VERSION "ICM"

NS_ :

BS_ :

BU_ : ICM Vector_XXX

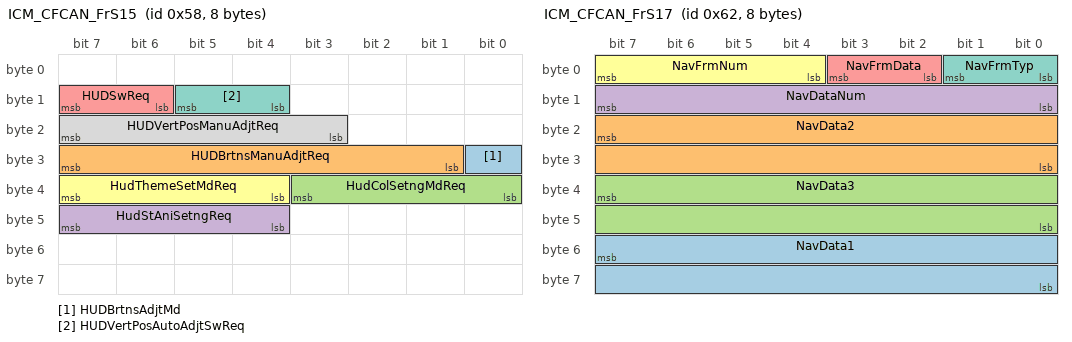
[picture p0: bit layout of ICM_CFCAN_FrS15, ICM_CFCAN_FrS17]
BO_ 88 ICM_CFCAN_FrS15 : 8 ICM
 SG_ HUDBrtnsAdjtMd : 24|1@0+ (1,0) [0|1] "" Vector_XXX
 SG_ HUDBrtnsManuAdjtReq : 31|7@0+ (1,0) [0|127] "" Vector_XXX
 SG_ HudColSetngMdReq : 35|4@0+ (1,0) [0|15] "" Vector_XXX
 SG_ HudStAniSetngReq : 47|4@0+ (1,0) [0|15] "" Vector_XXX
 SG_ HUDSwReq : 15|2@0+ (1,0) [0|3] "" Vector_XXX
 SG_ HudThemeSetMdReq : 39|4@0+ (1,0) [0|15] "" Vector_XXX
 SG_ HUDVertPosAutoAdjtSwReq : 13|2@0+ (1,0) [0|3] "" Vector_XXX
 SG_ HUDVertPosManuAdjtReq : 23|5@0+ (1,0) [0|31] "" Vector_XXX

BO_ 98 ICM_CFCAN_FrS17 : 8 ICM
 SG_ NavData1 : 55|16@0+ (1.0,0.0) [0.0|65535.0] "" Vector_XXX
 SG_ NavData2 : 23|16@0+ (1.0,0.0) [0.0|65535.0] "" Vector_XXX
 SG_ NavData3 : 39|16@0+ (1.0,0.0) [0.0|65535.0] "" Vector_XXX
 SG_ NavDataNum : 15|8@0+ (1,0) [0|255] "" Vector_XXX
 SG_ NavFrmData : 3|2@0+ (1,0) [0|3] "" Vector_XXX
 SG_ NavFrmNum : 7|4@0+ (1,0) [0|15] "" Vector_XXX
 SG_ NavFrmTyp : 1|2@0+ (1,0) [0|3] "" Vector_XXX

BO_ 1218 ICM_CFCAN_NM : 8 ICM
 SG_ NmPDU_CFCAN_ICM : 7|64@0+ (1,0) [0|0] "" Vector_XXX

BO_ 1142 IPK_CFCAN_FrP01 : 8 ICM
 SG_ VINClstr : 7|64@0+ (1,0) [0|18446744073709551615] "" Vector_XXX

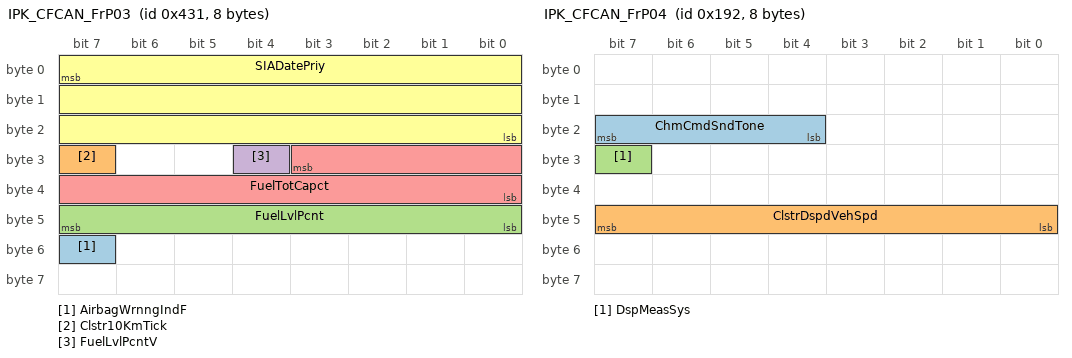
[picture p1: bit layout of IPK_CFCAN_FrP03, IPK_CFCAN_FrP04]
BO_ 1073 IPK_CFCAN_FrP03 : 8 ICM
 SG_ AirbagWrnngIndF : 55|1@0+ (1,0) [0|1] "" Vector_XXX
 SG_ Clstr10KmTick : 31|1@0+ (1,0) [0|1] "" Vector_XXX
 SG_ FuelLvlPcnt : 47|8@0+ (0.392157,0.0) [0.0|100.000035] "%" Vector_XXX
 SG_ FuelLvlPcntV : 28|1@0+ (1,0) [0|1] "" Vector_XXX
 SG_ FuelTotCapct : 27|12@0+ (0.125,0.0) [0.0|511.875] "liters" Vector_XXX
 SG_ SIADatePriy : 7|24@0+ (1.0,0.0) [0.0|0.0] "" Vector_XXX

BO_ 402 IPK_CFCAN_FrP04 : 8 ICM
 SG_ ChmCmdSndTone : 23|4@0+ (1,0) [0|15] "" Vector_XXX
 SG_ ClstrDspdVehSpd : 47|8@0+ (1.0,0.0) [0.0|254.0] "km/h" Vector_XXX
 SG_ DspMeasSys : 31|1@0+ (1,0) [0|1] "" Vector_XXX

BO_ 1134 IPK_CFCAN_FrP05 : 8 ICM
 SG_ OdoPriy : 23|24@0+ (1.0,0.0) [0.0|16777200.0] "km" Vector_XXX
 SG_ SIAOdoPriy : 47|24@0+ (1.0,0.0) [0.0|16777200.0] "km" Vector_XXX

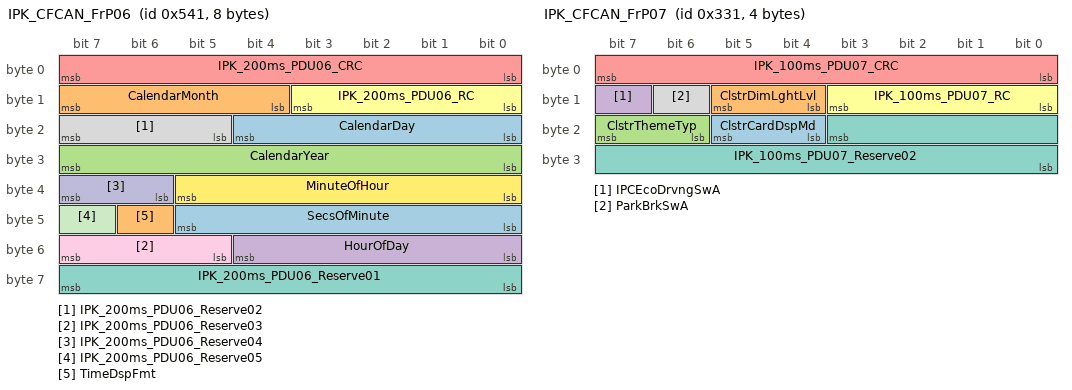
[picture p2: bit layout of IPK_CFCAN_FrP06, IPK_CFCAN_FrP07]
BO_ 1345 IPK_CFCAN_FrP06 : 8 ICM
 SG_ CalendarDay : 20|5@0+ (1.0,0.0) [0.0|31.0] "days" Vector_XXX
 SG_ CalendarMonth : 15|4@0+ (1,0) [0|15] "" Vector_XXX
 SG_ CalendarYear : 31|8@0+ (1.0,2000.0) [2000.0|2255.0] "year" Vector_XXX
 SG_ HourOfDay : 52|5@0+ (1.0,0.0) [0.0|23.0] "" Vector_XXX
 SG_ IPK_200ms_PDU06_CRC : 7|8@0+ (1.0,0.0) [0.0|255.0] "" Vector_XXX
 SG_ IPK_200ms_PDU06_RC : 11|4@0+ (1.0,0.0) [0.0|15.0] "" Vector_XXX
 SG_ IPK_200ms_PDU06_Reserve01 : 63|8@0+ (1,0) [0|255] "" Vector_XXX
 SG_ IPK_200ms_PDU06_Reserve02 : 23|3@0+ (1,0) [0|7] "" Vector_XXX
 SG_ IPK_200ms_PDU06_Reserve03 : 55|3@0+ (1,0) [0|7] "" Vector_XXX
 SG_ IPK_200ms_PDU06_Reserve04 : 39|2@0+ (1,0) [0|3] "" Vector_XXX
 SG_ IPK_200ms_PDU06_Reserve05 : 47|1@0+ (1,0) [0|1] "" Vector_XXX
 SG_ MinuteOfHour : 37|6@0+ (1.0,0.0) [0.0|59.0] "" Vector_XXX
 SG_ SecsOfMinute : 45|6@0+ (1.0,0.0) [0.0|59.0] "" Vector_XXX
 SG_ TimeDspFmt : 46|1@0+ (1,0) [0|1] "" Vector_XXX

BO_ 817 IPK_CFCAN_FrP07 : 4 ICM
 SG_ ClstrCardDspMd : 21|2@0+ (1,0) [0|3] "" Vector_XXX
 SG_ ClstrDimLghtLvl : 13|2@0+ (1,0) [0|3] "" Vector_XXX
 SG_ ClstrThemeTyp : 23|2@0+ (1,0) [0|3] "" Vector_XXX
 SG_ IPCEcoDrvngSwA : 15|1@0+ (1,0) [0|1] "" Vector_XXX
 SG_ IPK_100ms_PDU07_CRC : 7|8@0+ (1.0,0.0) [0.0|255.0] "" Vector_XXX
 SG_ IPK_100ms_PDU07_RC : 11|4@0+ (1.0,0.0) [0.0|15.0] "" Vector_XXX
 SG_ IPK_100ms_PDU07_Reserve02 : 19|12@0+ (1,0) [0|4095] "" Vector_XXX
 SG_ ParkBrkSwA : 14|1@0+ (1,0) [0|1] "" Vector_XXX

BO_ 874 IPK_CFCAN_FrP08 : 8 ICM
 SG_ RmnDrvngDist : 39|12@0+ (1.0,0.0) [0.0|4095.0] "km" Vector_XXX

BO_ 1047 IPK_CFCAN_FrP09 : 8 ICM
 SG_ ClstrDspdABSWrnng : 41|1@0+ (1,0) [0|1] "" Vector_XXX
 SG_ ClstrDspdACCSysWrnng : 6|1@0+ (1,0) [0|1] "" Vector_XXX
 SG_ ClstrDspdAdvFrtLghtngSysWrnng : 54|1@0+ (1,0) [0|1] "" Vector_XXX
 SG_ ClstrDspdAEBSysWrnng : 38|1@0+ (1,0) [0|1] "" Vector_XXX
 SG_ ClstrDspdAirbagWrnng : 27|1@0+ (1,0) [0|1] "" Vector_XXX
 SG_ ClstrDspdAltrWrnng : 36|1@0+ (1,0) [0|1] "" Vector_XXX
 SG_ ClstrDspdAutoholdWrnng : 2|1@0+ (1,0) [0|1] "" Vector_XXX
 SG_ ClstrDspdBatRplmntRqdWrnng : 18|1@0+ (1,0) [0|1] "" Vector_XXX
 SG_ ClstrDspdBrkSysWrnng : 43|1@0+ (1,0) [0|1] "" Vector_XXX
 SG_ ClstrDspdCCWrnng : 11|1@0+ (1,0) [0|1] "" Vector_XXX
 SG_ ClstrDspdClntTemWrnng : 42|1@0+ (1,0) [0|1] "" Vector_XXX
 SG_ ClstrDspdClSwWrnng : 30|1@0+ (1,0) [0|1] "" Vector_XXX
 SG_ ClstrDspdDayTimeRunningLampWrnng : 15|1@0+ (1,0) [0|1] "" Vector_XXX
 SG_ ClstrDspdEleccParkngBrkWrnng : 10|1@0+ (1,0) [0|1] "" Vector_XXX
 SG_ ClstrDspdEnDrvByWrWrnng : 9|1@0+ (1,0) [0|1] "" Vector_XXX
 SG_ ClstrDspdEPSWrnng : 57|2@0+ (1,0) [0|3] "" Vector_XXX
 SG_ ClstrDspdFuelSnsrWrnng : 47|1@0+ (1,0) [0|1] "" Vector_XXX
 SG_ ClstrDspdFVCMSnsrWrnng : 7|1@0+ (1,0) [0|1] "" Vector_XXX
 SG_ ClstrDspdHDCWrnng : 39|1@0+ (1,0) [0|1] "" Vector_XXX
 SG_ ClstrDspdHillHoldWrnng : 31|1@0+ (1,0) [0|1] "" Vector_XXX
 SG_ ClstrDspdIgnRelayWrnng : 16|1@0+ (1,0) [0|1] "" Vector_XXX
 SG_ ClstrDspdInvdKeyWrnng : 28|1@0+ (1,0) [0|1] "" Vector_XXX
 SG_ ClstrDspdLBrkLghtWrnng : 48|1@0+ (1,0) [0|1] "" Vector_XXX
 SG_ ClstrDspdLDipdBeamLghtWrnng : 52|1@0+ (1,0) [0|1] "" Vector_XXX
 SG_ ClstrDspdLDircnIndLghtWrnng : 50|1@0+ (1,0) [0|1] "" Vector_XXX
 SG_ ClstrDspdLDWSysFlt : 5|1@0+ (1,0) [0|1] "" Vector_XXX
 SG_ ClstrDspdLSideLghtWrnng : 13|1@0+ (1,0) [0|1] "" Vector_XXX
 SG_ ClstrDspdPEWrnng : 4|1@0+ (1,0) [0|1] "" Vector_XXX
 SG_ ClstrDspdRBrkLghtWrnng : 49|1@0+ (1,0) [0|1] "" Vector_XXX
 SG_ ClstrDspdRDipdBeamLghtWrnng : 53|1@0+ (1,0) [0|1] "" Vector_XXX
 SG_ ClstrDspdRDircnIndLghtWrnng : 51|1@0+ (1,0) [0|1] "" Vector_XXX
 SG_ ClstrDspdRevsLampWrnng : 1|1@0+ (1,0) [0|1] "" Vector_XXX
 SG_ ClstrDspdRrFogLghtWrnng : 0|1@0+ (1,0) [0|1] "" Vector_XXX
 SG_ ClstrDspdRSideLghtWrnng : 14|1@0+ (1,0) [0|1] "" Vector_XXX
 SG_ ClstrDspdSASUncalWrnng : 26|1@0+ (1,0) [0|1] "" Vector_XXX
 SG_ ClstrDspdSASWrnng : 25|1@0+ (1,0) [0|1] "" Vector_XXX
 SG_ ClstrDspdSCSWrnng : 55|1@0+ (1,0) [0|1] "" Vector_XXX
 SG_ ClstrDspdScurtKeyBatLowWrnng : 29|1@0+ (1,0) [0|1] "" Vector_XXX
 SG_ ClstrDspdSpdAstSysWrnng : 12|1@0+ (1,0) [0|1] "" Vector_XXX
 SG_ ClstrDspdSpStBtnWrnng : 33|1@0+ (1,0) [0|1] "" Vector_XXX
 SG_ ClstrDspdSpStWrnng : 32|1@0+ (1,0) [0|1] "" Vector_XXX
 SG_ ClstrDspdTCCMWrnng : 3|1@0+ (1,0) [0|1] "" Vector_XXX
 SG_ ClstrDspdTCSWrnng : 40|1@0+ (1,0) [0|1] "" Vector_XXX
 SG_ ClstrDspdTrWrnng : 22|1@0+ (1,0) [0|1] "" Vector_XXX
 SG_ ClstrDspdTyrePrsSts : 35|2@0+ (1,0) [0|3] "" Vector_XXX
 SG_ ClstrDspdWshrFludLowWrnng : 17|1@0+ (1,0) [0|1] "" Vector_XXX

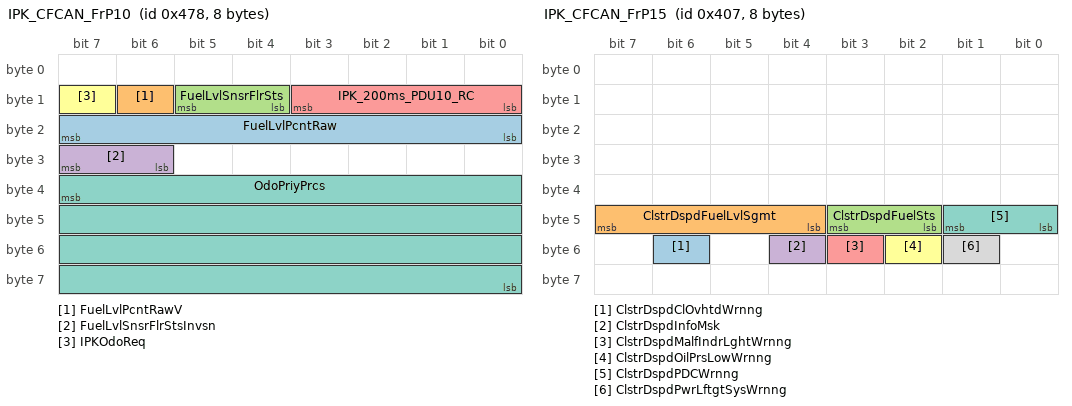
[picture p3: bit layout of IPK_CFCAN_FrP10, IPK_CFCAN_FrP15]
BO_ 1144 IPK_CFCAN_FrP10 : 8 ICM
 SG_ FuelLvlPcntRaw : 23|8@0+ (0.392157,0.0) [0.0|100.000035] "%" Vector_XXX
 SG_ FuelLvlPcntRawV : 14|1@0+ (1,0) [0|1] "" Vector_XXX
 SG_ FuelLvlSnsrFlrSts : 13|2@0+ (1,0) [0|3] "" Vector_XXX
 SG_ FuelLvlSnsrFlrStsInvsn : 31|2@0+ (1,0) [0|3] "" Vector_XXX
 SG_ IPK_200ms_PDU10_RC : 11|4@0+ (1.0,0.0) [0.0|15.0] "" Vector_XXX
 SG_ IPKOdoReq : 15|1@0+ (1,0) [0|1] "" Vector_XXX
 SG_ OdoPriyPrcs : 39|32@0+ (0.1,0.0) [0.0|429496729.5] "km" Vector_XXX

BO_ 1031 IPK_CFCAN_FrP15 : 8 ICM
 SG_ ClstrDspdClOvhtdWrnng : 54|1@0+ (1,0) [0|1] "" Vector_XXX
 SG_ ClstrDspdFuelLvlSgmt : 47|4@0+ (1.0,0.0) [9.0|15.0] "Reserved" Vector_XXX
 SG_ ClstrDspdFuelSts : 43|2@0+ (1,0) [0|3] "" Vector_XXX
 SG_ ClstrDspdInfoMsk : 52|1@0+ (1,0) [0|1] "" Vector_XXX
 SG_ ClstrDspdMalfIndrLghtWrnng : 51|1@0+ (1,0) [0|1] "" Vector_XXX
 SG_ ClstrDspdOilPrsLowWrnng : 50|1@0+ (1,0) [0|1] "" Vector_XXX
 SG_ ClstrDspdPDCWrnng : 41|2@0+ (1,0) [0|3] "" Vector_XXX
 SG_ ClstrDspdPwrLftgtSysWrnng : 49|1@0+ (1,0) [0|1] "" Vector_XXX

BO_ 1360 IPK_CFCAN_FrP17 : 8 ICM
 SG_ AvgFuelCsump : 7|8@0+ (0.1,0.0) [0.0|25.5] "L/100 km" Vector_XXX
 SG_ AvgFuelCsumpV : 8|1@0+ (1,0) [0|1] "" Vector_XXX
 SG_ ClstrFuelRngToEPT : 23|10@0+ (1.0,0.0) [0.0|1023.0] "" Vector_XXX

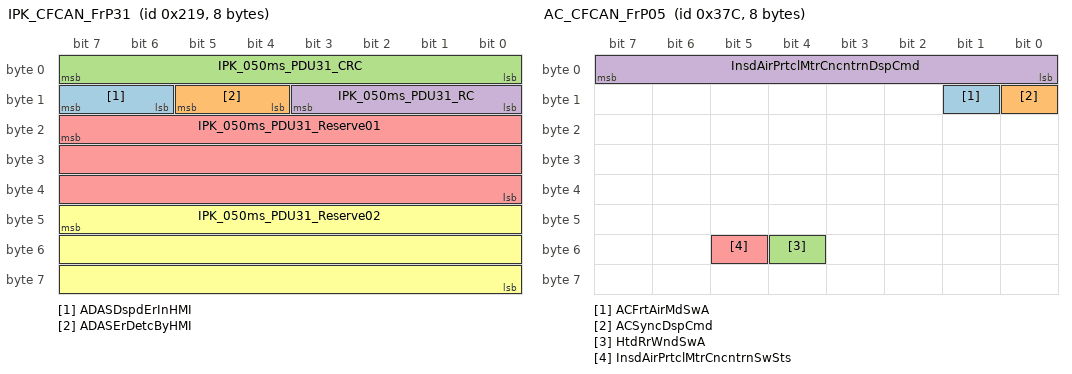
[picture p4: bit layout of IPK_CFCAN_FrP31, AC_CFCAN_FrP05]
BO_ 537 IPK_CFCAN_FrP31 : 8 ICM
 SG_ ADASDspdErInHMI : 15|2@0+ (1,0) [0|3] "" Vector_XXX
 SG_ ADASErDetcByHMI : 13|2@0+ (1,0) [0|3] "" Vector_XXX
 SG_ IPK_050ms_PDU31_CRC : 7|8@0+ (1.0,0.0) [0.0|255.0] "" Vector_XXX
 SG_ IPK_050ms_PDU31_RC : 11|4@0+ (1.0,0.0) [0.0|15.0] "" Vector_XXX
 SG_ IPK_050ms_PDU31_Reserve01 : 23|24@0+ (1,0) [0|16777215] "" Vector_XXX
 SG_ IPK_050ms_PDU31_Reserve02 : 47|24@0+ (1,0) [0|16777215] "" Vector_XXX

BO_ 672 AC_CFCAN_FrP04 : 8 Vector_XXX
 SG_ RrACAutoDspCmd : 19|1@0+ (1,0) [0|1] "" ICM
 SG_ RrACOnOffDspCmd : 17|1@0+ (1,0) [0|1] "" ICM

BO_ 892 AC_CFCAN_FrP05 : 8 Vector_XXX
 SG_ ACFrtAirMdSwA : 9|1@0+ (1,0) [0|1] "" ICM
 SG_ ACSyncDspCmd : 8|1@0+ (1,0) [0|1] "" ICM
 SG_ HtdRrWndSwA : 52|1@0+ (1,0) [0|1] "" ICM
 SG_ InsdAirPrtclMtrCncntrnDspCmd : 7|8@0+ (2.0,0.0) [0.0|500.0] "ug/m3" ICM
 SG_ InsdAirPrtclMtrCncntrnSwSts : 53|1@0+ (1,0) [0|1] "" ICM

BO_ 893 AC_CFCAN_FrP06 : 8 Vector_XXX
 SG_ ACFltrCsumLvlDspCmd : 39|2@0+ (1,0) [0|3] "" ICM
 SG_ ACUserCustAftRunOnOffDspCmd : 7|2@0+ (1,0) [0|3] "" ICM
 SG_ ACUserCustAirQultEnbDspCmd : 5|2@0+ (1,0) [0|3] "" ICM
 SG_ ACUserCustAutoMdBlwrDspCmd : 3|2@0+ (1,0) [0|3] "" ICM
 SG_ ACUserCustAutoMdTemDspCmd : 1|2@0+ (1,0) [0|3] "" ICM
 SG_ ACUserCustBlwrAutoRunRmtUnlckDspCmd : 15|2@0+ (1,0) [0|3] "" ICM
 SG_ ACUserCustCofignDspCmd : 13|3@0+ (1,0) [0|7] "" ICM
 SG_ ACUserCustEcoSetngDspCmd : 41|2@0+ (1,0) [0|3] "" ICM
 SG_ ACUserCustFltrLifeRmndDspCmd : 9|2@0+ (1,0) [0|3] "" ICM
 SG_ ACUserCustFrtAutoDmstngDspCmd : 23|2@0+ (1,0) [0|3] "" ICM
 SG_ ACUserCustRmtStOnOffDspCmd : 21|2@0+ (1,0) [0|3] "" ICM
 SG_ ACUserCustRrAutoDmstngDspCmd : 19|2@0+ (1,0) [0|3] "" ICM
 SG_ ACUserCustRrZoneCofignDspCmd : 17|2@0+ (1,0) [0|3] "" ICM
 SG_ ACUserCustSetngDspCmd : 25|2@0+ (1,0) [0|3] "" ICM
 SG_ ACUserCustStSpMdDspCmd : 31|2@0+ (1,0) [0|3] "" ICM
 SG_ ACUserCustTemUnitDspCmd : 29|2@0+ (1,0) [0|3] "" ICM
 SG_ ACUserCustZoneCofignDspCmd : 27|2@0+ (1,0) [0|3] "" ICM
 SG_ AirClnrAutoDspCmd : 55|1@0+ (1,0) [0|1] "" ICM
 SG_ AirClnrBlwrLvlDspCmd : 54|3@0+ (1,0) [0|7] "" ICM
 SG_ AirClnrBlwrSpdSwA : 10|1@0+ (1,0) [0|1] "" ICM
 SG_ AirClnrIonizerDspCmd : 46|1@0+ (1,0) [0|1] "" ICM
 SG_ AirClnrOnOffDspCmd : 47|1@0+ (1,0) [0|1] "" ICM
 SG_ AirClnrUserCustAutoRDC : 45|2@0+ (1,0) [0|3] "" ICM

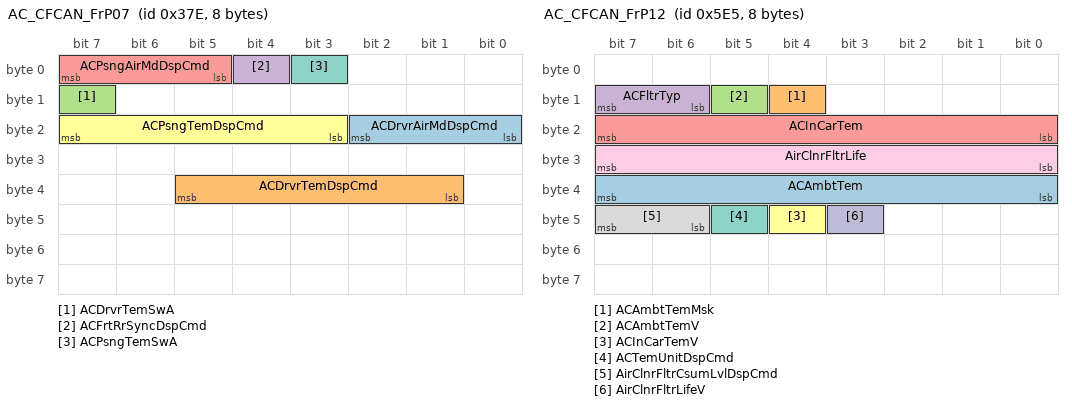
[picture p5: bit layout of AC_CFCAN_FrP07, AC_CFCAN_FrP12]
BO_ 894 AC_CFCAN_FrP07 : 8 Vector_XXX
 SG_ ACDrvrAirMdDspCmd : 18|3@0+ (1,0) [0|7] "" ICM
 SG_ ACDrvrTemDspCmd : 37|5@0+ (0.5,15.5) [16.0|30.0] "degC" ICM
 SG_ ACDrvrTemSwA : 15|1@0+ (1,0) [0|1] "" ICM
 SG_ ACFrtRrSyncDspCmd : 4|1@0+ (1,0) [0|1] "" ICM
 SG_ ACPsngAirMdDspCmd : 7|3@0+ (1,0) [0|7] "" ICM
 SG_ ACPsngTemDspCmd : 23|5@0+ (0.5,17.5) [18.0|32.0] "deg C" ICM
 SG_ ACPsngTemSwA : 3|1@0+ (1,0) [0|1] "" ICM

BO_ 936 AC_CFCAN_FrP10 : 8 Vector_XXX
 SG_ ACAutoDspCmd : 54|1@0+ (1,0) [0|1] "" ICM
 SG_ ACAutoSwA : 56|1@0+ (1,0) [0|1] "" ICM
 SG_ ACDualDspCmd : 53|1@0+ (1,0) [0|1] "" ICM
 SG_ ACEcoDspCmd : 51|1@0+ (1,0) [0|1] "" ICM
 SG_ ACFrtBlwrSpdDspCmd : 31|4@0+ (1,0) [0|15] "" ICM
 SG_ ACFrtBlwrSpdSwA : 48|1@0+ (1,0) [0|1] "" ICM
 SG_ ACFrtPnlLckRrPnlDspCmd : 44|1@0+ (1,0) [0|1] "" ICM
 SG_ ACIonizerDspCmd : 52|1@0+ (1,0) [0|1] "" ICM
 SG_ ACLAirMdDspCmd : 10|3@0+ (1,0) [0|7] "" ICM
 SG_ ACLTemDspCmd : 15|5@0+ (0.5,17.5) [18.0|32.0] "deg C" ICM
 SG_ ACLTemSwA : 62|1@0+ (1,0) [0|1] "" ICM
 SG_ ACOnOffDspCmd : 43|1@0+ (1,0) [0|1] "" ICM
 SG_ ACRAirMdDspCmd : 2|3@0+ (1,0) [0|7] "" ICM
 SG_ ACRcctnDspMd : 47|2@0+ (1,0) [0|3] "" ICM
 SG_ ACRrAirMdDspCmd : 18|3@0+ (1,0) [0|7] "" ICM
 SG_ ACRrAutoSwA : 45|1@0+ (1,0) [0|1] "" ICM
 SG_ ACRrBlwrDspCmd : 27|4@0+ (1,0) [0|15] "" ICM
 SG_ ACRrBlwrLvlDspCmd : 60|4@0+ (1,0) [0|15] "" ICM
 SG_ ACRrBlwrSpdSwA : 49|1@0+ (1,0) [0|1] "" ICM
 SG_ ACRrTemDspCmd : 23|5@0+ (0.5,17.5) [18.0|32.0] "deg C" ICM
 SG_ ACRrTemSwA : 50|1@0+ (1,0) [0|1] "" ICM
 SG_ ACRTemDspCmd : 7|5@0+ (0.5,17.5) [18.0|32.0] "deg C" ICM
 SG_ ACRTemSwA : 63|1@0+ (1,0) [0|1] "" ICM
 SG_ ClmOnOffDspCmd : 61|1@0+ (1,0) [0|1] "" ICM
 SG_ ComprOnOffDspCmd : 42|1@0+ (1,0) [0|1] "" ICM
 SG_ DfstOnDspCmd : 40|1@0+ (1,0) [0|1] "" ICM
 SG_ FLSeatHeatDspCmd : 39|2@0+ (1,0) [0|3] "" ICM
 SG_ FLSeatVentDspCmd : 35|2@0+ (1,0) [0|3] "" ICM
 SG_ FRSeatHeatDspCmd : 37|2@0+ (1,0) [0|3] "" ICM
 SG_ FRSeatVentDspCmd : 33|2@0+ (1,0) [0|3] "" ICM
 SG_ HtdRrWndOnDspCmd : 41|1@0+ (1,0) [0|1] "" ICM

BO_ 1361 AC_CFCAN_FrP11 : 8 Vector_XXX
 SG_ OtsdAirPrtclMtrCncntrnDspCmd : 23|8@0+ (2.0,0.0) [0.0|500.0] "ug/m3" ICM
 SG_ OtsdAirQultSts : 47|1@0+ (1,0) [0|1] "" ICM
 SG_ OtsdAirQultStsV : 45|1@0+ (1,0) [0|1] "" ICM

BO_ 1509 AC_CFCAN_FrP12 : 8 Vector_XXX
 SG_ ACAmbtTem : 39|8@0+ (0.5,-40.0) [-40.0|87.5] "deg C" ICM
 SG_ ACAmbtTemMsk : 12|1@0+ (1,0) [0|1] "" ICM
 SG_ ACAmbtTemV : 13|1@0+ (1,0) [0|1] "" ICM
 SG_ ACFltrTyp : 15|2@0+ (1,0) [0|3] "" ICM
 SG_ ACInCarTem : 23|8@0+ (0.5,-40.0) [-40.0|86.5] "deg C " ICM
 SG_ ACInCarTemV : 44|1@0+ (1,0) [0|1] "" ICM
 SG_ ACTemUnitDspCmd : 45|1@0+ (1,0) [0|1] "" ICM
 SG_ AirClnrFltrCsumLvlDspCmd : 47|2@0+ (1,0) [0|3] "" ICM
 SG_ AirClnrFltrLife : 31|8@0+ (3.0,0.0) [0.0|765.0] "hour" ICM
 SG_ AirClnrFltrLifeV : 43|1@0+ (1,0) [0|1] "" ICM

BO_ 993 AC_CFCAN_FrP14 : 8 Vector_XXX
 SG_ OtsdAirPrtclMtrCDC : 63|8@0+ (2.0,0.0) [0.0|500.0] "ug/m3" ICM

BO_ 837 AMP_CFCAN_FrP01 : 8 Vector_XXX
 SG_ AMPWorkSta : 15|1@0+ (1,0) [0|1] "" ICM

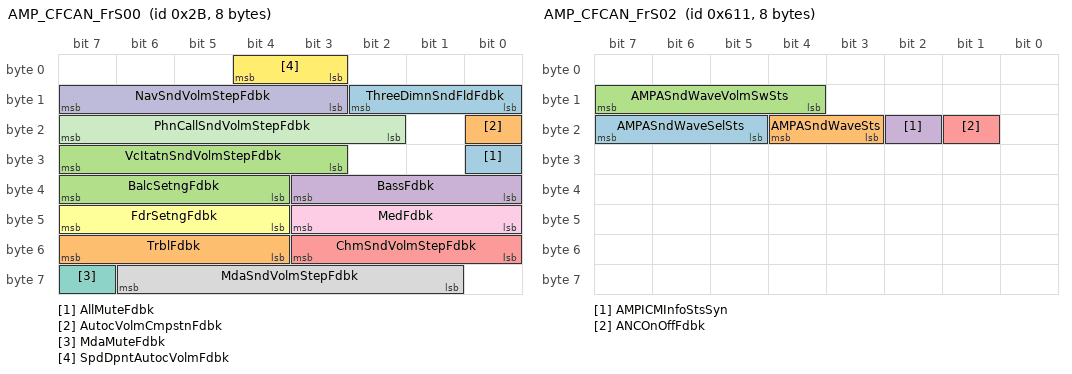
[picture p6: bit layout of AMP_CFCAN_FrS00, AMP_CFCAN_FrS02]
BO_ 43 AMP_CFCAN_FrS00 : 8 Vector_XXX
 SG_ AllMuteFdbk : 24|1@0+ (1,0) [0|1] "" ICM
 SG_ AutocVolmCmpstnFdbk : 16|1@0+ (1,0) [0|1] "" ICM
 SG_ BalcSetngFdbk : 39|4@0+ (1,0) [0|15] "" ICM
 SG_ BassFdbk : 35|4@0+ (1,0) [0|15] "" ICM
 SG_ ChmSndVolmStepFdbk : 51|4@0+ (1,0) [0|15] "" ICM
 SG_ FdrSetngFdbk : 47|4@0+ (1,0) [0|15] "" ICM
 SG_ MdaMuteFdbk : 63|1@0+ (1,0) [0|1] "" ICM
 SG_ MdaSndVolmStepFdbk : 62|6@0+ (1,0) [0|63] "" ICM
 SG_ MedFdbk : 43|4@0+ (1,0) [0|15] "" ICM
 SG_ NavSndVolmStepFdbk : 15|5@0+ (1,0) [0|31] "" ICM
 SG_ PhnCallSndVolmStepFdbk : 23|6@0+ (1,0) [0|63] "" ICM
 SG_ SpdDpntAutocVolmFdbk : 4|2@0+ (1,0) [0|3] "" ICM
 SG_ ThreeDimnSndFldFdbk : 10|3@0+ (1,0) [0|7] "" ICM
 SG_ TrblFdbk : 55|4@0+ (1,0) [0|15] "" ICM
 SG_ VcItatnSndVolmStepFdbk : 31|5@0+ (1,0) [0|31] "" ICM

BO_ 1553 AMP_CFCAN_FrS02 : 8 Vector_XXX
 SG_ AMPASndWaveSelSts : 23|3@0+ (1,0) [0|7] "" ICM
 SG_ AMPASndWaveSts : 20|2@0+ (1,0) [0|3] "" ICM
 SG_ AMPASndWaveVolmSwSts : 15|4@0+ (1,0) [0|15] "" ICM
 SG_ AMPICMInfoStsSyn : 18|1@0+ (1,0) [0|1] "" ICM
 SG_ ANCOnOffFdbk : 17|1@0+ (1,0) [0|1] "" ICM

BO_ 521 AVM_CFCAN_FrP01 : 8 Vector_XXX
 SG_ LCLWSysWrnng : 5|2@0+ (1,0) [0|3] "" ICM
 SG_ RCLWSysWrnng : 1|2@0+ (1,0) [0|3] "" ICM

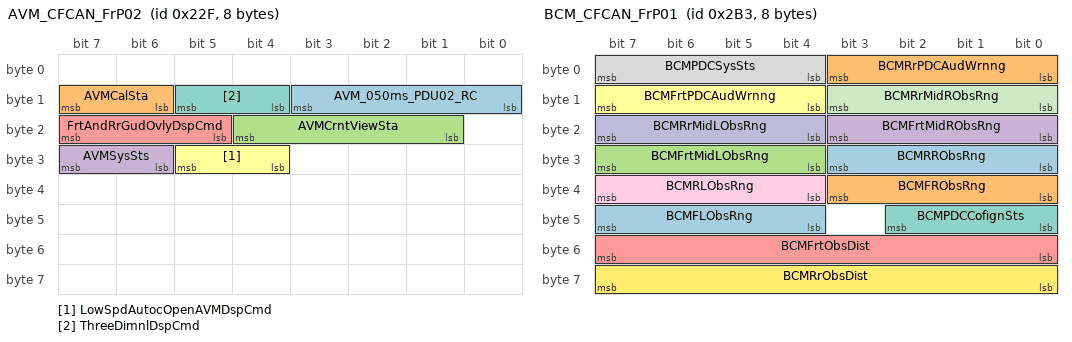
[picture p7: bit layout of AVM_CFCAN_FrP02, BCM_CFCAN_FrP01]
BO_ 559 AVM_CFCAN_FrP02 : 8 Vector_XXX
 SG_ AVM_050ms_PDU02_RC : 11|4@0+ (1.0,0.0) [0.0|15.0] "" ICM
 SG_ AVMCalSta : 15|2@0+ (1,0) [0|3] "" ICM
 SG_ AVMCrntViewSta : 20|4@0+ (1,0) [0|15] "" ICM
 SG_ AVMSysSts : 31|2@0+ (1,0) [0|3] "" ICM
 SG_ FrtAndRrGudOvlyDspCmd : 23|3@0+ (1,0) [0|7] "" ICM
 SG_ LowSpdAutocOpenAVMDspCmd : 29|2@0+ (1,0) [0|3] "" ICM
 SG_ ThreeDimnlDspCmd : 13|2@0+ (1,0) [0|3] "" ICM

BO_ 909 AVM_CFCAN_FrP03 : 8 Vector_XXX
 SG_ AVMCalMdReqResp : 55|3@0+ (1,0) [0|7] "" ICM
 SG_ AVMDspReq : 41|2@0+ (1,0) [0|3] "" ICM
 SG_ AVMDspSwReqResp : 52|2@0+ (1,0) [0|3] "" ICM
 SG_ CBDActvdSpdSetngVal : 7|4@0+ (10.0,0.0) [30.0|100.0] "km/h" ICM
 SG_ CBDSysSelSts : 11|2@0+ (1,0) [0|3] "" ICM
 SG_ CBDSysSts : 9|2@0+ (1,0) [0|3] "" ICM
 SG_ CIASetSwReqResp : 23|2@0+ (1,0) [0|3] "" ICM
 SG_ CIASysSelSts : 21|2@0+ (1,0) [0|3] "" ICM
 SG_ CIASysSysSts : 19|2@0+ (1,0) [0|3] "" ICM
 SG_ CLAWrnngSndSwSetngSts : 29|2@0+ (1,0) [0|3] "" ICM
 SG_ CLWActdSpdSetngVal : 3|4@0+ (10.0,0.0) [30.0|100.0] "km/h" ICM
 SG_ CLWSysSelSts : 17|2@0+ (1,0) [0|3] "" ICM
 SG_ CLWSysSts : 31|2@0+ (1,0) [0|3] "" ICM
 SG_ RrViewInfoAstntActvdSpdSetngVal : 15|4@0+ (10.0,0.0) [30.0|100.0] "km/h" ICM
 SG_ RrViewInfoAstntSysA : 27|2@0+ (1,0) [0|3] "" ICM
 SG_ RrViewInfoAstntSysSelSts : 25|2@0+ (1,0) [0|3] "" ICM
 SG_ RrViewInfoAstntSysSts : 39|2@0+ (1,0) [0|3] "" ICM
 SG_ VehBodyColorDspCmd : 37|4@0+ (1,0) [0|15] "" ICM

BO_ 691 BCM_CFCAN_FrP01 : 8 Vector_XXX
 SG_ BCMFLObsRng : 47|4@0+ (1,0) [0|15] "" ICM
 SG_ BCMFRObsRng : 35|4@0+ (1,0) [0|15] "" ICM
 SG_ BCMFrtMidLObsRng : 31|4@0+ (1,0) [0|15] "" ICM
 SG_ BCMFrtMidRObsRng : 19|4@0+ (1,0) [0|15] "" ICM
 SG_ BCMFrtObsDist : 55|8@0+ (1.0,0.0) [0.0|255.0] "cm" ICM
 SG_ BCMFrtPDCAudWrnng : 15|4@0+ (1,0) [0|15] "" ICM
 SG_ BCMPDCCofignSts : 42|3@0+ (1,0) [0|7] "" ICM
 SG_ BCMPDCSysSts : 7|4@0+ (1,0) [0|15] "" ICM
 SG_ BCMRLObsRng : 39|4@0+ (1,0) [0|15] "" ICM
 SG_ BCMRrMidLObsRng : 23|4@0+ (1,0) [0|15] "" ICM
 SG_ BCMRrMidRObsRng : 11|4@0+ (1,0) [0|15] "" ICM
 SG_ BCMRrObsDist : 63|8@0+ (1.0,0.0) [0.0|255.0] "" ICM
 SG_ BCMRRObsRng : 27|4@0+ (1,0) [0|15] "" ICM
 SG_ BCMRrPDCAudWrnng : 3|4@0+ (1,0) [0|15] "" ICM

BO_ 822 BCM_CFCAN_FrP03 : 8 Vector_XXX
 SG_ BCMFLSeatHeatLvl : 54|2@0+ (1,0) [0|3] "" ICM
 SG_ BCMFRSeatHeatLvl : 52|2@0+ (1,0) [0|3] "" ICM
 SG_ DrvrPWLInitnRmndr : 3|1@0+ (1,0) [0|1] "" ICM
 SG_ DrvrWndDclnSpc : 23|8@0+ (0.5,0.0) [0.0|100.0] "%" ICM
 SG_ DrvrWndOpenRmndr : 2|1@0+ (1,0) [0|1] "" ICM
 SG_ FrtPsngPWLInitnRmndr : 7|1@0+ (1,0) [0|1] "" ICM
 SG_ FrtPsngWndDclnSpc : 39|8@0+ (1.0,0.0) [201.0|204.0] "fault" ICM
 SG_ FrtPsngWndOpenRmndr : 1|1@0+ (1,0) [0|1] "" ICM
 SG_ OtsdMirFoldSts : 11|2@0+ (1,0) [0|3] "" ICM
 SG_ RLPWLInitnRmndr : 8|1@0+ (1,0) [0|1] "" ICM
 SG_ RLWndDclnSpc : 31|8@0+ (0.5,0.0) [0.0|127.0] "%" ICM
 SG_ RLWndOpenRmndr : 5|1@0+ (1,0) [0|1] "" ICM
 SG_ RRPWLInitnRmndr : 9|1@0+ (1,0) [0|1] "" ICM
 SG_ RRWndDclnSpc : 47|8@0+ (0.5,0.0) [0.0|127.0] "%" ICM
 SG_ RRWndOpenRmndr : 4|1@0+ (1,0) [0|1] "" ICM
 SG_ SrfInitnRmndr : 6|1@0+ (1,0) [0|1] "" ICM
 SG_ SrfOpenRmndr : 0|1@0+ (1,0) [0|1] "" ICM
 SG_ SrfSlidePosSts : 15|4@0+ (10.0,0.0) [0.0|150.0] "%" ICM
 SG_ SrfTiltSts : 55|1@0+ (1,0) [0|1] "" ICM

BO_ 815 BCM_CFCAN_FrP04 : 8 Vector_XXX
 SG_ BntOpenSts : 21|2@0+ (1,0) [0|3] "" ICM
 SG_ DrvrDoorOpenSts : 15|2@0+ (1,0) [0|3] "" ICM
 SG_ FrtPsngDoorOpenSts : 13|2@0+ (1,0) [0|3] "" ICM
 SG_ FrtWiperMdSts : 47|3@0+ (1,0) [0|7] "" ICM
 SG_ FrtWiperOpReq : 44|3@0+ (1,0) [0|7] "" ICM
 SG_ FrtWiperSwSts : 17|2@0+ (1,0) [0|3] "" ICM
 SG_ FrtWshrPumpA : 40|1@0+ (1,0) [0|1] "" ICM
 SG_ LdspcOpenSts : 23|2@0+ (1,0) [0|3] "" ICM
 SG_ LowWiperWshrFludLvlSwA : 55|1@0+ (1,0) [0|1] "" ICM
 SG_ RLDoorOpenSts : 51|2@0+ (1,0) [0|3] "" ICM
 SG_ RRDoorOpenSts : 49|2@0+ (1,0) [0|3] "" ICM
 SG_ RrDoorsOpenSts : 63|2@0+ (1,0) [0|3] "" ICM
 SG_ RrWiperMdSts : 53|2@0+ (1,0) [0|3] "" ICM
 SG_ RrWshrPumpA : 54|1@0+ (1,0) [0|1] "" ICM
 SG_ ScurtAlrmSts : 61|3@0+ (1,0) [0|7] "" ICM
 SG_ ScurtAlrmTrigd : 19|1@0+ (1,0) [0|1] "" ICM
 SG_ VehLckngSta : 58|3@0+ (1,0) [0|7] "" ICM

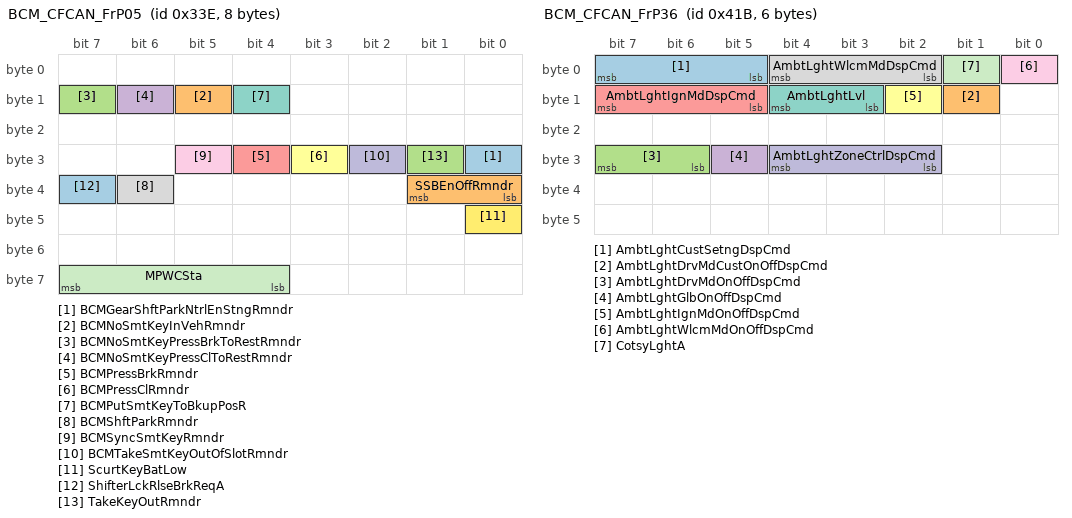
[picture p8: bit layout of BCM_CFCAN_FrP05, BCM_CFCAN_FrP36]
BO_ 830 BCM_CFCAN_FrP05 : 8 Vector_XXX
 SG_ BCMGearShftParkNtrlEnStngRmndr : 24|1@0+ (1,0) [0|1] "" ICM
 SG_ BCMNoSmtKeyInVehRmndr : 13|1@0+ (1,0) [0|1] "" ICM
 SG_ BCMNoSmtKeyPressBrkToRestRmndr : 15|1@0+ (1,0) [0|1] "" ICM
 SG_ BCMNoSmtKeyPressClToRestRmndr : 14|1@0+ (1,0) [0|1] "" ICM
 SG_ BCMPressBrkRmndr : 28|1@0+ (1,0) [0|1] "" ICM
 SG_ BCMPressClRmndr : 27|1@0+ (1,0) [0|1] "" ICM
 SG_ BCMPutSmtKeyToBkupPosR : 12|1@0+ (1,0) [0|1] "" ICM
 SG_ BCMShftParkRmndr : 38|1@0+ (1,0) [0|1] "" ICM
 SG_ BCMSyncSmtKeyRmndr : 29|1@0+ (1,0) [0|1] "" ICM
 SG_ BCMTakeSmtKeyOutOfSlotRmndr : 26|1@0+ (1,0) [0|1] "" ICM
 SG_ MPWCSta : 63|4@0+ (1,0) [0|15] "" ICM
 SG_ ScurtKeyBatLow : 40|1@0+ (1,0) [0|1] "" ICM
 SG_ ShifterLckRlseBrkReqA : 39|1@0+ (1,0) [0|1] "" ICM
 SG_ SSBEnOffRmndr : 33|2@0+ (1,0) [0|3] "" ICM
 SG_ TakeKeyOutRmndr : 25|1@0+ (1,0) [0|1] "" ICM

BO_ 804 BCM_CFCAN_FrP08 : 8 Vector_XXX
 SG_ AutocLghtIndReq : 7|2@0+ (1,0) [0|3] "" ICM
 SG_ AutoMainBeamLghtOn : 5|1@0+ (1,0) [0|1] "" ICM
 SG_ CHMSLF : 46|1@0+ (1,0) [0|1] "" ICM
 SG_ DayTimeRunningLampOn : 3|1@0+ (1,0) [0|1] "" ICM
 SG_ DayTimeRunningLghtF : 2|1@0+ (1,0) [0|1] "" ICM
 SG_ DimLghtLvl : 15|8@0+ (0.4,0.0) [0.0|100.0] "%" ICM
 SG_ DipdBeamLghtOn : 1|1@0+ (1,0) [0|1] "" ICM
 SG_ DircnIndLampSwSts : 23|2@0+ (1,0) [0|3] "" ICM
 SG_ FrtFogLghtOn : 0|1@0+ (1,0) [0|1] "" ICM
 SG_ FrtSideLghtF : 21|1@0+ (1,0) [0|1] "" ICM
 SG_ LBrkLghtF : 31|1@0+ (1,0) [0|1] "" ICM
 SG_ LDipdBeamLghtF : 30|1@0+ (1,0) [0|1] "" ICM
 SG_ LDircnIndLghtF : 29|1@0+ (1,0) [0|1] "" ICM
 SG_ LghtSwDimPos : 39|8@0+ (0.4,0.0) [0.0|102.0] "" ICM
 SG_ LghtSwPosSts : 20|3@0+ (1,0) [0|7] "" ICM
 SG_ LSideLghtF : 28|1@0+ (1,0) [0|1] "" ICM
 SG_ MainBeamLghtOn : 17|1@0+ (1,0) [0|1] "" ICM
 SG_ RBrkLghtF : 27|1@0+ (1,0) [0|1] "" ICM
 SG_ RDipdBeamLghtF : 26|1@0+ (1,0) [0|1] "" ICM
 SG_ RDircnIndLghtF : 25|1@0+ (1,0) [0|1] "" ICM
 SG_ RevsLghtF : 24|1@0+ (1,0) [0|1] "" ICM
 SG_ RgstnPltLghtF : 47|1@0+ (1,0) [0|1] "" ICM
 SG_ RrFogLghtF : 41|1@0+ (1,0) [0|1] "" ICM
 SG_ RrFogLghtOn : 45|1@0+ (1,0) [0|1] "" ICM
 SG_ RrSideLghtF : 16|1@0+ (1,0) [0|1] "" ICM
 SG_ RSideLghtF : 44|1@0+ (1,0) [0|1] "" ICM
 SG_ VehSideLghtSts : 43|2@0+ (1,0) [0|3] "" ICM

BO_ 1125 BCM_CFCAN_FrP09 : 8 Vector_XXX
 SG_ BCMCofignSts : 7|64@0+ (1,0) [0|18446744073709551615] "" ICM

BO_ 1136 BCM_CFCAN_FrP10 : 8 Vector_XXX
 SG_ BCMCofignSts2 : 7|64@0+ (1,0) [0|18446744073709551615] "" ICM

BO_ 1040 BCM_CFCAN_FrP11 : 8 Vector_XXX
 SG_ BCMCofignSts3 : 7|64@0+ (1,0) [0|18446744073709551615] "" ICM

BO_ 1139 BCM_CFCAN_FrP12 : 8 Vector_XXX
 SG_ VINBCM : 7|64@0+ (1,0) [0|18446744073709551615] "" ICM

BO_ 1127 BCM_CFCAN_FrP13 : 8 Vector_XXX
 SG_ BCMOdoReq : 55|1@0+ (1,0) [0|1] "" ICM
 SG_ OdoSecy : 31|24@0+ (1.0,0.0) [0.0|16777200.0] "km" ICM
 SG_ SIAOdoSecy : 7|24@0+ (1.0,0.0) [0.0|16777200.0] "km" ICM

BO_ 1051 BCM_CFCAN_FrP36 : 6 Vector_XXX
 SG_ AmbtLghtCustSetngDspCmd : 7|3@0+ (1,0) [0|7] "" ICM
 SG_ AmbtLghtDrvMdCustOnOffDspCmd : 9|1@0+ (1,0) [0|1] "" ICM
 SG_ AmbtLghtDrvMdOnOffDspCmd : 31|2@0+ (1,0) [0|3] "" ICM
 SG_ AmbtLghtGlbOnOffDspCmd : 29|1@0+ (1,0) [0|1] "" ICM
 SG_ AmbtLghtIgnMdDspCmd : 15|3@0+ (1,0) [0|7] "" ICM
 SG_ AmbtLghtIgnMdOnOffDspCmd : 10|1@0+ (1,0) [0|1] "" ICM
 SG_ AmbtLghtLvl : 12|2@0+ (1,0) [0|3] "" ICM
 SG_ AmbtLghtWlcmMdDspCmd : 4|3@0+ (1,0) [0|7] "" ICM
 SG_ AmbtLghtWlcmMdOnOffDspCmd : 0|1@0+ (1,0) [0|1] "" ICM
 SG_ AmbtLghtZoneCtrlDspCmd : 28|3@0+ (1,0) [0|7] "" ICM
 SG_ CotsyLghtA : 1|1@0+ (1,0) [0|1] "" ICM

BO_ 937 BCM_CFCAN_FrP37 : 8 Vector_XXX
 SG_ AmbtLghtDrvMdCustDspCmd : 7|64@0+ (1,0) [0|18446744073709551615] "" ICM

BO_ 938 BCM_CFCAN_FrP38 : 8 Vector_XXX
 SG_ AmbtLghtDrvMdCustDspCmd1 : 7|64@0+ (1,0) [0|18446744073709551615] "" ICM

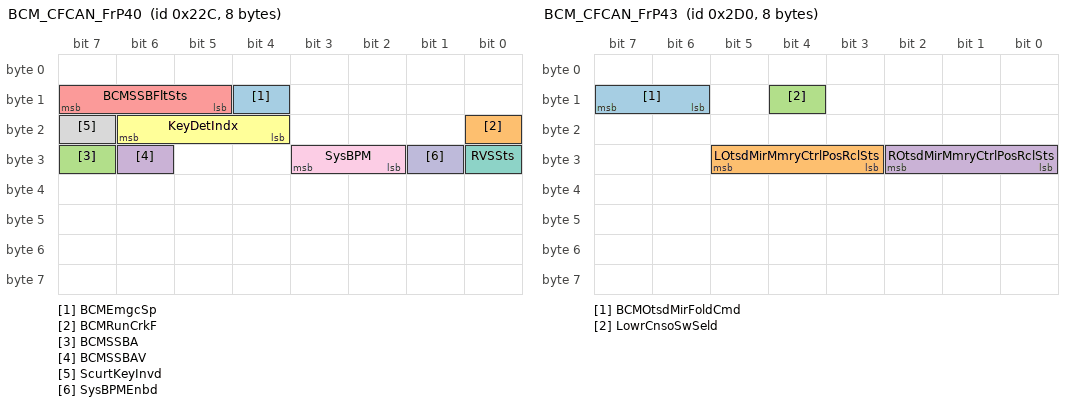
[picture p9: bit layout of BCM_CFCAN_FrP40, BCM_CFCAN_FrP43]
BO_ 556 BCM_CFCAN_FrP40 : 8 Vector_XXX
 SG_ BCMEmgcSp : 12|1@0+ (1,0) [0|1] "" ICM
 SG_ BCMRunCrkF : 16|1@0+ (1,0) [0|1] "" ICM
 SG_ BCMSSBA : 31|1@0+ (1,0) [0|1] "" ICM
 SG_ BCMSSBAV : 30|1@0+ (1,0) [0|1] "" ICM
 SG_ BCMSSBFltSts : 15|3@0+ (1,0) [0|7] "" ICM
 SG_ KeyDetIndx : 22|3@0+ (1,0) [0|7] "" ICM
 SG_ RVSSts : 24|1@0+ (1,0) [0|1] "" ICM
 SG_ ScurtKeyInvd : 23|1@0+ (1,0) [0|1] "" ICM
 SG_ SysBPM : 27|2@0+ (1,0) [0|3] "" ICM
 SG_ SysBPMEnbd : 25|1@0+ (1,0) [0|1] "" ICM

BO_ 1052 BCM_CFCAN_FrP41 : 8 Vector_XXX
 SG_ SIADateSecy : 7|24@0+ (1.0,0.0) [0.0|0.0] "" ICM

BO_ 135 BCM_CFCAN_FrP42 : 8 Vector_XXX
 SG_ LDircnIO : 39|1@0+ (1,0) [0|1] "" ICM
 SG_ RDircnIO : 38|1@0+ (1,0) [0|1] "" ICM

BO_ 720 BCM_CFCAN_FrP43 : 8 Vector_XXX
 SG_ BCMOtsdMirFoldCmd : 15|2@0+ (1,0) [0|3] "" ICM
 SG_ LOtsdMirMmryCtrlPosRclSts : 29|3@0+ (1,0) [0|7] "" ICM
 SG_ LowrCnsoSwSeld : 12|1@0+ (1,0) [0|1] "" ICM
 SG_ ROtsdMirMmryCtrlPosRclSts : 26|3@0+ (1,0) [0|7] "" ICM

BO_ 851 BCM_CFCAN_FrP48 : 8 Vector_XXX
 SG_ LOtsdMirHoztPos : 31|8@0+ (1.0,0.0) [0.0|255.0] "" ICM
 SG_ LOtsdMirVertPos : 39|8@0+ (1.0,0.0) [0.0|255.0] "" ICM
 SG_ ROtsdMirHoztPos : 47|8@0+ (1.0,0.0) [0.0|255.0] "" ICM
 SG_ ROtsdMirVertPos : 55|8@0+ (1.0,0.0) [0.0|255.0] "" ICM

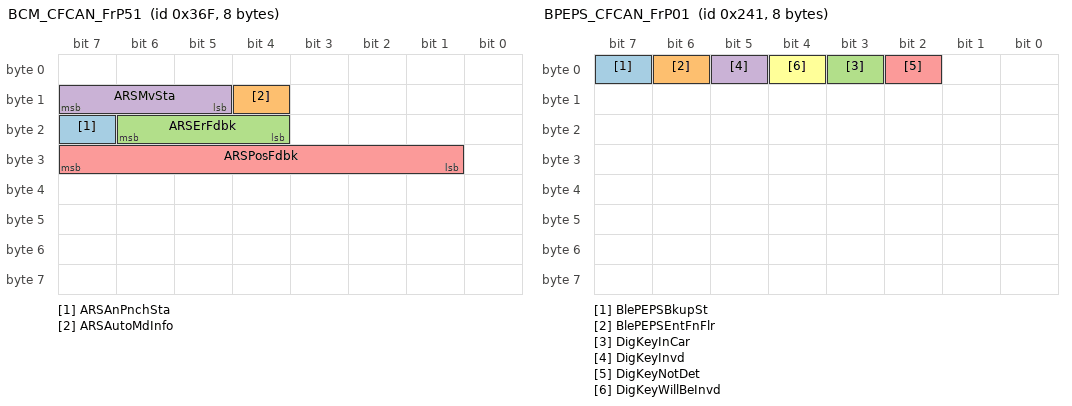
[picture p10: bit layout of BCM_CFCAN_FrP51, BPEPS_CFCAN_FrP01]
BO_ 879 BCM_CFCAN_FrP51 : 8 Vector_XXX
 SG_ ARSAnPnchSta : 23|1@0+ (1,0) [0|1] "" ICM
 SG_ ARSAutoMdInfo : 12|1@0+ (1,0) [0|1] "" ICM
 SG_ ARSErFdbk : 22|3@0+ (1,0) [0|7] "" ICM
 SG_ ARSMvSta : 15|3@0+ (1,0) [0|7] "" ICM
 SG_ ARSPosFdbk : 31|7@0+ (1.0,0.0) [0.0|127.0] "" ICM

BO_ 577 BPEPS_CFCAN_FrP01 : 8 Vector_XXX
 SG_ BlePEPSBkupSt : 7|1@0+ (1,0) [0|1] "" ICM
 SG_ BlePEPSEntFnFlr : 6|1@0+ (1,0) [0|1] "" ICM
 SG_ DigKeyInCar : 3|1@0+ (1,0) [0|1] "" ICM
 SG_ DigKeyInvd : 5|1@0+ (1,0) [0|1] "" ICM
 SG_ DigKeyNotDet : 2|1@0+ (1,0) [0|1] "" ICM
 SG_ DigKeyWillBeInvd : 4|1@0+ (1,0) [0|1] "" ICM

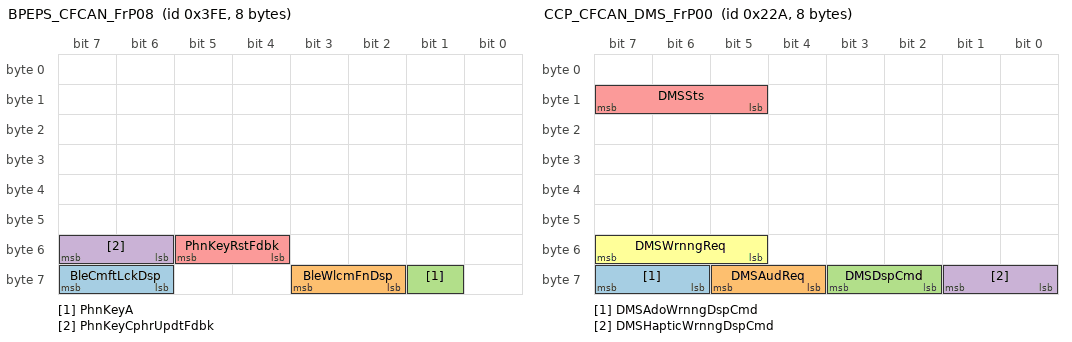
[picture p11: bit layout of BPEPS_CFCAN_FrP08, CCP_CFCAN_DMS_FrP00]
BO_ 1022 BPEPS_CFCAN_FrP08 : 8 Vector_XXX
 SG_ BleCmftLckDsp : 63|2@0+ (1,0) [0|3] "" ICM
 SG_ BleWlcmFnDsp : 59|2@0+ (1,0) [0|3] "" ICM
 SG_ PhnKeyA : 57|1@0+ (1,0) [0|1] "" ICM
 SG_ PhnKeyCphrUpdtFdbk : 55|2@0+ (1,0) [0|3] "" ICM
 SG_ PhnKeyRstFdbk : 53|2@0+ (1,0) [0|3] "" ICM

BO_ 554 CCP_CFCAN_DMS_FrP00 : 8 Vector_XXX
 SG_ DMSAdoWrnngDspCmd : 63|2@0+ (1,0) [0|3] "" ICM
 SG_ DMSAudReq : 61|2@0+ (1,0) [0|3] "" ICM
 SG_ DMSDspCmd : 59|2@0+ (1,0) [0|3] "" ICM
 SG_ DMSHapticWrnngDspCmd : 57|2@0+ (1,0) [0|3] "" ICM
 SG_ DMSSts : 15|3@0+ (1,0) [0|7] "" ICM
 SG_ DMSWrnngReq : 55|3@0+ (1,0) [0|7] "" ICM

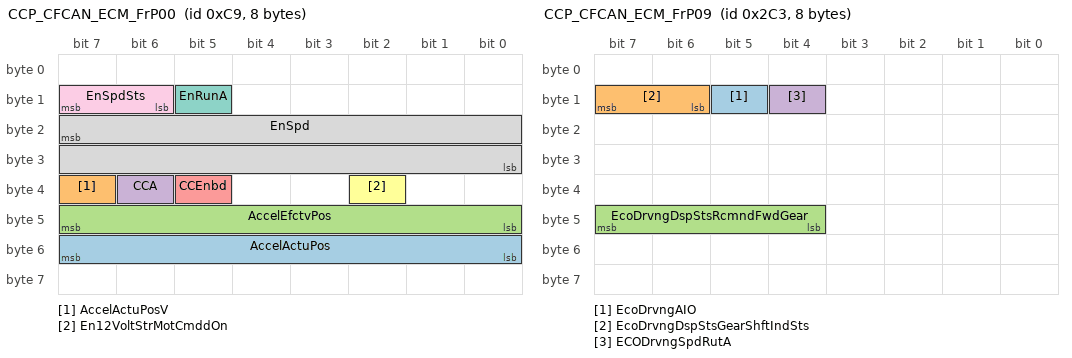
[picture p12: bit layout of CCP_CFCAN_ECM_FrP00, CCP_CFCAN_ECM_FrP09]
BO_ 201 CCP_CFCAN_ECM_FrP00 : 8 Vector_XXX
 SG_ AccelActuPos : 55|8@0+ (0.392157,0.0) [0.0|100.000035] "%" ICM
 SG_ AccelActuPosV : 39|1@0+ (1,0) [0|1] "" ICM
 SG_ AccelEfctvPos : 47|8@0+ (0.392157,0.0) [0.0|100.000035] "%" ICM
 SG_ CCA : 38|1@0+ (1,0) [0|1] "" ICM
 SG_ CCEnbd : 37|1@0+ (1,0) [0|1] "" ICM
 SG_ En12VoltStrMotCmddOn : 34|1@0+ (1,0) [0|1] "" ICM
 SG_ EnRunA : 13|1@0+ (1,0) [0|1] "" ICM
 SG_ EnSpd : 23|16@0+ (0.25,0.0) [0.0|16383.75] "rpm" ICM
 SG_ EnSpdSts : 15|2@0+ (1,0) [0|3] "" ICM

BO_ 404 CCP_CFCAN_ECM_FrP04 : 8 Vector_XXX
 SG_ AutocTrCmddGear : 15|4@0+ (1,0) [0|15] "" ICM
 SG_ CCP_025ms_ECM_PDU04_CRC : 7|8@0+ (1.0,0.0) [0.0|255.0] "" ICM
 SG_ CCP_025ms_ECM_PDU04_RC : 11|4@0+ (1.0,0.0) [0.0|15.0] "" ICM
 SG_ CCP_025ms_ECM_PDU04_Reserve01 : 31|3@0+ (1,0) [0|7] "" ICM
 SG_ CCP_025ms_ECM_PDU04_Reserve02 : 39|1@0+ (1,0) [0|1] "" ICM
 SG_ CCP_025ms_ECM_PDU04_Reserve03 : 36|5@0+ (1,0) [0|31] "" ICM
 SG_ CCP_025ms_ECM_PDU04_Reserve04 : 47|2@0+ (1,0) [0|3] "" ICM
 SG_ CCP_025ms_ECM_PDU04_Reserve05 : 54|7@0+ (1,0) [0|127] "" ICM
 SG_ ClPos : 63|8@0+ (0.392157,0.0) [0.0|100.000035] "%" ICM
 SG_ ClPosV : 55|1@0+ (1,0) [0|1] "" ICM
 SG_ ClStSwA : 37|1@0+ (1,0) [0|1] "" ICM
 SG_ ClStSwAV : 38|1@0+ (1,0) [0|1] "" ICM
 SG_ DrvrShftCtrlTrgtGear : 19|4@0+ (1,0) [0|15] "" ICM
 SG_ TrEstdGear : 23|4@0+ (1,0) [0|15] "" ICM
 SG_ TrEstdGearV : 45|1@0+ (1,0) [0|1] "" ICM
 SG_ TrShftLvrPos : 27|4@0+ (1,0) [0|15] "" ICM
 SG_ TrShftLvrPosV : 28|1@0+ (1,0) [0|1] "" ICM
 SG_ TrShftPtrnASts : 44|3@0+ (1,0) [0|7] "" ICM
 SG_ TrTapUpTapDwnMdSts : 41|2@0+ (1,0) [0|3] "" ICM

BO_ 707 CCP_CFCAN_ECM_FrP09 : 8 Vector_XXX
 SG_ EcoDrvngAIO : 13|1@0+ (1,0) [0|1] "" ICM
 SG_ EcoDrvngDspStsGearShftIndSts : 15|2@0+ (1,0) [0|3] "" ICM
 SG_ EcoDrvngDspStsRcmndFwdGear : 47|4@0+ (1,0) [0|15] "" ICM
 SG_ ECODrvngSpdRutA : 12|1@0+ (1,0) [0|1] "" ICM

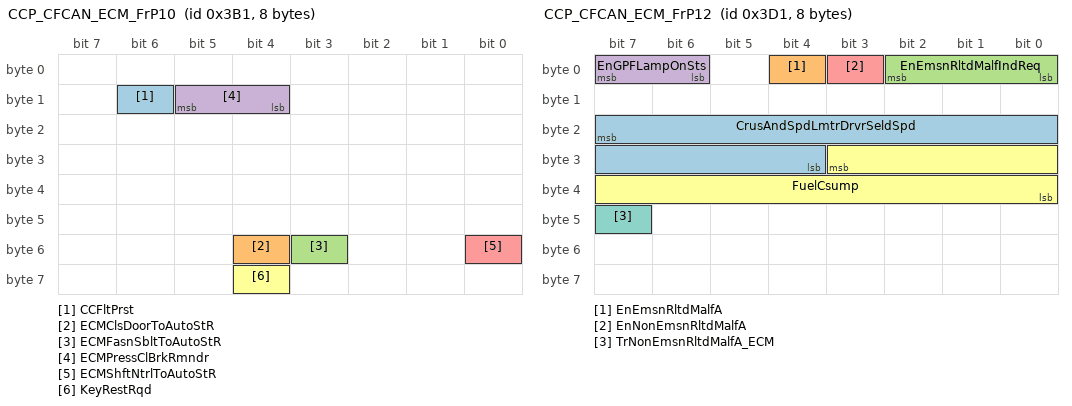
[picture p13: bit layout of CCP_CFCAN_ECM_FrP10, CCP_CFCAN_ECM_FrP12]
BO_ 945 CCP_CFCAN_ECM_FrP10 : 8 Vector_XXX
 SG_ CCFltPrst : 14|1@0+ (1,0) [0|1] "" ICM
 SG_ ECMClsDoorToAutoStR : 52|1@0+ (1,0) [0|1] "" ICM
 SG_ ECMFasnSbltToAutoStR : 51|1@0+ (1,0) [0|1] "" ICM
 SG_ ECMPressClBrkRmndr : 13|2@0+ (1,0) [0|3] "" ICM
 SG_ ECMShftNtrlToAutoStR : 48|1@0+ (1,0) [0|1] "" ICM
 SG_ KeyRestRqd : 60|1@0+ (1,0) [0|1] "" ICM

BO_ 977 CCP_CFCAN_ECM_FrP12 : 8 Vector_XXX
 SG_ CrusAndSpdLmtrDrvrSeldSpd : 23|12@0+ (0.0625,0.0) [0.0|255.9375] "" ICM
 SG_ EnEmsnRltdMalfA : 4|1@0+ (1,0) [0|1] "" ICM
 SG_ EnEmsnRltdMalfIndReq : 2|3@0+ (1,0) [0|7] "" ICM
 SG_ EnGPFLampOnSts : 7|2@0+ (1,0) [0|3] "" ICM
 SG_ EnNonEmsnRltdMalfA : 3|1@0+ (1,0) [0|1] "" ICM
 SG_ FuelCsump : 27|12@0+ (16.0,0.0) [0.0|65520.0] "microlitre" ICM
 SG_ TrNonEmsnRltdMalfA_ECM : 47|1@0+ (1,0) [0|1] "" ICM

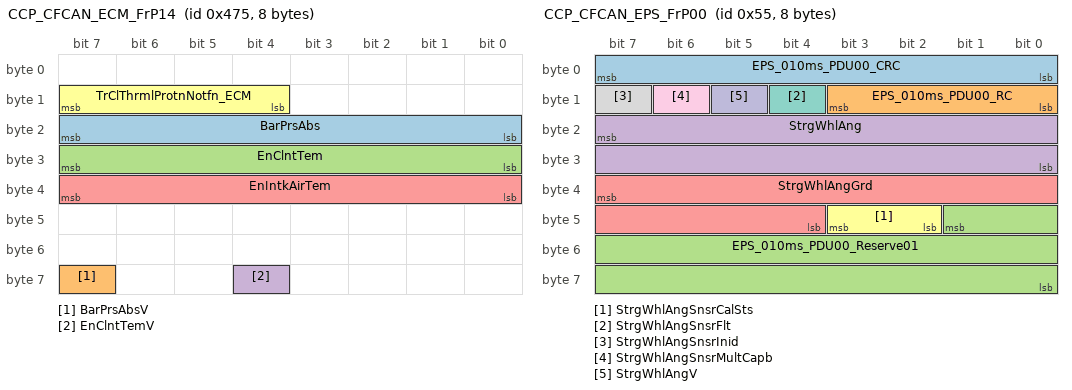
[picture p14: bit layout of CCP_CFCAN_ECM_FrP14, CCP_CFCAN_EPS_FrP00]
BO_ 1141 CCP_CFCAN_ECM_FrP14 : 8 Vector_XXX
 SG_ BarPrsAbs : 23|8@0+ (0.5,0.0) [0.0|127.5] "kPa" ICM
 SG_ BarPrsAbsV : 63|1@0+ (1,0) [0|1] "" ICM
 SG_ EnClntTem : 31|8@0+ (1.0,-40.0) [-40.0|215.0] "deg C" ICM
 SG_ EnClntTemV : 60|1@0+ (1,0) [0|1] "" ICM
 SG_ EnIntkAirTem : 39|8@0+ (1.0,-40.0) [-40.0|215.0] "deg C" ICM
 SG_ TrClThrmlProtnNotfn_ECM : 15|4@0+ (1,0) [0|15] "" ICM

BO_ 884 CCP_CFCAN_ECM_FrP26 : 8 Vector_XXX
 SG_ EnBstPrs : 21|5@0+ (0.1,-1.0) [-1.0|2.1] "" ICM
 SG_ EnOilPrs : 31|8@0+ (4.0,0.0) [0.0|1020.0] "kPa" ICM
 SG_ ExhSptyMdDspCmd : 39|2@0+ (1,0) [0|3] "" ICM

BO_ 85 CCP_CFCAN_EPS_FrP00 : 8 Vector_XXX
 SG_ EPS_010ms_PDU00_CRC : 7|8@0+ (1.0,0.0) [0.0|255.0] "" ICM
 SG_ EPS_010ms_PDU00_RC : 11|4@0+ (1.0,0.0) [0.0|15.0] "" ICM
 SG_ EPS_010ms_PDU00_Reserve01 : 41|18@0+ (1,0) [0|262143] "" ICM
 SG_ StrgWhlAng : 23|16@0+ (0.0625,-2048.0) [-2048.0|2047.875] "degree" ICM
 SG_ StrgWhlAngGrd : 39|12@0+ (1.0,-2048.0) [-2048.0|2046.0] "degree/s" ICM
 SG_ StrgWhlAngSnsrCalSts : 43|2@0+ (1,0) [0|3] "" ICM
 SG_ StrgWhlAngSnsrFlt : 12|1@0+ (1,0) [0|1] "" ICM
 SG_ StrgWhlAngSnsrInid : 15|1@0+ (1,0) [0|1] "" ICM
 SG_ StrgWhlAngSnsrMultCapb : 14|1@0+ (1,0) [0|1] "" ICM
 SG_ StrgWhlAngV : 13|1@0+ (1,0) [0|1] "" ICM

BO_ 328 CCP_CFCAN_EPS_FrP02 : 1 Vector_XXX
 SG_ EPSFlrSts : 7|2@0+ (1,0) [0|3] "" ICM
 SG_ EPSIntAngInidDspReq : 5|2@0+ (1,0) [0|3] "" ICM

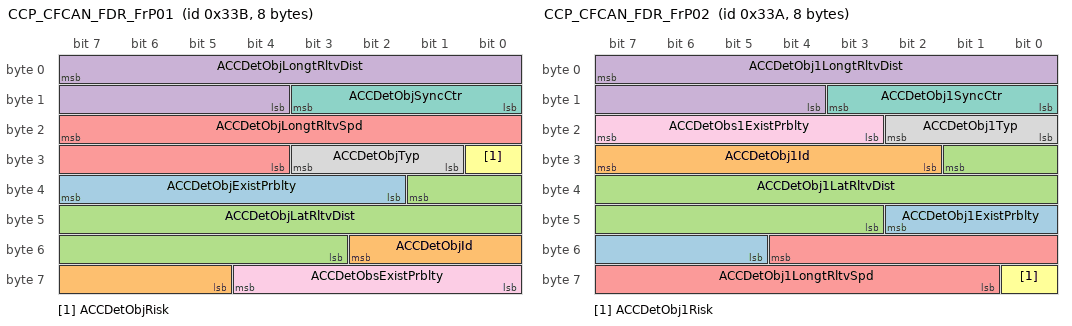
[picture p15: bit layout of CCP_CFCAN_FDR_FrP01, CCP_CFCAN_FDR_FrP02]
BO_ 827 CCP_CFCAN_FDR_FrP01 : 8 Vector_XXX
 SG_ ACCDetObjExistPrblty : 39|6@0+ (0.015625,0.0) [0.0|0.984375] "" ICM
 SG_ ACCDetObjId : 50|6@0+ (1.0,0.0) [0.0|63.0] "" ICM
 SG_ ACCDetObjLatRltvDist : 33|15@0+ (0.0078,-128.0) [-128.0|127.58259999999999] "" ICM
 SG_ ACCDetObjLongtRltvDist : 7|12@0+ (0.0625,0.0) [0.0|255.9375] "" ICM
 SG_ ACCDetObjLongtRltvSpd : 23|12@0+ (0.0625,-128.0) [-128.0|127.9375] "" ICM
 SG_ ACCDetObjRisk : 24|1@0+ (1,0) [0|1] "" ICM
 SG_ ACCDetObjSyncCtr : 11|4@0+ (1.0,0.0) [0.0|15.0] "" ICM
 SG_ ACCDetObjTyp : 27|3@0+ (1,0) [0|7] "" ICM
 SG_ ACCDetObsExistPrblty : 60|5@0+ (0.03125,0.0) [0.0|0.96875] "" ICM

BO_ 826 CCP_CFCAN_FDR_FrP02 : 8 Vector_XXX
 SG_ ACCDetObj1ExistPrblty : 42|6@0+ (0.015625,0.0) [0.0|0.984375] "" ICM
 SG_ ACCDetObj1Id : 31|6@0+ (1.0,0.0) [0.0|63.0] "" ICM
 SG_ ACCDetObj1LatRltvDist : 25|15@0+ (0.0078,-128.0) [-128.0|127.58259999999999] "" ICM
 SG_ ACCDetObj1LongtRltvDist : 7|12@0+ (0.0625,0.0) [0.0|255.9375] "" ICM
 SG_ ACCDetObj1LongtRltvSpd : 52|12@0+ (0.0625,-128.0) [-128.0|127.9375] "" ICM
 SG_ ACCDetObj1Risk : 56|1@0+ (1,0) [0|1] "" ICM
 SG_ ACCDetObj1SyncCtr : 11|4@0+ (1.0,0.0) [0.0|15.0] "" ICM
 SG_ ACCDetObj1Typ : 18|3@0+ (1,0) [0|7] "" ICM
 SG_ ACCDetObs1ExistPrblty : 23|5@0+ (0.03125,0.0) [0.0|0.96875] "" ICM

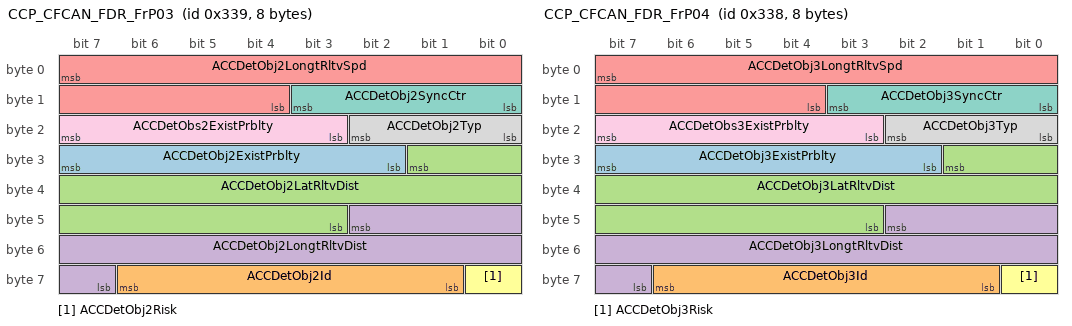
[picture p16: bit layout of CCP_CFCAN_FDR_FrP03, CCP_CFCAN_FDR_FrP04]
BO_ 825 CCP_CFCAN_FDR_FrP03 : 8 Vector_XXX
 SG_ ACCDetObj2ExistPrblty : 31|6@0+ (0.015625,0.0) [0.0|0.984375] "" ICM
 SG_ ACCDetObj2Id : 62|6@0+ (1.0,0.0) [0.0|63.0] "" ICM
 SG_ ACCDetObj2LatRltvDist : 25|15@0+ (0.0078,-128.0) [-128.0|127.58259999999999] "" ICM
 SG_ ACCDetObj2LongtRltvDist : 42|12@0+ (0.0625,0.0) [0.0|255.9375] "" ICM
 SG_ ACCDetObj2LongtRltvSpd : 7|12@0+ (0.0625,-128.0) [-128.0|127.9375] "" ICM
 SG_ ACCDetObj2Risk : 56|1@0+ (1,0) [0|1] "" ICM
 SG_ ACCDetObj2SyncCtr : 11|4@0+ (1.0,0.0) [0.0|15.0] "" ICM
 SG_ ACCDetObj2Typ : 18|3@0+ (1,0) [0|7] "" ICM
 SG_ ACCDetObs2ExistPrblty : 23|5@0+ (0.03125,0.0) [0.0|0.96875] "" ICM

BO_ 824 CCP_CFCAN_FDR_FrP04 : 8 Vector_XXX
 SG_ ACCDetObj3ExistPrblty : 31|6@0+ (0.015625,0.0) [0.0|0.984375] "" ICM
 SG_ ACCDetObj3Id : 62|6@0+ (1.0,0.0) [0.0|63.0] "" ICM
 SG_ ACCDetObj3LatRltvDist : 25|15@0+ (0.0078,-128.0) [-128.0|127.58259999999999] "" ICM
 SG_ ACCDetObj3LongtRltvDist : 42|12@0+ (0.0625,0.0) [0.0|255.9375] "" ICM
 SG_ ACCDetObj3LongtRltvSpd : 7|12@0+ (0.0625,-128.0) [-128.0|127.9375] "" ICM
 SG_ ACCDetObj3Risk : 56|1@0+ (1,0) [0|1] "" ICM
 SG_ ACCDetObj3SyncCtr : 11|4@0+ (1.0,0.0) [0.0|15.0] "" ICM
 SG_ ACCDetObj3Typ : 18|3@0+ (1,0) [0|7] "" ICM
 SG_ ACCDetObs3ExistPrblty : 23|5@0+ (0.03125,0.0) [0.0|0.96875] "" ICM

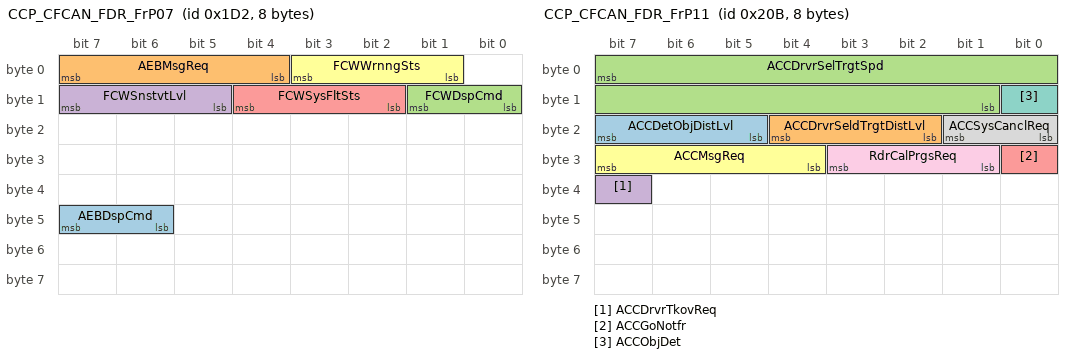
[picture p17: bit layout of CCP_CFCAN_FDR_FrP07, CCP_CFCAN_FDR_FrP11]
BO_ 466 CCP_CFCAN_FDR_FrP07 : 8 Vector_XXX
 SG_ AEBDspCmd : 47|2@0+ (1,0) [0|3] "" ICM
 SG_ AEBMsgReq : 7|4@0+ (1,0) [0|15] "" ICM
 SG_ FCWDspCmd : 9|2@0+ (1,0) [0|3] "" ICM
 SG_ FCWSnstvtLvl : 15|3@0+ (1,0) [0|7] "" ICM
 SG_ FCWSysFltSts : 12|3@0+ (1,0) [0|7] "" ICM
 SG_ FCWWrnngSts : 3|3@0+ (1,0) [0|7] "" ICM

BO_ 523 CCP_CFCAN_FDR_FrP11 : 8 Vector_XXX
 SG_ ACCDetObjDistLvl : 23|3@0+ (1,0) [0|7] "" ICM
 SG_ ACCDrvrSeldTrgtDistLvl : 20|3@0+ (1,0) [0|7] "" ICM
 SG_ ACCDrvrSelTrgtSpd : 7|15@0+ (0.015625,0.0) [0.0|511.984375] "" ICM
 SG_ ACCDrvrTkovReq : 39|1@0+ (1,0) [0|1] "" ICM
 SG_ ACCGoNotfr : 24|1@0+ (1,0) [0|1] "" ICM
 SG_ ACCMsgReq : 31|4@0+ (1,0) [0|15] "" ICM
 SG_ ACCObjDet : 8|1@0+ (1,0) [0|1] "" ICM
 SG_ ACCSysCanclReq : 17|2@0+ (1,0) [0|3] "" ICM
 SG_ RdrCalPrgsReq : 27|3@0+ (1,0) [0|7] "" ICM

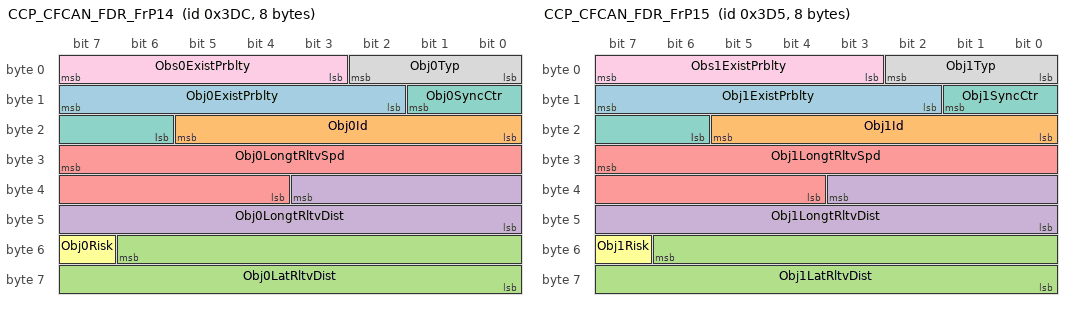
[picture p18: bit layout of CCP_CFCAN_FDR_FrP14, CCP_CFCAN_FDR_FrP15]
BO_ 988 CCP_CFCAN_FDR_FrP14 : 8 Vector_XXX
 SG_ Obj0ExistPrblty : 15|6@0+ (0.015625,0.0) [0.0|0.984375] "" ICM
 SG_ Obj0Id : 21|6@0+ (1.0,0.0) [0.0|63.0] "" ICM
 SG_ Obj0LatRltvDist : 54|15@0+ (0.0078,-128.0) [-128.0|127.58259999999999] "" ICM
 SG_ Obj0LongtRltvDist : 35|12@0+ (0.0625,-128.0) [-128.0|127.9375] "" ICM
 SG_ Obj0LongtRltvSpd : 31|12@0+ (0.0625,-128.0) [-128.0|127.9375] "" ICM
 SG_ Obj0Risk : 55|1@0+ (1,0) [0|1] "" ICM
 SG_ Obj0SyncCtr : 9|4@0+ (1.0,0.0) [0.0|15.0] "" ICM
 SG_ Obj0Typ : 2|3@0+ (1,0) [0|7] "" ICM
 SG_ Obs0ExistPrblty : 7|5@0+ (0.03125,0.0) [0.0|0.96875] "" ICM

BO_ 981 CCP_CFCAN_FDR_FrP15 : 8 Vector_XXX
 SG_ Obj1ExistPrblty : 15|6@0+ (0.015625,0.0) [0.0|0.984375] "" ICM
 SG_ Obj1Id : 21|6@0+ (1.0,0.0) [0.0|63.0] "" ICM
 SG_ Obj1LatRltvDist : 54|15@0+ (0.0078,-128.0) [-128.0|127.58259999999999] "" ICM
 SG_ Obj1LongtRltvDist : 35|12@0+ (0.0625,-128.0) [-128.0|127.9375] "" ICM
 SG_ Obj1LongtRltvSpd : 31|12@0+ (0.0625,-128.0) [-128.0|127.9375] "" ICM
 SG_ Obj1Risk : 55|1@0+ (1,0) [0|1] "" ICM
 SG_ Obj1SyncCtr : 9|4@0+ (1.0,0.0) [0.0|15.0] "" ICM
 SG_ Obj1Typ : 2|3@0+ (1,0) [0|7] "" ICM
 SG_ Obs1ExistPrblty : 7|5@0+ (0.03125,0.0) [0.0|0.96875] "" ICM

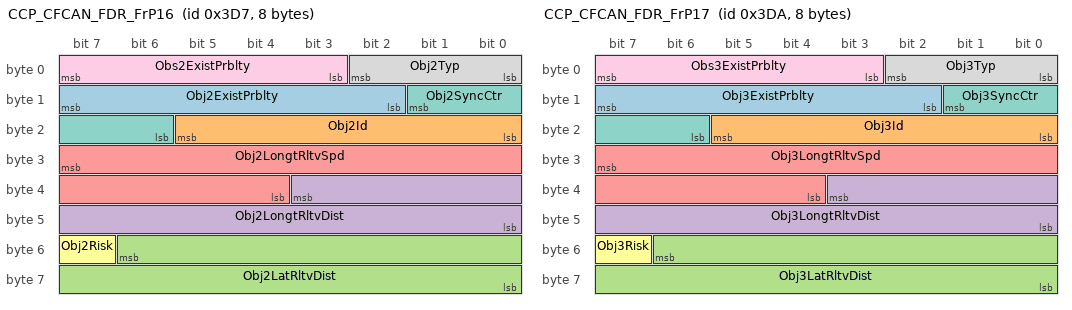
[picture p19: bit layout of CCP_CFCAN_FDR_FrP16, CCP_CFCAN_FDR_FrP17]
BO_ 983 CCP_CFCAN_FDR_FrP16 : 8 Vector_XXX
 SG_ Obj2ExistPrblty : 15|6@0+ (0.015625,0.0) [0.0|0.984375] "" ICM
 SG_ Obj2Id : 21|6@0+ (1.0,0.0) [0.0|63.0] "" ICM
 SG_ Obj2LatRltvDist : 54|15@0+ (0.0078,-128.0) [-128.0|127.58259999999999] "" ICM
 SG_ Obj2LongtRltvDist : 35|12@0+ (0.0625,-128.0) [-128.0|127.9375] "" ICM
 SG_ Obj2LongtRltvSpd : 31|12@0+ (0.0625,-128.0) [-128.0|127.9375] "" ICM
 SG_ Obj2Risk : 55|1@0+ (1,0) [0|1] "" ICM
 SG_ Obj2SyncCtr : 9|4@0+ (1.0,0.0) [0.0|15.0] "" ICM
 SG_ Obj2Typ : 2|3@0+ (1,0) [0|7] "" ICM
 SG_ Obs2ExistPrblty : 7|5@0+ (0.03125,0.0) [0.0|0.96875] "" ICM

BO_ 986 CCP_CFCAN_FDR_FrP17 : 8 Vector_XXX
 SG_ Obj3ExistPrblty : 15|6@0+ (0.015625,0.0) [0.0|0.984375] "" ICM
 SG_ Obj3Id : 21|6@0+ (1.0,0.0) [0.0|63.0] "" ICM
 SG_ Obj3LatRltvDist : 54|15@0+ (0.0078,-128.0) [-128.0|127.58259999999999] "" ICM
 SG_ Obj3LongtRltvDist : 35|12@0+ (0.0625,-128.0) [-128.0|127.9375] "" ICM
 SG_ Obj3LongtRltvSpd : 31|12@0+ (0.0625,-128.0) [-128.0|127.9375] "" ICM
 SG_ Obj3Risk : 55|1@0+ (1,0) [0|1] "" ICM
 SG_ Obj3SyncCtr : 9|4@0+ (1.0,0.0) [0.0|15.0] "" ICM
 SG_ Obj3Typ : 2|3@0+ (1,0) [0|7] "" ICM
 SG_ Obs3ExistPrblty : 7|5@0+ (0.03125,0.0) [0.0|0.96875] "" ICM

CM_ SG_ 1142 VINClstr "Vehicle Identifier Number Cluster
the last 8 btyes' of VIN.";
CM_ SG_ 1073 AirbagWrnngIndF "Airbag Warning Indication Failed
send out the status of Airbag warning lamp";
CM_ SG_ 1073 Clstr10KmTick "Cluster 10 Kilometer Tick
when IPK'VIN code does match with other module, IPK will send '1' status out.";
CM_ SG_ 1073 FuelLvlPcnt "Fuel Level Percent
percent of cyrrent tank level divide 'Fuel Total Capacity'.";
CM_ SG_ 1073 FuelLvlPcntV "Fuel Level Percent Validity
when fuel sensor resistance is out of range, the signal value is set to 1 otherwise set to 0.";
CM_ SG_ 1073 FuelTotCapct "Fuel Total Capacity
fuel tank max capacity, which can be detected by fuel sensor.";
CM_ SG_ 1073 SIADatePriy "Service Interval Announcement Date Primary
the date of last do SIA operation.

0x xx xx xx=(Year, Month, Date).

MSB:year,
LSB:day";
CM_ SG_ 402 ChmCmdSndTone "Sound  Characteristics
Chime Command Sound Tone";
CM_ SG_ 402 ClstrDspdVehSpd "Cluster Displayed Vehicle Speed";
CM_ SG_ 402 DspMeasSys "Display Measurement System";
CM_ SG_ 1134 OdoPriy "Odometer Primary
Odometer value";
CM_ SG_ 1134 SIAOdoPriy "Service Interval Announcement Odometer Primary
the odometer value of last do SIA operation.";
CM_ SG_ 1345 CalendarDay "current day info.";
CM_ SG_ 1345 CalendarMonth "current month info.";
CM_ SG_ 1345 CalendarYear "current year info";
CM_ SG_ 1345 HourOfDay "Hour Of Day.
current Hour info.";
CM_ SG_ 1345 IPK_200ms_PDU06_CRC "Wheel Ground Velocity Non Driven Checksum
Regarding high integrity requirement, a checksum signal is used for the bit field in same frame. The signal XOR operation is recommended for the calculation.";
CM_ SG_ 1345 MinuteOfHour "Minute Of Hour.
current Minute info.";
CM_ SG_ 1345 SecsOfMinute "Seconds Of Minute
current Second info.";
CM_ SG_ 1345 TimeDspFmt "Time Display Format
current Time format.";
CM_ SG_ 817 IPCEcoDrvngSwA "Instrument Cluster Economy Driving Switch Active
";
CM_ SG_ 817 IPK_100ms_PDU07_CRC "Wheel Ground Velocity Non Driven Checksum
Regarding high integrity requirement, a checksum signal is used for the bit field in same frame. The signal XOR operation is recommended for the calculation.";
CM_ SG_ 817 ParkBrkSwA "Park Brake Switch Active";
CM_ SG_ 1144 FuelLvlPcntRaw "Fuel Level Percent Raw";
CM_ SG_ 1144 FuelLvlPcntRawV "Fuel Level Percent Raw Validity";
CM_ SG_ 1144 FuelLvlSnsrFlrSts "Fuel Level Sensor Failure Status";
CM_ SG_ 1144 FuelLvlSnsrFlrStsInvsn "Fuel Level Sensor Failure Status Inversion";
CM_ SG_ 1144 IPKOdoReq "Battery Inconsistency";
CM_ SG_ 1031 ClstrDspdPwrLftgtSysWrnng "Cluster Displayed Power Liftgate System Warning";
CM_ SG_ 537 ADASDspdErInHMI "Advanced Driver Assistance Systems Displayed Error In Human Machine Interface";
CM_ SG_ 537 ADASErDetcByHMI "Advanced Driver Assistance System Error Detect By Human Machine Interface";
CM_ SG_ 537 IPK_050ms_PDU31_CRC "Wheel Ground Velocity Non Driven Checksum
Regarding high integrity requirement, a checksum signal is used for the bit field in same frame. The signal XOR operation is recommended for the calculation.";
CM_ SG_ 672 RrACAutoDspCmd "Rear Air Conditioning Auto Display Command";
CM_ SG_ 892 ACSyncDspCmd "Air Conditioning Front Rear Synchronization Display Command";
CM_ SG_ 892 HtdRrWndSwA "Heated Rear Window Switch Active";
CM_ SG_ 892 InsdAirPrtclMtrCncntrnDspCmd "Inside Air Particulate Matter Concentration Display Command (PM2.5)
";
CM_ SG_ 893 ACFltrCsumLvlDspCmd "Air Conditioning Filter Consume Level Display Command";
CM_ SG_ 893 ACUserCustAftRunOnOffDspCmd "Air Conditioning User Customization Blower Auto Run Remote Unlock Display Command
";
CM_ SG_ 893 ACUserCustAirQultEnbDspCmd "Air Conditioning User Customization Zone Configuration Display Command
";
CM_ SG_ 893 ACUserCustAutoMdBlwrDspCmd "Air Conditioning User Customization Auto Mode Blower Display Command";
CM_ SG_ 893 ACUserCustAutoMdTemDspCmd "Air Conditioning User Customization Auto Mode Temperature Display Command";
CM_ SG_ 893 ACUserCustBlwrAutoRunRmtUnlckDspCmd "Air Conditioning User Customization Blower Auto Run Remote Unlock Display Command";
CM_ SG_ 893 ACUserCustCofignDspCmd "Air Conditioning User Customization Configuration Display Command";
CM_ SG_ 893 ACUserCustFltrLifeRmndDspCmd "Air Conditioning User Customization Filter Life Remind Display Command";
CM_ SG_ 893 ACUserCustFrtAutoDmstngDspCmd "Air Conditioning User Customization Front Auto Demisting Display Command";
CM_ SG_ 893 ACUserCustRmtStOnOffDspCmd "Air Conditioning User Customization Remote Start On Off Display Command";
CM_ SG_ 893 ACUserCustRrAutoDmstngDspCmd "Air Conditioning User Customization Start Stop Mode Display Command
";
CM_ SG_ 893 ACUserCustRrZoneCofignDspCmd "Air Conditioning User Customization Front Auto Demisting Display Command
";
CM_ SG_ 893 ACUserCustStSpMdDspCmd "Air Conditioning User Customization Start Stop Mode Display Command";
CM_ SG_ 893 ACUserCustTemUnitDspCmd "Air Conditioning User Customization Temperature Unit Display Command";
CM_ SG_ 893 ACUserCustZoneCofignDspCmd "Air Conditioning User Customization Zone Configuration Display Command";
CM_ SG_ 893 AirClnrAutoDspCmd "Air Cleaner Auto Display Command
";
CM_ SG_ 893 AirClnrBlwrLvlDspCmd "Air Cleaner Blower Level Display Command
";
CM_ SG_ 893 AirClnrBlwrSpdSwA "Air Cleaner Blower Speed Switch Active
";
CM_ SG_ 893 AirClnrIonizerDspCmd "Air Cleaner Ionizer Display Command
";
CM_ SG_ 893 AirClnrOnOffDspCmd "Air Cleaner On Off Display Command
";
CM_ SG_ 893 AirClnrUserCustAutoRDC "Air Cleaner User Customization Auto Run Display Command

";
CM_ SG_ 894 ACDrvrAirMdDspCmd "Air Conditioning Driver Air Mode Display Command";
CM_ SG_ 894 ACDrvrTemDspCmd "Air Conditioning Driver Temperature Display Command";
CM_ SG_ 894 ACDrvrTemSwA "Air Conditioning Driver Temperature Switch Active";
CM_ SG_ 894 ACFrtRrSyncDspCmd "Air Conditioning Front Rear Synchronize Display Command";
CM_ SG_ 894 ACPsngAirMdDspCmd "Air Conditioning Passenger Air Mode Display Command";
CM_ SG_ 894 ACPsngTemDspCmd "Air Conditioning Passenger Temperature Display Command";
CM_ SG_ 894 ACPsngTemSwA "Air Conditioning Passenger Temperature Switch Active";
CM_ SG_ 936 ACAutoDspCmd "Air Conditioning Auto Display Command";
CM_ SG_ 936 ACDualDspCmd "Air Conditioning Dual Display Command";
CM_ SG_ 936 ACEcoDspCmd "Air Conditioning Economy Display Command";
CM_ SG_ 936 ACFrtBlwrSpdDspCmd "Air Conditioning Front Blower Speed Display Command";
CM_ SG_ 936 ACFrtBlwrSpdSwA "Air Conditioning Front Blower Speed Switch Active";
CM_ SG_ 936 ACFrtPnlLckRrPnlDspCmd "Air Conditioning Front Panel Lock Rear Panel Display Command";
CM_ SG_ 936 ACIonizerDspCmd "Air Conditioning Ionizer Display Command";
CM_ SG_ 936 ACLAirMdDspCmd "Air Conditioning Driver Air Mode Display Command";
CM_ SG_ 936 ACLTemDspCmd "Air Conditioning Driver Temperature Display Command";
CM_ SG_ 936 ACLTemSwA "Air Conditioning Driver Temperature Switch Active";
CM_ SG_ 936 ACOnOffDspCmd "Air Conditioning On Off Display Command
";
CM_ SG_ 936 ACRAirMdDspCmd "Air Conditioning Passenger Air Mode Command";
CM_ SG_ 936 ACRcctnDspMd "Air Conditioning Recirculation Display Mode";
CM_ SG_ 936 ACRrAirMdDspCmd "Air Conditioning Rear Mode Display Command";
CM_ SG_ 936 ACRrBlwrDspCmd "Air Conditioning Rear Blower Command";
CM_ SG_ 936 ACRrBlwrLvlDspCmd "Air Conditioning Rear Blower Level Display Command";
CM_ SG_ 936 ACRrBlwrSpdSwA "Air Conditioning Rear Blower Speed Switch Active";
CM_ SG_ 936 ACRrTemDspCmd "Air Conditioning Rear Temperature Display Command.";
CM_ SG_ 936 ACRrTemSwA "Air Conditioning Rear Temperature Switch Active";
CM_ SG_ 936 ACRTemDspCmd "Air Conditioning Passenger Temperature Display Command.";
CM_ SG_ 936 ACRTemSwA "Air Conditioning Passenger Temperature Switch Active";
CM_ SG_ 936 ClmOnOffDspCmd "Climate On Off Display Command";
CM_ SG_ 936 ComprOnOffDspCmd "Air Conditioning Off Display Command";
CM_ SG_ 936 DfstOnDspCmd "Defrost On Display Command";
CM_ SG_ 936 FLSeatHeatDspCmd "Front Left Seat Heat Display Command";
CM_ SG_ 936 FLSeatVentDspCmd "Front Left Seat Vent Display Command";
CM_ SG_ 936 FRSeatHeatDspCmd "Front Right Seat Heat Display Command";
CM_ SG_ 936 FRSeatVentDspCmd "Front Right Seat Vent Display Command";
CM_ SG_ 936 HtdRrWndOnDspCmd "Heated Rear Window On Display Command";
CM_ SG_ 1361 OtsdAirPrtclMtrCncntrnDspCmd "Outside Air Particulate Matter Concentration Display Command (PM2.5)
";
CM_ SG_ 1509 ACAmbtTem "Air Conditioning Ambient Temperature";
CM_ SG_ 1509 ACAmbtTemMsk "Air Conditioning Ambient Temperature Mask";
CM_ SG_ 1509 ACAmbtTemV "Air Conditioning Ambient Temperature Validity";
CM_ SG_ 1509 ACFltrTyp "Air Conditioning Filter Type";
CM_ SG_ 1509 ACInCarTem "Air Conditioning In Car Temperature";
CM_ SG_ 1509 ACTemUnitDspCmd "Air Conditioning Temperature Unit Display Command";
CM_ SG_ 1509 AirClnrFltrCsumLvlDspCmd "Air Cleaner Filter Consume Level Display Command
";
CM_ SG_ 1509 AirClnrFltrLife "Air Cleaner Filter Life
";
CM_ SG_ 1509 AirClnrFltrLifeV "Air Cleaner Filter Life Validity
";
CM_ SG_ 993 OtsdAirPrtclMtrCDC "Outside Air Particulate Matter Concentration Display Command";
CM_ SG_ 43 AllMuteFdbk "All Mute Feedback";
CM_ SG_ 43 AutocVolmCmpstnFdbk "Automatic Volume Compensation Feedback";
CM_ SG_ 43 BalcSetngFdbk "Balance Setting Feedback";
CM_ SG_ 43 BassFdbk "Bass Feedback";
CM_ SG_ 43 ChmSndVolmStepFdbk "Chime Sound Volume Step Feedback
";
CM_ SG_ 43 FdrSetngFdbk "Fader Setting Feedback";
CM_ SG_ 43 MdaMuteFdbk "Media Mute Feedback";
CM_ SG_ 43 MdaSndVolmStepFdbk "Media Sound Volume Step Feedback";
CM_ SG_ 43 MedFdbk "Medium Feedback";
CM_ SG_ 43 NavSndVolmStepFdbk "Navigation Sound Volume Step Feedback";
CM_ SG_ 43 PhnCallSndVolmStepFdbk "Phone Call Sound Volume Step Feedback";
CM_ SG_ 43 SpdDpntAutocVolmFdbk "Speed Dependant Automatic Volume Feedback";
CM_ SG_ 43 ThreeDimnSndFldFdbk "Three Dimension Sound Field Feedback";
CM_ SG_ 43 TrblFdbk "Treble Feedback";
CM_ SG_ 43 VcItatnSndVolmStepFdbk "Voice Interaction Sound Volume Step Feedback";
CM_ SG_ 1553 AMPASndWaveSelSts "Amplifier Active Sound Wave Select Status
";
CM_ SG_ 1553 AMPASndWaveSts "Amplifier Active Sound Wave Status
";
CM_ SG_ 822 BCMFLSeatHeatLvl "BCM Front Left Seat Heat Level";
CM_ SG_ 822 BCMFRSeatHeatLvl "BCM Front Right Seat Heat Level";
CM_ SG_ 822 DrvrPWLInitnRmndr "Driver Power Window Lifter Initialization Reminder,Remind the Driver to Initialize Driver Power Window Lifter";
CM_ SG_ 822 DrvrWndDclnSpc "Driver Window Decline Space";
CM_ SG_ 822 DrvrWndOpenRmndr "Driver Window Open Reminder
";
CM_ SG_ 822 FrtPsngPWLInitnRmndr "Front Passenger Power Window Lifter Initialization Reminder";
CM_ SG_ 822 FrtPsngWndDclnSpc "Front Passenger Window Decline Space
";
CM_ SG_ 822 FrtPsngWndOpenRmndr "Front Passenger Window Open Reminder
";
CM_ SG_ 822 OtsdMirFoldSts "Outside Mirror fold status
";
CM_ SG_ 822 RLPWLInitnRmndr "Rear Left Power Window Lifter Initialization Reminder
";
CM_ SG_ 822 RLWndDclnSpc "Rear Left Window Decline Space
";
CM_ SG_ 822 RLWndOpenRmndr "Rear Left Window Open Reminder";
CM_ SG_ 822 RRPWLInitnRmndr "Rear Right Power Window Lifter Initialization Reminder
";
CM_ SG_ 822 RRWndDclnSpc "Rear Right Window Decline Space
";
CM_ SG_ 822 RRWndOpenRmndr "Rear Right Window Open Reminder";
CM_ SG_ 822 SrfInitnRmndr "Sunroof Initialization Reminder";
CM_ SG_ 822 SrfOpenRmndr "Sunroof Open Reminder";
CM_ SG_ 822 SrfSlidePosSts "Sunroof Slide Position Status";
CM_ SG_ 822 SrfTiltSts "FICM Sunroof Tilt Status
";
CM_ SG_ 815 BntOpenSts "Bonnet Open Status";
CM_ SG_ 815 DrvrDoorOpenSts "Driver Door Open Status";
CM_ SG_ 815 FrtPsngDoorOpenSts "Front Passenger Door Open Status";
CM_ SG_ 815 FrtWiperMdSts "Front Wiper Mode Status";
CM_ SG_ 815 FrtWiperOpReq "Front Wiper Operation Request";
CM_ SG_ 815 FrtWiperSwSts "Front Wiper Switch Status";
CM_ SG_ 815 FrtWshrPumpA "Front Washer Pump Active";
CM_ SG_ 815 LdspcOpenSts "Loadspace Open Status";
CM_ SG_ 815 LowWiperWshrFludLvlSwA "Low Wiper Washer Fluid Level Switch Active";
CM_ SG_ 815 RLDoorOpenSts "Rear Left Door Open Status";
CM_ SG_ 815 RRDoorOpenSts "Rear Right Door Open Status";
CM_ SG_ 815 RrWiperMdSts "Rear Wiper Mode Status
";
CM_ SG_ 815 RrWshrPumpA "Rear Washer Pump Active
";
CM_ SG_ 815 ScurtAlrmSts "Security Alarm Status";
CM_ SG_ 815 ScurtAlrmTrigd "Security Alarm Triggered";
CM_ SG_ 815 VehLckngSta "Vehicle Locking State";
CM_ SG_ 830 BCMGearShftParkNtrlEnStngRmndr "Body Control Module Gear Shift Park Neutral Engine Starting Reminder
";
CM_ SG_ 830 BCMNoSmtKeyInVehRmndr "Body Control Module No Smart Key In Vehicle Reminder";
CM_ SG_ 830 BCMNoSmtKeyPressBrkToRestRmndr "Body Control Module No Smart Key Press Brake To Restart Reminder";
CM_ SG_ 830 BCMNoSmtKeyPressClToRestRmndr "Body Control Module No Smart Key Press Clutch To Restart Reminder";
CM_ SG_ 830 BCMPressBrkRmndr "Body Control Module Press Brake Reminder";
CM_ SG_ 830 BCMPressClRmndr "Body Control Module Press Clutch Reminder";
CM_ SG_ 830 BCMPutSmtKeyToBkupPosR "Body Control Module Put Smart Key Into Backup Position Reminder";
CM_ SG_ 830 BCMShftParkRmndr "Body Control Module Shift Park Reminder";
CM_ SG_ 830 BCMSyncSmtKeyRmndr "Body Control Module Synchronize Smart Key Reminder";
CM_ SG_ 830 BCMTakeSmtKeyOutOfSlotRmndr "Body Control Module Take Smart Key Out Of Slot Reminder";
CM_ SG_ 830 ScurtKeyBatLow "Security Key Battery Low";
CM_ SG_ 830 ShifterLckRlseBrkReqA "Shifter Lock Release Brake Request Active";
CM_ SG_ 830 SSBEnOffRmndr "Start Stop Button Engine OFF  Reminder";
CM_ SG_ 830 TakeKeyOutRmndr "Take Key Out Reminder";
CM_ SG_ 804 AutocLghtIndReq "Automatic Light Indication Request
";
CM_ SG_ 804 AutoMainBeamLghtOn "Auto Main Beam Light On
";
CM_ SG_ 804 CHMSLF "Center High Mounted Stop Light Failed
";
CM_ SG_ 804 DayTimeRunningLampOn "Day Time Running Lamp On";
CM_ SG_ 804 DayTimeRunningLghtF "Day Time Running Light Failed";
CM_ SG_ 804 DimLghtLvl "Dimming Light Level";
CM_ SG_ 804 DipdBeamLghtOn "Dipped Beam Light On
Indicate Dipped Beam Light was On for AFS";
CM_ SG_ 804 DircnIndLampSwSts "Direction Indication Lamp Switch Status
";
CM_ SG_ 804 FrtFogLghtOn "Front Fog Light On";
CM_ SG_ 804 LBrkLghtF "Left Brake Light Failed";
CM_ SG_ 804 LDipdBeamLghtF "Left Dipped Beam Light Failed";
CM_ SG_ 804 LDircnIndLghtF "Left Direction Indication Light Failed";
CM_ SG_ 804 LghtSwDimPos "Light Switch Dimming Position";
CM_ SG_ 804 LghtSwPosSts "Light Switch Position Status
Indicate the Posistion of  MLS ";
CM_ SG_ 804 LSideLghtF "Left Side Light Failed";
CM_ SG_ 804 MainBeamLghtOn "Main Beam Light On
";
CM_ SG_ 804 RBrkLghtF "Right Brake Light Failed";
CM_ SG_ 804 RDipdBeamLghtF "Right Dipped Beam Light Failed";
CM_ SG_ 804 RDircnIndLghtF "Right Direction Indication Light Failed";
CM_ SG_ 804 RevsLghtF "Reverse Light Failed";
CM_ SG_ 804 RgstnPltLghtF "Registration Plate Light Failed
";
CM_ SG_ 804 RrFogLghtF "Rear Fog Light Failed";
CM_ SG_ 804 RrFogLghtOn "Rear Fog Light On
";
CM_ SG_ 804 RrSideLghtF "Rear Side Light Failed
";
CM_ SG_ 804 RSideLghtF "Right Side Light Failed";
CM_ SG_ 804 VehSideLghtSts "Vehicle Side Light Status";
CM_ SG_ 1125 BCMCofignSts "Body Control Module Configuration Status";
CM_ SG_ 1139 VINBCM "VIN Code Record in BCM";
CM_ SG_ 1127 BCMOdoReq "Battery Inconsistency";
CM_ SG_ 1127 OdoSecy "Odometer Secondary
Odo Backup in BCM";
CM_ SG_ 1127 SIAOdoSecy "Service Interval Announcement Odometer Secondary";
CM_ SG_ 1051 AmbtLghtCustSetngDspCmd "Ambient Light Customization Setting Display Command
";
CM_ SG_ 1051 AmbtLghtDrvMdCustOnOffDspCmd "Ambient Light Drive Mode Customization On Off Display Command";
CM_ SG_ 1051 AmbtLghtDrvMdOnOffDspCmd "Ambient Light Drive Mode On Off Display Command
";
CM_ SG_ 1051 AmbtLghtGlbOnOffDspCmd "Ambient Light Global On Off Display Command
";
CM_ SG_ 1051 AmbtLghtIgnMdDspCmd "Ambient Light Ignition Mode Display Command
";
CM_ SG_ 1051 AmbtLghtIgnMdOnOffDspCmd "Ambient Light Ignition Mode On Off Display Command
";
CM_ SG_ 1051 AmbtLghtLvl "Ambient Light Level
Indicate the Request from Auto Light Sensor";
CM_ SG_ 1051 AmbtLghtWlcmMdDspCmd "Ambient Light Welcome Mode Display Command
";
CM_ SG_ 1051 AmbtLghtWlcmMdOnOffDspCmd "Ambient Light Welcome Mode On Off Display Command
";
CM_ SG_ 1051 CotsyLghtA "Courtesy Light  Active
";
CM_ SG_ 937 AmbtLghtDrvMdCustDspCmd "Ambient Light Drive Mode Customization Display Command";
CM_ SG_ 938 AmbtLghtDrvMdCustDspCmd1 "Ambient Light Drive Mode Customization Display Command 1";
CM_ SG_ 556 BCMEmgcSp "Body Control Module Emergency Stop";
CM_ SG_ 556 BCMRunCrkF "Body Control Module Run Crank Failed
";
CM_ SG_ 556 BCMSSBA "Body Control Module Start Stop Button Active
";
CM_ SG_ 556 BCMSSBAV "Body Control Module Start Stop Button Active Validity
";
CM_ SG_ 556 BCMSSBFltSts "Body Control Module Start Stop Button Fault Status
";
CM_ SG_ 556 KeyDetIndx "Key Detected Index";
CM_ SG_ 556 RVSSts "Remote Vehicle Start Status
";
CM_ SG_ 556 ScurtKeyInvd "Security Key Invalid";
CM_ SG_ 556 SysBPM "System Backup Power Mode";
CM_ SG_ 556 SysBPMEnbd "System Backup Power Mode Enabled";
CM_ SG_ 1052 SIADateSecy "Service Interval Announcement Date Secondary

0x xx xx xx=(Year, Month, Date).

MSB:year,
LSB:day";
CM_ SG_ 135 LDircnIO "Left Direction Indication On
Remind the Driver that Left Hand Direction Indicate Light was On";
CM_ SG_ 135 RDircnIO "Right Direction Indication On
Remind the Driver that Right Hand Direction Indicate Light was On";
CM_ SG_ 554 DMSAdoWrnngDspCmd "Driver Monitor System Audio Warning Display Command";
CM_ SG_ 554 DMSAudReq "Driver Monitor System Audible Request";
CM_ SG_ 554 DMSDspCmd "Driver Monitor System Display Command";
CM_ SG_ 554 DMSHapticWrnngDspCmd "Driver Monitor System Haptic Warning Display Command";
CM_ SG_ 554 DMSWrnngReq "Driver Monitor System Warning Request";
CM_ SG_ 201 AccelActuPos "Accelerator Actual Position";
CM_ SG_ 201 AccelActuPosV "Accelerator Actual Position Validity";
CM_ SG_ 201 AccelEfctvPos "Accelerator Effective Position";
CM_ SG_ 201 CCA "Cruise Control Active";
CM_ SG_ 201 CCEnbd "Cruise Control Enabled";
CM_ SG_ 201 En12VoltStrMotCmddOn "Engine 12 Volt Starter Motor Commanded On";
CM_ SG_ 201 EnRunA "Engine Run Active";
CM_ SG_ 201 EnSpd "Engine Speed";
CM_ SG_ 201 EnSpdSts "Engine Speed Status";
CM_ SG_ 404 AutocTrCmddGear "Automatic Transmission Commanded Gear";
CM_ SG_ 404 CCP_025ms_ECM_PDU04_CRC "Wheel Ground Velocity Non Driven Checksum
Regarding high integrity requirement, a checksum signal is used for the bit field in same frame. The signal XOR operation is recommended for the calculation.";
CM_ SG_ 404 ClPos "Clutch Position";
CM_ SG_ 404 ClPosV "Clutch Position Validity";
CM_ SG_ 404 ClStSwA "Clutch Start Switch Active";
CM_ SG_ 404 ClStSwAV "Clutch Start Switch Active Validity";
CM_ SG_ 404 DrvrShftCtrlTrgtGear "Driver Shift Control Target Gear";
CM_ SG_ 404 TrEstdGear "Transmission Estimated Gear";
CM_ SG_ 404 TrEstdGearV "Transmission Estimated Gear Validity";
CM_ SG_ 404 TrShftPtrnASts "Transmission Shift Pattern Active Status";
CM_ SG_ 404 TrTapUpTapDwnMdSts "Transmission Tap Up Tap Down Mode Status";
CM_ SG_ 707 EcoDrvngAIO "Economy Driving Active Indication On";
CM_ SG_ 945 CCFltPrst "Cruise Control Fault Present";
CM_ SG_ 945 ECMClsDoorToAutoStR "Engine Control Module Close Door To Auto Start Reminder";
CM_ SG_ 945 ECMFasnSbltToAutoStR "Engine Control Module Fasten Seatbelt To Auto Start Reminder";
CM_ SG_ 945 ECMPressClBrkRmndr "Engine Control Module Press Clutch Brake Reminder";
CM_ SG_ 945 ECMShftNtrlToAutoStR "Engine Control Module Shift Neutral To Auto Start Reminder";
CM_ SG_ 945 KeyRestRqd "Key Restart Required";
CM_ SG_ 977 CrusAndSpdLmtrDrvrSeldSpd "Cruise and Speed Limiter Driver Selected Speed";
CM_ SG_ 977 EnEmsnRltdMalfA "Engine Emissions Related Malfunction Active";
CM_ SG_ 977 EnEmsnRltdMalfIndReq "Engine Emissions Related Malfunction Indication Request";
CM_ SG_ 977 EnGPFLampOnSts "Engine Gpf Lamp On Status";
CM_ SG_ 977 EnNonEmsnRltdMalfA "Engine Non Emissions Related Malfunction Active";
CM_ SG_ 977 FuelCsump "Fuel Consumption";
CM_ SG_ 1141 BarPrsAbs "Barometric Pressure Absolute";
CM_ SG_ 1141 BarPrsAbsV "Barometric Pressure Absolute Validity";
CM_ SG_ 1141 EnClntTem "Engine Coolant Temperature";
CM_ SG_ 1141 EnClntTemV "Engine Coolant Temperature Validity";
CM_ SG_ 1141 EnIntkAirTem "Engine Intake Air Temperature";
CM_ SG_ 85 EPS_010ms_PDU00_CRC "Wheel Ground Velocity Non Driven Checksum
Regarding high integrity requirement, a checksum signal is used for the bit field in same frame. The signal XOR operation is recommended for the calculation.";
CM_ SG_ 85 StrgWhlAng "Steering Wheel Angle";
CM_ SG_ 85 StrgWhlAngGrd "Steering Wheel Angle Gradient";
CM_ SG_ 85 StrgWhlAngSnsrCalSts "Steering Wheel Angle Sensor Calibration Status";
CM_ SG_ 85 StrgWhlAngSnsrFlt "Steering Wheel Angle Sensor Fault";
CM_ SG_ 85 StrgWhlAngSnsrInid "Steering Wheel Angle Sensor Initialized";
CM_ SG_ 85 StrgWhlAngSnsrMultCapb "Steering Wheel Angle Sensor Multiturn Capable";
CM_ SG_ 85 StrgWhlAngV "Steering Wheel Angle Validity";
CM_ SG_ 328 EPSIntAngInidDspReq "EPS Internal Angle Initialization Display Request";
CM_ SG_ 827 ACCDetObjExistPrblty "Adaptive Cruise Control Detected Object Exist Probability";
CM_ SG_ 827 ACCDetObjId "Adaptive Cruise Control Detected Object Identifier";
CM_ SG_ 827 ACCDetObjLatRltvDist "Adaptive Cruise Control Detected Object Lateral Relative Distance";
CM_ SG_ 827 ACCDetObjLongtRltvDist "Adaptive Cruise Control Detected Object Longitudinal Relative Distance";
CM_ SG_ 827 ACCDetObjLongtRltvSpd "Adaptive Cruise Control Detected Object Longitudinal Relative Speed";
CM_ SG_ 827 ACCDetObjRisk "Adaptive Cruise Control Detected Object 0 Risk";
CM_ SG_ 827 ACCDetObjSyncCtr "Adaptive Cruise Control Detected Object Synchronize Counter";
CM_ SG_ 826 ACCDetObj1Risk "Adaptive Cruise Control Detected Object 1 Risk";
CM_ SG_ 825 ACCDetObj2Risk "Adaptive Cruise Control Detected Object 2 Risk";
CM_ SG_ 824 ACCDetObj3Risk "Adaptive Cruise Control Detected Object 3 Risk";
CM_ SG_ 523 RdrCalPrgsReq "Radar Calibration Progress Request";
CM_ SG_ 988 Obj0ExistPrblty "Object 0 Exist Probability";
CM_ SG_ 988 Obj0Id "Object 0 Identifier";
CM_ SG_ 988 Obj0LatRltvDist "Object 0 Lateral Relative Distance";
CM_ SG_ 988 Obj0LongtRltvDist "Object 0 Longitudinal Relative Distance";
CM_ SG_ 988 Obj0LongtRltvSpd "Object 0 Longitudinal Relative Speed";
CM_ SG_ 988 Obj0Risk "Object 0 Risk";
CM_ SG_ 988 Obj0SyncCtr "Object 0 Synchronize Counter";
CM_ SG_ 988 Obj0Typ "Object 0 Type";
CM_ SG_ 988 Obs0ExistPrblty "Obstacle 0 Exist Probability";
CM_ SG_ 981 Obj1ExistPrblty "Object 1 Exist Probability";
CM_ SG_ 981 Obj1Id "Object 1 Identifier";
CM_ SG_ 981 Obj1LatRltvDist "Object 1 Lateral Relative Distance";
CM_ SG_ 981 Obj1LongtRltvDist "Object 1 Longitudinal Relative Distance";
CM_ SG_ 981 Obj1LongtRltvSpd "Object 1 Longitudinal Relative Speed";
CM_ SG_ 981 Obj1Risk "Object 1 Risk";
CM_ SG_ 981 Obj1SyncCtr "Object 1 Synchronize Counter";
CM_ SG_ 981 Obj1Typ "Object 1 Type";
CM_ SG_ 981 Obs1ExistPrblty "Obstacle 1 Exist Probability";
CM_ SG_ 983 Obj2ExistPrblty "Object 2 Exist Probability";
CM_ SG_ 983 Obj2Id "Object 2 Identifier";
CM_ SG_ 983 Obj2LatRltvDist "Object 2 Lateral Relative Distance";
CM_ SG_ 983 Obj2LongtRltvDist "Object 2 Longitudinal Relative Distance";
CM_ SG_ 983 Obj2LongtRltvSpd "Object 2 Longitudinal Relative Speed";
CM_ SG_ 983 Obj2Risk "Object 2 Risk";
CM_ SG_ 983 Obj2SyncCtr "Object 2 Synchronize Counter";
CM_ SG_ 983 Obj2Typ "Object 2 Type";
CM_ SG_ 983 Obs2ExistPrblty "Obstacle 2 Exist Probability";
CM_ SG_ 986 Obj3ExistPrblty "Object 3 Exist Probability";
CM_ SG_ 986 Obj3Id "Object 3 Identifier";
CM_ SG_ 986 Obj3LatRltvDist "Object 3 Lateral Relative Distance";
CM_ SG_ 986 Obj3LongtRltvDist "Object 3 Longitudinal Relative Distance";
CM_ SG_ 986 Obj3LongtRltvSpd "Object 3 Longitudinal Relative Speed";
CM_ SG_ 986 Obj3Risk "Object 3 Risk";
CM_ SG_ 986 Obj3SyncCtr "Object 3 Synchronize Counter";
CM_ SG_ 986 Obj3Typ "Object 3 Type";
CM_ SG_ 986 Obs3ExistPrblty "Obstacle 3 Exist Probability";
BA_DEF_ BO_ "GenMsgSendType" ENUM "cyclic","spontaneous","cyclicIfActive","spontaneousWithDelay","cyclicAndSpontaneous","cyclicAndSpontaneousWithDelay","IfActive","NoMsgSendType"; // [us]
BA_DEF_ BO_ "GenMsgCycleTime" FLOAT 0 300000; // [ms]
BA_DEF_ BO_ "GenMsgStartDelayTime" FLOAT 0 300000; // [ms]
BA_DEF_ BO_ "GenMsgDelayTime" FLOAT 0 300000; // [ms]
BA_DEF_ SG_ "GenSigSendType" ENUM "Cyclic","OnWrite","OnWriteWithRepetition","OnChange","OnChangeWithRepetition","IfActive","IfActiveWithRepetition","NoSigSendType";
BA_DEF_ SG_ "GenSigStartValue" FLOAT -1.7976931348623157E308 18446744073709551615;

BA_DEF_DEF_ "GenSigStartValue" 0;
BA_DEF_DEF_ "GenSigSendType" "Cyclic";
// Frame: ICM_CFCAN_FrS15
BA_ "GenMsgSendType" BO_ 88 1;
BA_ "GenSigStartValue" SG_ 88 HUDBrtnsManuAdjtReq 11;
BA_ "GenSigStartValue" SG_ 88 HUDVertPosManuAdjtReq 11;
// Frame: ICM_CFCAN_FrS17
BA_ "GenMsgSendType" BO_ 98 1;
// Frame: ICM_CFCAN_NM
BA_ "GenMsgSendType" BO_ 1218 1;
BA_ "GenMsgDelayTime" BO_ 1218 10.000;
// Frame: IPK_CFCAN_FrP01
BA_ "GenMsgSendType" BO_ 1142 0;
BA_ "GenMsgCycleTime" BO_ 1142 200.000;
BA_ "GenMsgStartDelayTime" BO_ 1142 15.000;
// Frame: IPK_CFCAN_FrP03
BA_ "GenMsgSendType" BO_ 1073 0;
BA_ "GenMsgCycleTime" BO_ 1073 200.000;
BA_ "GenMsgStartDelayTime" BO_ 1073 15.000;
// Frame: IPK_CFCAN_FrP04
BA_ "GenMsgSendType" BO_ 402 0;
BA_ "GenMsgCycleTime" BO_ 402 25.000;
BA_ "GenMsgStartDelayTime" BO_ 402 15.000;
// Frame: IPK_CFCAN_FrP05
BA_ "GenMsgSendType" BO_ 1134 0;
BA_ "GenMsgCycleTime" BO_ 1134 200.000;
BA_ "GenMsgStartDelayTime" BO_ 1134 20.000;
// Frame: IPK_CFCAN_FrP06
BA_ "GenMsgSendType" BO_ 1345 0;
BA_ "GenMsgCycleTime" BO_ 1345 200.000;
BA_ "GenMsgStartDelayTime" BO_ 1345 20.000;
BA_ "GenSigStartValue" SG_ 1345 IPK_200ms_PDU06_Reserve01 255;
BA_ "GenSigStartValue" SG_ 1345 IPK_200ms_PDU06_Reserve02 7;
BA_ "GenSigStartValue" SG_ 1345 IPK_200ms_PDU06_Reserve03 7;
BA_ "GenSigStartValue" SG_ 1345 IPK_200ms_PDU06_Reserve04 3;
BA_ "GenSigStartValue" SG_ 1345 IPK_200ms_PDU06_Reserve05 1;
// Frame: IPK_CFCAN_FrP07
BA_ "GenMsgSendType" BO_ 817 0;
BA_ "GenMsgCycleTime" BO_ 817 100.000;
BA_ "GenMsgStartDelayTime" BO_ 817 5.000;
BA_ "GenSigStartValue" SG_ 817 ClstrCardDspMd 1;
BA_ "GenSigStartValue" SG_ 817 ClstrDimLghtLvl 2;
BA_ "GenSigStartValue" SG_ 817 ClstrThemeTyp 1;
BA_ "GenSigStartValue" SG_ 817 IPK_100ms_PDU07_Reserve02 4095;
// Frame: IPK_CFCAN_FrP08
BA_ "GenMsgSendType" BO_ 874 0;
BA_ "GenMsgCycleTime" BO_ 874 100.000;
BA_ "GenMsgStartDelayTime" BO_ 874 0.000;
// Frame: IPK_CFCAN_FrP09
BA_ "GenMsgSendType" BO_ 1047 0;
BA_ "GenMsgCycleTime" BO_ 1047 200.000;
BA_ "GenMsgStartDelayTime" BO_ 1047 0.000;
// Frame: IPK_CFCAN_FrP10
BA_ "GenMsgSendType" BO_ 1144 0;
BA_ "GenMsgCycleTime" BO_ 1144 200.000;
BA_ "GenMsgStartDelayTime" BO_ 1144 25.000;
BA_ "GenSigStartValue" SG_ 1144 FuelLvlSnsrFlrStsInvsn 3;
// Frame: IPK_CFCAN_FrP15
BA_ "GenMsgSendType" BO_ 1031 0;
BA_ "GenMsgCycleTime" BO_ 1031 200.000;
BA_ "GenMsgStartDelayTime" BO_ 1031 25.000;
// Frame: IPK_CFCAN_FrP17
BA_ "GenMsgSendType" BO_ 1360 0;
BA_ "GenMsgCycleTime" BO_ 1360 500.000;
BA_ "GenMsgStartDelayTime" BO_ 1360 5.000;
BA_ "GenSigStartValue" SG_ 1360 AvgFuelCsumpV 1;
// Frame: IPK_CFCAN_FrP31
BA_ "GenMsgSendType" BO_ 537 0;
BA_ "GenMsgCycleTime" BO_ 537 50.000;
BA_ "GenMsgStartDelayTime" BO_ 537 0.000;
BA_ "GenSigStartValue" SG_ 537 IPK_050ms_PDU31_Reserve01 16777215;
BA_ "GenSigStartValue" SG_ 537 IPK_050ms_PDU31_Reserve02 16777215;
// Frame: AC_CFCAN_FrP04
BA_ "GenMsgSendType" BO_ 672 0;
BA_ "GenMsgCycleTime" BO_ 672 50.000;
BA_ "GenMsgStartDelayTime" BO_ 672 5.000;
// Frame: AC_CFCAN_FrP05
BA_ "GenMsgSendType" BO_ 892 0;
BA_ "GenMsgCycleTime" BO_ 892 100.000;
BA_ "GenMsgStartDelayTime" BO_ 892 25.000;
BA_ "GenSigStartValue" SG_ 892 InsdAirPrtclMtrCncntrnDspCmd 253;
// Frame: AC_CFCAN_FrP06
BA_ "GenMsgSendType" BO_ 893 0;
BA_ "GenMsgCycleTime" BO_ 893 100.000;
BA_ "GenMsgStartDelayTime" BO_ 893 30.000;
BA_ "GenSigStartValue" SG_ 893 ACUserCustAftRunOnOffDspCmd 3;
BA_ "GenSigStartValue" SG_ 893 ACUserCustAirQultEnbDspCmd 3;
BA_ "GenSigStartValue" SG_ 893 ACUserCustAutoMdBlwrDspCmd 3;
BA_ "GenSigStartValue" SG_ 893 ACUserCustAutoMdTemDspCmd 3;
BA_ "GenSigStartValue" SG_ 893 ACUserCustBlwrAutoRunRmtUnlckDspCmd 3;
BA_ "GenSigStartValue" SG_ 893 ACUserCustCofignDspCmd 4;
BA_ "GenSigStartValue" SG_ 893 ACUserCustEcoSetngDspCmd 3;
BA_ "GenSigStartValue" SG_ 893 ACUserCustFltrLifeRmndDspCmd 3;
BA_ "GenSigStartValue" SG_ 893 ACUserCustFrtAutoDmstngDspCmd 3;
BA_ "GenSigStartValue" SG_ 893 ACUserCustRmtStOnOffDspCmd 3;
BA_ "GenSigStartValue" SG_ 893 ACUserCustRrAutoDmstngDspCmd 3;
BA_ "GenSigStartValue" SG_ 893 ACUserCustRrZoneCofignDspCmd 3;
BA_ "GenSigStartValue" SG_ 893 ACUserCustStSpMdDspCmd 3;
BA_ "GenSigStartValue" SG_ 893 ACUserCustTemUnitDspCmd 3;
BA_ "GenSigStartValue" SG_ 893 ACUserCustZoneCofignDspCmd 3;
BA_ "GenSigStartValue" SG_ 893 AirClnrUserCustAutoRDC 3;
// Frame: AC_CFCAN_FrP07
BA_ "GenMsgSendType" BO_ 894 0;
BA_ "GenMsgCycleTime" BO_ 894 100.000;
BA_ "GenMsgStartDelayTime" BO_ 894 20.000;
BA_ "GenSigStartValue" SG_ 894 ACDrvrAirMdDspCmd 7;
BA_ "GenSigStartValue" SG_ 894 ACDrvrTemDspCmd 31;
BA_ "GenSigStartValue" SG_ 894 ACPsngAirMdDspCmd 7;
BA_ "GenSigStartValue" SG_ 894 ACPsngTemDspCmd 31;
// Frame: AC_CFCAN_FrP10
BA_ "GenMsgSendType" BO_ 936 0;
BA_ "GenMsgCycleTime" BO_ 936 100.000;
BA_ "GenMsgStartDelayTime" BO_ 936 35.000;
BA_ "GenSigStartValue" SG_ 936 ACFrtBlwrSpdDspCmd 15;
BA_ "GenSigStartValue" SG_ 936 ACLAirMdDspCmd 7;
BA_ "GenSigStartValue" SG_ 936 ACLTemDspCmd 31;
BA_ "GenSigStartValue" SG_ 936 ACRAirMdDspCmd 7;
BA_ "GenSigStartValue" SG_ 936 ACRcctnDspMd 1;
BA_ "GenSigStartValue" SG_ 936 ACRrAirMdDspCmd 7;
BA_ "GenSigStartValue" SG_ 936 ACRrTemDspCmd 31;
BA_ "GenSigStartValue" SG_ 936 ACRTemDspCmd 31;
// Frame: AC_CFCAN_FrP11
BA_ "GenMsgSendType" BO_ 1361 0;
BA_ "GenMsgCycleTime" BO_ 1361 500.000;
BA_ "GenMsgStartDelayTime" BO_ 1361 5.000;
BA_ "GenSigStartValue" SG_ 1361 OtsdAirPrtclMtrCncntrnDspCmd 254;
BA_ "GenSigStartValue" SG_ 1361 OtsdAirQultStsV 1;
// Frame: AC_CFCAN_FrP12
BA_ "GenMsgSendType" BO_ 1509 0;
BA_ "GenMsgCycleTime" BO_ 1509 1000.000;
BA_ "GenMsgStartDelayTime" BO_ 1509 5.000;
BA_ "GenSigStartValue" SG_ 1509 ACAmbtTemMsk 1;
BA_ "GenSigStartValue" SG_ 1509 ACAmbtTemV 1;
BA_ "GenSigStartValue" SG_ 1509 ACInCarTem 254;
BA_ "GenSigStartValue" SG_ 1509 ACInCarTemV 1;
BA_ "GenSigStartValue" SG_ 1509 AirClnrFltrLifeV 1;
// Frame: AC_CFCAN_FrP14
BA_ "GenMsgSendType" BO_ 993 0;
BA_ "GenMsgCycleTime" BO_ 993 100.000;
BA_ "GenMsgStartDelayTime" BO_ 993 0.000;
BA_ "GenSigStartValue" SG_ 993 OtsdAirPrtclMtrCDC 253;
// Frame: AMP_CFCAN_FrP01
BA_ "GenMsgSendType" BO_ 837 0;
BA_ "GenMsgCycleTime" BO_ 837 100.000;
BA_ "GenMsgStartDelayTime" BO_ 837 0.000;
BA_ "GenSigStartValue" SG_ 837 AMPWorkSta 1;
// Frame: AMP_CFCAN_FrS00
BA_ "GenMsgSendType" BO_ 43 1;
BA_ "GenMsgDelayTime" BO_ 43 5.000;
BA_ "GenSigStartValue" SG_ 43 AllMuteFdbk 1;
BA_ "GenSigSendType" SG_ 43 AllMuteFdbk 1;
BA_ "GenSigSendType" SG_ 43 AutocVolmCmpstnFdbk 1;
BA_ "GenSigStartValue" SG_ 43 BalcSetngFdbk 7;
BA_ "GenSigSendType" SG_ 43 BalcSetngFdbk 1;
BA_ "GenSigStartValue" SG_ 43 BassFdbk 7;
BA_ "GenSigSendType" SG_ 43 BassFdbk 1;
BA_ "GenSigStartValue" SG_ 43 ChmSndVolmStepFdbk 7;
BA_ "GenSigSendType" SG_ 43 ChmSndVolmStepFdbk 1;
BA_ "GenSigStartValue" SG_ 43 FdrSetngFdbk 7;
BA_ "GenSigSendType" SG_ 43 FdrSetngFdbk 1;
BA_ "GenSigStartValue" SG_ 43 MdaMuteFdbk 1;
BA_ "GenSigSendType" SG_ 43 MdaMuteFdbk 1;
BA_ "GenSigStartValue" SG_ 43 MdaSndVolmStepFdbk 15;
BA_ "GenSigSendType" SG_ 43 MdaSndVolmStepFdbk 1;
BA_ "GenSigStartValue" SG_ 43 MedFdbk 7;
BA_ "GenSigSendType" SG_ 43 MedFdbk 1;
BA_ "GenSigStartValue" SG_ 43 NavSndVolmStepFdbk 8;
BA_ "GenSigSendType" SG_ 43 NavSndVolmStepFdbk 1;
BA_ "GenSigStartValue" SG_ 43 PhnCallSndVolmStepFdbk 15;
BA_ "GenSigSendType" SG_ 43 PhnCallSndVolmStepFdbk 1;
BA_ "GenSigStartValue" SG_ 43 SpdDpntAutocVolmFdbk 2;
BA_ "GenSigSendType" SG_ 43 SpdDpntAutocVolmFdbk 1;
BA_ "GenSigStartValue" SG_ 43 ThreeDimnSndFldFdbk 1;
BA_ "GenSigSendType" SG_ 43 ThreeDimnSndFldFdbk 1;
BA_ "GenSigStartValue" SG_ 43 TrblFdbk 7;
BA_ "GenSigSendType" SG_ 43 TrblFdbk 1;
BA_ "GenSigStartValue" SG_ 43 VcItatnSndVolmStepFdbk 8;
BA_ "GenSigSendType" SG_ 43 VcItatnSndVolmStepFdbk 1;
// Frame: AMP_CFCAN_FrS02
BA_ "GenMsgSendType" BO_ 1553 1;
BA_ "GenMsgDelayTime" BO_ 1553 5.000;
BA_ "GenSigSendType" SG_ 1553 AMPASndWaveSelSts 1;
BA_ "GenSigStartValue" SG_ 1553 AMPASndWaveSts 2;
BA_ "GenSigSendType" SG_ 1553 AMPASndWaveSts 1;
BA_ "GenSigStartValue" SG_ 1553 AMPASndWaveVolmSwSts 6;
BA_ "GenSigSendType" SG_ 1553 AMPASndWaveVolmSwSts 1;
BA_ "GenSigStartValue" SG_ 1553 AMPICMInfoStsSyn 1;
BA_ "GenSigSendType" SG_ 1553 AMPICMInfoStsSyn 1;
BA_ "GenSigSendType" SG_ 1553 ANCOnOffFdbk 1;
// Frame: AVM_CFCAN_FrP01
BA_ "GenMsgSendType" BO_ 521 0;
BA_ "GenMsgCycleTime" BO_ 521 50.000;
BA_ "GenMsgStartDelayTime" BO_ 521 0.000;
// Frame: AVM_CFCAN_FrP02
BA_ "GenMsgSendType" BO_ 559 0;
BA_ "GenMsgCycleTime" BO_ 559 50.000;
BA_ "GenMsgStartDelayTime" BO_ 559 5.000;
// Frame: AVM_CFCAN_FrP03
BA_ "GenMsgSendType" BO_ 909 0;
BA_ "GenMsgCycleTime" BO_ 909 100.000;
BA_ "GenMsgStartDelayTime" BO_ 909 30.000;
BA_ "GenSigStartValue" SG_ 909 CBDActvdSpdSetngVal 3;
BA_ "GenSigStartValue" SG_ 909 CBDSysSelSts 2;
BA_ "GenSigStartValue" SG_ 909 CLWActdSpdSetngVal 3;
BA_ "GenSigStartValue" SG_ 909 RrViewInfoAstntActvdSpdSetngVal 3;
// Frame: BCM_CFCAN_FrP01
BA_ "GenMsgSendType" BO_ 691 0;
BA_ "GenMsgCycleTime" BO_ 691 50.000;
BA_ "GenMsgStartDelayTime" BO_ 691 15.000;
BA_ "GenSigStartValue" SG_ 691 BCMPDCCofignSts 1;
// Frame: BCM_CFCAN_FrP03
BA_ "GenMsgSendType" BO_ 822 0;
BA_ "GenMsgCycleTime" BO_ 822 100.000;
BA_ "GenMsgStartDelayTime" BO_ 822 25.000;
BA_ "GenSigStartValue" SG_ 822 DrvrWndDclnSpc 255;
BA_ "GenSigStartValue" SG_ 822 FrtPsngWndDclnSpc 255;
BA_ "GenSigStartValue" SG_ 822 RLWndDclnSpc 255;
BA_ "GenSigStartValue" SG_ 822 RRWndDclnSpc 255;
BA_ "GenSigStartValue" SG_ 822 SrfSlidePosSts 15;
// Frame: BCM_CFCAN_FrP04
BA_ "GenMsgSendType" BO_ 815 0;
BA_ "GenMsgCycleTime" BO_ 815 100.000;
BA_ "GenMsgStartDelayTime" BO_ 815 30.000;
BA_ "GenSigStartValue" SG_ 815 VehLckngSta 7;
// Frame: BCM_CFCAN_FrP05
BA_ "GenMsgSendType" BO_ 830 0;
BA_ "GenMsgCycleTime" BO_ 830 100.000;
BA_ "GenMsgStartDelayTime" BO_ 830 20.000;
// Frame: BCM_CFCAN_FrP08
BA_ "GenMsgSendType" BO_ 804 0;
BA_ "GenMsgCycleTime" BO_ 804 100.000;
BA_ "GenMsgStartDelayTime" BO_ 804 35.000;
// Frame: BCM_CFCAN_FrP09
BA_ "GenMsgSendType" BO_ 1125 0;
BA_ "GenMsgCycleTime" BO_ 1125 200.000;
BA_ "GenMsgStartDelayTime" BO_ 1125 50.000;
// Frame: BCM_CFCAN_FrP10
BA_ "GenMsgSendType" BO_ 1136 0;
BA_ "GenMsgCycleTime" BO_ 1136 200.000;
BA_ "GenMsgStartDelayTime" BO_ 1136 50.000;
// Frame: BCM_CFCAN_FrP11
BA_ "GenMsgSendType" BO_ 1040 0;
BA_ "GenMsgCycleTime" BO_ 1040 200.000;
BA_ "GenMsgStartDelayTime" BO_ 1040 55.000;
// Frame: BCM_CFCAN_FrP12
BA_ "GenMsgSendType" BO_ 1139 0;
BA_ "GenMsgCycleTime" BO_ 1139 200.000;
BA_ "GenMsgStartDelayTime" BO_ 1139 55.000;
BA_ "GenSigStartValue" SG_ 1139 VINBCM 255;
// Frame: BCM_CFCAN_FrP13
BA_ "GenMsgSendType" BO_ 1127 0;
BA_ "GenMsgCycleTime" BO_ 1127 200.000;
BA_ "GenMsgStartDelayTime" BO_ 1127 55.000;
// Frame: BCM_CFCAN_FrP36
BA_ "GenMsgSendType" BO_ 1051 0;
BA_ "GenMsgCycleTime" BO_ 1051 200.000;
BA_ "GenMsgStartDelayTime" BO_ 1051 60.000;
BA_ "GenSigStartValue" SG_ 1051 AmbtLghtDrvMdOnOffDspCmd 3;
BA_ "GenSigStartValue" SG_ 1051 AmbtLghtGlbOnOffDspCmd 1;
BA_ "GenSigStartValue" SG_ 1051 AmbtLghtIgnMdOnOffDspCmd 1;
BA_ "GenSigStartValue" SG_ 1051 AmbtLghtWlcmMdOnOffDspCmd 1;
// Frame: BCM_CFCAN_FrP37
BA_ "GenMsgSendType" BO_ 937 0;
BA_ "GenMsgCycleTime" BO_ 937 100.000;
BA_ "GenMsgStartDelayTime" BO_ 937 35.000;
// Frame: BCM_CFCAN_FrP38
BA_ "GenMsgSendType" BO_ 938 0;
BA_ "GenMsgCycleTime" BO_ 938 100.000;
BA_ "GenMsgStartDelayTime" BO_ 938 40.000;
// Frame: BCM_CFCAN_FrP40
BA_ "GenMsgSendType" BO_ 556 0;
BA_ "GenMsgCycleTime" BO_ 556 50.000;
BA_ "GenMsgStartDelayTime" BO_ 556 10.000;
BA_ "GenSigStartValue" SG_ 556 ScurtKeyInvd 1;
// Frame: BCM_CFCAN_FrP41
BA_ "GenMsgSendType" BO_ 1052 0;
BA_ "GenMsgCycleTime" BO_ 1052 200.000;
BA_ "GenMsgStartDelayTime" BO_ 1052 60.000;
// Frame: BCM_CFCAN_FrP42
BA_ "GenMsgSendType" BO_ 135 0;
BA_ "GenMsgCycleTime" BO_ 135 10.000;
BA_ "GenMsgStartDelayTime" BO_ 135 0.000;
// Frame: BCM_CFCAN_FrP43
BA_ "GenMsgSendType" BO_ 720 0;
BA_ "GenMsgCycleTime" BO_ 720 50.000;
BA_ "GenMsgStartDelayTime" BO_ 720 0.000;
// Frame: BCM_CFCAN_FrP48
BA_ "GenMsgSendType" BO_ 851 0;
BA_ "GenMsgCycleTime" BO_ 851 100.000;
BA_ "GenMsgStartDelayTime" BO_ 851 0.000;
BA_ "GenSigStartValue" SG_ 851 LOtsdMirHoztPos 127;
BA_ "GenSigStartValue" SG_ 851 LOtsdMirVertPos 127;
BA_ "GenSigStartValue" SG_ 851 ROtsdMirHoztPos 127;
BA_ "GenSigStartValue" SG_ 851 ROtsdMirVertPos 127;
// Frame: BCM_CFCAN_FrP51
BA_ "GenMsgSendType" BO_ 879 0;
BA_ "GenMsgCycleTime" BO_ 879 100.000;
BA_ "GenMsgStartDelayTime" BO_ 879 0.000;
// Frame: BPEPS_CFCAN_FrP01
BA_ "GenMsgSendType" BO_ 577 0;
BA_ "GenMsgCycleTime" BO_ 577 100.000;
BA_ "GenMsgStartDelayTime" BO_ 577 20.000;
// Frame: BPEPS_CFCAN_FrP08
BA_ "GenMsgSendType" BO_ 1022 0;
BA_ "GenMsgCycleTime" BO_ 1022 100.000;
BA_ "GenMsgStartDelayTime" BO_ 1022 0.000;
// Frame: CCP_CFCAN_DMS_FrP00
BA_ "GenMsgSendType" BO_ 554 1;
BA_ "GenMsgDelayTime" BO_ 554 50.000;
BA_ "GenSigStartValue" SG_ 554 DMSAdoWrnngDspCmd 2;
BA_ "GenSigStartValue" SG_ 554 DMSDspCmd 2;
BA_ "GenSigStartValue" SG_ 554 DMSHapticWrnngDspCmd 2;
// Frame: CCP_CFCAN_ECM_FrP00
BA_ "GenMsgSendType" BO_ 201 1;
BA_ "GenMsgDelayTime" BO_ 201 10.000;
// Frame: CCP_CFCAN_ECM_FrP04
BA_ "GenMsgSendType" BO_ 404 0;
BA_ "GenMsgCycleTime" BO_ 404 25.000;
BA_ "GenMsgStartDelayTime" BO_ 404 5.000;
BA_ "GenSigStartValue" SG_ 404 CCP_025ms_ECM_PDU04_Reserve01 7;
BA_ "GenSigStartValue" SG_ 404 CCP_025ms_ECM_PDU04_Reserve02 1;
BA_ "GenSigStartValue" SG_ 404 CCP_025ms_ECM_PDU04_Reserve03 31;
BA_ "GenSigStartValue" SG_ 404 CCP_025ms_ECM_PDU04_Reserve04 3;
BA_ "GenSigStartValue" SG_ 404 CCP_025ms_ECM_PDU04_Reserve05 127;
// Frame: CCP_CFCAN_ECM_FrP09
BA_ "GenMsgSendType" BO_ 707 1;
BA_ "GenMsgDelayTime" BO_ 707 50.000;
// Frame: CCP_CFCAN_ECM_FrP10
BA_ "GenMsgSendType" BO_ 945 1;
BA_ "GenMsgDelayTime" BO_ 945 10.000;
// Frame: CCP_CFCAN_ECM_FrP12
BA_ "GenMsgSendType" BO_ 977 1;
BA_ "GenMsgDelayTime" BO_ 977 10.000;
// Frame: CCP_CFCAN_ECM_FrP14
BA_ "GenMsgSendType" BO_ 1141 1;
BA_ "GenMsgDelayTime" BO_ 1141 500.000;
BA_ "GenSigStartValue" SG_ 1141 BarPrsAbs 200;
BA_ "GenSigStartValue" SG_ 1141 BarPrsAbsV 1;
// Frame: CCP_CFCAN_ECM_FrP26
BA_ "GenMsgSendType" BO_ 884 0;
BA_ "GenMsgCycleTime" BO_ 884 100.000;
BA_ "GenMsgStartDelayTime" BO_ 884 0.000;
// Frame: CCP_CFCAN_EPS_FrP00
BA_ "GenMsgSendType" BO_ 85 1;
BA_ "GenMsgDelayTime" BO_ 85 10.000;
BA_ "GenSigStartValue" SG_ 85 EPS_010ms_PDU00_Reserve01 262143;
// Frame: CCP_CFCAN_EPS_FrP02
BA_ "GenMsgSendType" BO_ 328 1;
BA_ "GenMsgDelayTime" BO_ 328 10.000;
// Frame: CCP_CFCAN_FDR_FrP01
BA_ "GenMsgSendType" BO_ 827 1;
BA_ "GenMsgDelayTime" BO_ 827 10.000;
// Frame: CCP_CFCAN_FDR_FrP02
BA_ "GenMsgSendType" BO_ 826 1;
BA_ "GenMsgDelayTime" BO_ 826 10.000;
// Frame: CCP_CFCAN_FDR_FrP03
BA_ "GenMsgSendType" BO_ 825 1;
BA_ "GenMsgDelayTime" BO_ 825 10.000;
// Frame: CCP_CFCAN_FDR_FrP04
BA_ "GenMsgSendType" BO_ 824 1;
BA_ "GenMsgDelayTime" BO_ 824 10.000;
// Frame: CCP_CFCAN_FDR_FrP07
BA_ "GenMsgSendType" BO_ 466 1;
BA_ "GenMsgDelayTime" BO_ 466 10.000;
BA_ "GenSigStartValue" SG_ 466 AEBDspCmd 2;
BA_ "GenSigStartValue" SG_ 466 FCWDspCmd 2;
BA_ "GenSigStartValue" SG_ 466 FCWSnstvtLvl 2;
// Frame: CCP_CFCAN_FDR_FrP11
BA_ "GenMsgSendType" BO_ 523 0;
BA_ "GenMsgCycleTime" BO_ 523 50.000;
BA_ "GenMsgStartDelayTime" BO_ 523 5.000;
BA_ "GenSigStartValue" SG_ 523 ACCDrvrSeldTrgtDistLvl 3;
// Frame: CCP_CFCAN_FDR_FrP14
BA_ "GenMsgSendType" BO_ 988 1;
BA_ "GenMsgDelayTime" BO_ 988 100.000;
// Frame: CCP_CFCAN_FDR_FrP15
BA_ "GenMsgSendType" BO_ 981 1;
BA_ "GenMsgDelayTime" BO_ 981 100.000;
// Frame: CCP_CFCAN_FDR_FrP16
BA_ "GenMsgSendType" BO_ 983 1;
BA_ "GenMsgDelayTime" BO_ 983 100.000;
// Frame: CCP_CFCAN_FDR_FrP17
BA_ "GenMsgSendType" BO_ 986 1;
BA_ "GenMsgDelayTime" BO_ 986 100.000;
VAL_ 88 HUDBrtnsAdjtMd 0 "HUDBrtnsAdjtMd_0_auto_mode" 1 "HUDBrtnsAdjtMd_1_manual_mode";
VAL_ 88 HUDBrtnsManuAdjtReq 0 "HUDBrtnsManuAdjtReq_0_unavailable" 1 "HUDBrtnsManuAdjtReq_1_level1" 2 "HUDBrtnsManuAdjtReq_2_level2" 3 "HUDBrtnsManuAdjtReq_3_level3" 4 "HUDBrtnsManuAdjtReq_4_level4" 5 "HUDBrtnsManuAdjtReq_5_level5" 6 "HUDBrtnsManuAdjtReq_6_level6" 7 "HUDBrtnsManuAdjtReq_7_level7" 8 "HUDBrtnsManuAdjtReq_8_level8" 9 "HUDBrtnsManuAdjtReq_9_level9" 10 "HUDBrtnsManuAdjtReq_10_level10" 11 "HUDBrtnsManuAdjtReq_11_level11" 12 "HUDBrtnsManuAdjtReq_12_level12" 13 "HUDBrtnsManuAdjtReq_13_level13" 14 "HUDBrtnsManuAdjtReq_14_level14" 15 "HUDBrtnsManuAdjtReq_15_level15" 16 "HUDBrtnsManuAdjtReq_16_level16" 17 "HUDBrtnsManuAdjtReq_17_level17" 18 "HUDBrtnsManuAdjtReq_18_level18" 19 "HUDBrtnsManuAdjtReq_19_level19" 20 "HUDBrtnsManuAdjtReq_20_level20" 21 "HUDBrtnsManuAdjtReq_21_level21";
VAL_ 88 HudColSetngMdReq 0 "HudColSetngMdReq_0_color1" 1 "HudColSetngMdReq_1_color2" 2 "HudColSetngMdReq_2_color2" 3 "HudColSetngMdReq_3_color3";
VAL_ 88 HudStAniSetngReq 0 "HudStAniSetngReq_0_animation1" 1 "HudStAniSetngReq_1_animation2" 2 "HudStAniSetngReq_2_animation3" 3 "HudStAniSetngReq_3_animation4";
VAL_ 88 HUDSwReq 0 "HUDSwReq_0_no_request" 1 "HUDSwReq_1_on_request" 2 "HUDSwReq_2_off_request" 3 "HUDSwReq_3_reserved";
VAL_ 88 HudThemeSetMdReq 0 "HudThemeSetMdReq_0_normal" 1 "HudThemeSetMdReq_1_sport" 2 "HudThemeSetMdReq_2_snow" 3 "HudThemeSetMdReq_3_customization";
VAL_ 88 HUDVertPosAutoAdjtSwReq 0 "HUDVertPosAutoAdjtSwReq_0_no_request" 1 "HUDVertPosAutoAdjtSwReq_1_on_request" 2 "HUDVertPosAutoAdjtSwReq_2_off_request" 3 "HUDVertPosAutoAdjtSwReq_3_reserved";
VAL_ 88 HUDVertPosManuAdjtReq 0 "HUDVertPosManuAdjtReq_0_unavailable" 1 "HUDVertPosManuAdjtReq_1_level1" 2 "HUDVertPosManuAdjtReq_2_level2" 3 "HUDVertPosManuAdjtReq_3_level3" 4 "HUDVertPosManuAdjtReq_4_level4" 5 "HUDVertPosManuAdjtReq_5_level5" 6 "HUDVertPosManuAdjtReq_6_level6" 7 "HUDVertPosManuAdjtReq_7_level7" 8 "HUDVertPosManuAdjtReq_8_level8" 9 "HUDVertPosManuAdjtReq_9_level9" 10 "HUDVertPosManuAdjtReq_10_level10" 11 "HUDVertPosManuAdjtReq_11_level11" 12 "HUDVertPosManuAdjtReq_12_level12" 13 "HUDVertPosManuAdjtReq_13_level13" 14 "HUDVertPosManuAdjtReq_14_level14" 15 "HUDVertPosManuAdjtReq_15_level15" 16 "HUDVertPosManuAdjtReq_16_level16" 17 "HUDVertPosManuAdjtReq_17_level17" 18 "HUDVertPosManuAdjtReq_18_level18" 19 "HUDVertPosManuAdjtReq_19_level19" 20 "HUDVertPosManuAdjtReq_20_level20" 21 "HUDVertPosManuAdjtReq_21_level21";
VAL_ 98 NavFrmData 0 "NavFrmData_0_destination_data" 1 "NavFrmData_1_local_data";
VAL_ 98 NavFrmTyp 0 "NavFrmTyp_0_single_frame_data" 1 "NavFrmTyp_1_first_frame_data" 2 "NavFrmTyp_2_middle_frame_data" 3 "NavFrmTyp_3_last_frame_data";
VAL_ 1073 AirbagWrnngIndF 0 "False" 1 "True";
VAL_ 1073 Clstr10KmTick 0 "False" 1 "True";
VAL_ 1073 FuelLvlPcntV 0 "Valid" 1 "Invalid";
VAL_ 402 ChmCmdSndTone 0 "ChmCmdSndTone_0_Clack" 1 "ChmCmdSndTone_1_Click" 2 "ChmCmdSndTone_2_Beep_750_Hz_" 3 "ChmCmdSndTone_3_Beep_2000_Hz_" 4 "ChmCmdSndTone_4_Gong_750_Hz_" 5 "ChmCmdSndTone_5_Gong_2000_Hz_" 6 "ChmCmdSndTone_6_Reserved" 7 "ChmCmdSndTone_7_Reserved" 8 "ChmCmdSndTone_8_Reserved" 9 "ChmCmdSndTone_9_Reserved" 10 "ChmCmdSndTone_10_Reserved" 11 "ChmCmdSndTone_11_Reserved" 12 "ChmCmdSndTone_12_Reserved" 13 "ChmCmdSndTone_13_Reserved" 14 "ChmCmdSndTone_14_Reserved" 15 "ChmCmdSndTone_15_Reserved";
VAL_ 402 ClstrDspdVehSpd 255 "ClstrDspdVehSpd_Speed_Signal_Missing_Error_of_SCS";
VAL_ 402 DspMeasSys 0 "DspMeasSys_kph" 1 "DspMeasSys_mph";
VAL_ 1345 CalendarMonth 0 "CalendarMonth_0_Unknown" 1 "January" 2 "February" 3 "March" 4 "April" 5 "May" 6 "June" 7 "July" 8 "August" 9 "September" 10 "October" 11 "November" 12 "December";
VAL_ 1345 TimeDspFmt 0 "TimeDspFmt_12_hour_mode" 1 "TimeDspFmt_24_hour_mode";
VAL_ 817 ClstrCardDspMd 0 "ClstrCardDspMd_0_invalid" 1 "ClstrCardDspMd_1_Simple_Mode" 2 "ClstrCardDspMd_2_Custom_Mode" 3 "ClstrCardDspMd_3_Resrved";
VAL_ 817 ClstrDimLghtLvl 0 "ClstrDimLghtLvl_0_invalid" 1 "ClstrDimLghtLvl_1_Low" 2 "ClstrDimLghtLvl_2_Middle" 3 "ClstrDimLghtLvl_3_high";
VAL_ 817 ClstrThemeTyp 0 "ClstrThemeTyp_0_invalid" 1 "ClstrThemeTyp_1_Classic_display_Mode" 2 "ClstrThemeTyp_2_Navi_display_Mode" 3 "ClstrThemeTyp_3_ADAS_display_Mode";
VAL_ 817 IPCEcoDrvngSwA 0 "False" 1 "True";
VAL_ 817 ParkBrkSwA 0 "False" 1 "True";
VAL_ 1047 ClstrDspdABSWrnng 0 "ClstrDspdABSWrnng_No_Warning" 1 "ClstrDspdABSWrnng_Warning";
VAL_ 1047 ClstrDspdACCSysWrnng 0 "ClstrDspdACCSysWrnng_No_Warning" 1 "ClstrDspdACCSysWrnng_Warning";
VAL_ 1047 ClstrDspdAdvFrtLghtngSysWrnng 0 "ClstrDspdAdvFrtLghtngSysWrnng_No_Warning" 1 "ClstrDspdAdvFrtLghtngSysWrnng_Warning";
VAL_ 1047 ClstrDspdAEBSysWrnng 0 "ClstrDspdAEBSysWrnng_No_Warning" 1 "ClstrDspdAEBSysWrnng_Warning";
VAL_ 1047 ClstrDspdAirbagWrnng 0 "ClstrDspdAirbagWrnng_No_Warning" 1 "ClstrDspdAirbagWrnng_Warning";
VAL_ 1047 ClstrDspdAltrWrnng 0 "ClstrDspdAltrWrnng_No_Warning" 1 "ClstrDspdAltrWrnng_Warning";
VAL_ 1047 ClstrDspdAutoholdWrnng 0 "ClstrDspdAutoholdWrnng_No_Warning" 1 "ClstrDspdAutoholdWrnng_Warning";
VAL_ 1047 ClstrDspdBatRplmntRqdWrnng 0 "ClstrDspdBatRplmntRqdWrnng_No_Warning" 1 "ClstrDspdBatRplmntRqdWrnng_Warning";
VAL_ 1047 ClstrDspdBrkSysWrnng 0 "ClstrDspdBrkSysWrnng_No_Warning" 1 "ClstrDspdBrkSysWrnng_Warning";
VAL_ 1047 ClstrDspdCCWrnng 0 "ClstrDspdCCWrnng_No_Warning" 1 "ClstrDspdCCWrnng_Warning";
VAL_ 1047 ClstrDspdClntTemWrnng 0 "ClstrDspdClntTemWrnng_No_Warning" 1 "ClstrDspdClntTemWrnng_Warning";
VAL_ 1047 ClstrDspdClSwWrnng 0 "ClstrDspdClSwWrnng_No_Warning" 1 "ClstrDspdClSwWrnng_Warning";
VAL_ 1047 ClstrDspdDayTimeRunningLampWrnng 0 "ClstrDspdDayTimeRunningLampWrnng_No_Warning" 1 "ClstrDspdDayTimeRunningLampWrnng_Warning";
VAL_ 1047 ClstrDspdEleccParkngBrkWrnng 0 "ClstrDspdEleccParkngBrkWrnng_No_Warning" 1 "ClstrDspdEleccParkngBrkWrnng_Warning";
VAL_ 1047 ClstrDspdEnDrvByWrWrnng 0 "ClstrDspdEnDrvByWrWrnng_No_Warning" 1 "ClstrDspdEnDrvByWrWrnng_Warning";
VAL_ 1047 ClstrDspdEPSWrnng 0 "ClstrDspdEPSWrnng_No_Warning" 1 "ClstrDspdEPSWrnng_General_Warning" 2 "ClstrDspdEPSWrnng_Serious_Warning" 3 "ClstrDspdEPSWrnng_Reserved";
VAL_ 1047 ClstrDspdFuelSnsrWrnng 0 "ClstrDspdFuelSnsrWrnng_No_Warning" 1 "ClstrDspdFuelSnsrWrnng_Warning";
VAL_ 1047 ClstrDspdFVCMSnsrWrnng 0 "ClstrDspdFVCMSnsrWrnng_No_Warning" 1 "ClstrDspdFVCMSnsrWrnng_Warning";
VAL_ 1047 ClstrDspdHDCWrnng 0 "ClstrDspdHDCWrnng_No_Warning" 1 "ClstrDspdHDCWrnng_Warning";
VAL_ 1047 ClstrDspdHillHoldWrnng 0 "ClstrDspdHillHoldWrnng_No_Warning" 1 "ClstrDspdHillHoldWrnng_Warning";
VAL_ 1047 ClstrDspdIgnRelayWrnng 0 "ClstrDspdIgnRelayWrnng_No_Warning" 1 "ClstrDspdIgnRelayWrnng_Warning";
VAL_ 1047 ClstrDspdInvdKeyWrnng 0 "ClstrDspdInvdKeyWrnng_No_Warning" 1 "ClstrDspdInvdKeyWrnng_Warning";
VAL_ 1047 ClstrDspdLBrkLghtWrnng 0 "ClstrDspdLBrkLghtWrnng_No_Warning" 1 "ClstrDspdLBrkLghtWrnng_Warning";
VAL_ 1047 ClstrDspdLDipdBeamLghtWrnng 0 "ClstrDspdLDipdBeamLghtWrnng_No_Warning" 1 "ClstrDspdLDipdBeamLghtWrnng_Warning";
VAL_ 1047 ClstrDspdLDircnIndLghtWrnng 0 "ClstrDspdLDircnIndLghtWrnng_No_Warning" 1 "ClstrDspdLDircnIndLghtWrnng_Warning";
VAL_ 1047 ClstrDspdLDWSysFlt 0 "ClstrDspdLDWSysFlt_No_Warning" 1 "ClstrDspdLDWSysFlt_Warning";
VAL_ 1047 ClstrDspdLSideLghtWrnng 0 "ClstrDspdLSideLghtWrnng_No_Warning" 1 "ClstrDspdLSideLghtWrnng_Warning";
VAL_ 1047 ClstrDspdPEWrnng 0 "ClstrDspdPEWrnng_No_Warning" 1 "ClstrDspdPEWrnng_Warning";
VAL_ 1047 ClstrDspdRBrkLghtWrnng 0 "ClstrDspdRBrkLghtWrnng_No_Warning" 1 "ClstrDspdRBrkLghtWrnng_Warning";
VAL_ 1047 ClstrDspdRDipdBeamLghtWrnng 0 "ClstrDspdRDipdBeamLghtWrnng_No_Warning" 1 "ClstrDspdRDipdBeamLghtWrnng_Warning";
VAL_ 1047 ClstrDspdRDircnIndLghtWrnng 0 "ClstrDspdRDircnIndLghtWrnng_No_Warning" 1 "ClstrDspdRDircnIndLghtWrnng_Warning";
VAL_ 1047 ClstrDspdRevsLampWrnng 0 "ClstrDspdRevsLampWrnng_No_Warning" 1 "ClstrDspdRevsLampWrnng_Warning";
VAL_ 1047 ClstrDspdRrFogLghtWrnng 0 "ClstrDspdRrFogLghtWrnng_No_Warning" 1 "ClstrDspdRrFogLghtWrnng_Warning";
VAL_ 1047 ClstrDspdRSideLghtWrnng 0 "ClstrDspdRSideLghtWrnng_No_Warning" 1 "ClstrDspdRSideLghtWrnng_Warning";
VAL_ 1047 ClstrDspdSASUncalWrnng 0 "ClstrDspdSASUncalWrnng_No_Warning" 1 "ClstrDspdSASUncalWrnng_Warning";
VAL_ 1047 ClstrDspdSASWrnng 0 "ClstrDspdSASWrnng_No_Warning" 1 "ClstrDspdSASWrnng_Warning";
VAL_ 1047 ClstrDspdSCSWrnng 0 "ClstrDspdSCSWrnng_No_Warning" 1 "ClstrDspdSCSWrnng_Warning";
VAL_ 1047 ClstrDspdScurtKeyBatLowWrnng 0 "ClstrDspdScurtKeyBatLowWrnng_No_Warning" 1 "ClstrDspdScurtKeyBatLowWrnng_Warning";
VAL_ 1047 ClstrDspdSpdAstSysWrnng 0 "ClstrDspdSpdAstSysWrnng_No_Warning" 1 "ClstrDspdSpdAstSysWrnng_Warning";
VAL_ 1047 ClstrDspdSpStBtnWrnng 0 "ClstrDspdSpStBtnWrnng_No_Warning" 1 "ClstrDspdSpStBtnWrnng_Warning";
VAL_ 1047 ClstrDspdSpStWrnng 0 "ClstrDspdSpStWrnng_No_Warning" 1 "ClstrDspdSpStWrnng_Warning";
VAL_ 1047 ClstrDspdTCCMWrnng 0 "ClstrDspdTCCMWrnng_No_Warning" 1 "ClstrDspdTCCMWrnng_Warning";
VAL_ 1047 ClstrDspdTCSWrnng 0 "ClstrDspdTCSWrnng_No_Warning" 1 "ClstrDspdTCSWrnng_Warning";
VAL_ 1047 ClstrDspdTrWrnng 0 "ClstrDspdTrWrnng_No_Warning" 1 "ClstrDspdTrWrnng_Warning";
VAL_ 1047 ClstrDspdTyrePrsSts 0 "ClstrDspdTyrePrsSts_No_Warning" 1 "ClstrDspdTyrePrsSts_Low_Tyre" 2 "ClstrDspdTyrePrsSts_System_Failure" 3 "ClstrDspdTyrePrsSts_Reserved";
VAL_ 1047 ClstrDspdWshrFludLowWrnng 0 "ClstrDspdWshrFludLowWrnng_No_Warning" 1 "ClstrDspdWshrFludLowWrnng_Warning";
VAL_ 1144 FuelLvlPcntRawV 0 "FuelLvlPcntRawV_Valid" 1 "FuelLvlPcntRawV_Invalid";
VAL_ 1144 FuelLvlSnsrFlrSts 0 "FuelLvlSnsrFlrSts_Valid" 1 "FuelLvlSnsrFlrSts_Out_Of_Minimum_Range" 2 "FuelLvlSnsrFlrSts_Out_Of_Maximum_Range" 3 "FuelLvlSnsrFlrSts_Reserved";
VAL_ 1144 FuelLvlSnsrFlrStsInvsn 0 "FuelLvlSnsrFlrStsInvsn_Reserved" 1 "FuelLvlSnsrFlrStsInvsn_Out_Of_Maximum_Range" 2 "FuelLvlSnsrFlrStsInvsn_Out_Of_Minimum_Range" 3 "FuelLvlSnsrFlrStsInvsn_Valid";
VAL_ 1144 IPKOdoReq 0 "False" 1 "True";
VAL_ 1031 ClstrDspdClOvhtdWrnng 0 "ClstrDspdClOvhtdWrnng_No_Warning" 1 "ClstrDspdClOvhtdWrnng_Warning";
VAL_ 1031 ClstrDspdFuelLvlSgmt 0 "ClstrDspdFuelLvlSgmt_1st_Segment_Flash" 1 "ClstrDspdFuelLvlSgmt_1st_Segment_On" 2 "ClstrDspdFuelLvlSgmt_2nd_Segment_On" 3 "ClstrDspdFuelLvlSgmt_3th_Segment_On" 4 "ClstrDspdFuelLvlSgmt_4th_Segment_On" 5 "ClstrDspdFuelLvlSgmt_5th_Segment_On" 6 "ClstrDspdFuelLvlSgmt_6th_Segment_On" 7 "ClstrDspdFuelLvlSgmt_7th_Segment_On" 8 "ClstrDspdFuelLvlSgmt_8th_Segment_On";
VAL_ 1031 ClstrDspdFuelSts 0 "ClstrDspdFuelSts_Fuel_Status_OK" 1 "ClstrDspdFuelSts_Fuel_Status_Low" 2 "ClstrDspdFuelSts_Fuel_Status_Critical" 3 "ClstrDspdFuelSts_Reserved";
VAL_ 1031 ClstrDspdInfoMsk 0 "ClstrDspdInfoMsk_Don_t_Use_Data" 1 "ClstrDspdInfoMsk_Use_Data";
VAL_ 1031 ClstrDspdMalfIndrLghtWrnng 0 "ClstrDspdMalfIndrLghtWrnng_No_Warning" 1 "ClstrDspdMalfIndrLghtWrnng_Warning";
VAL_ 1031 ClstrDspdOilPrsLowWrnng 0 "ClstrDspdOilPrsLowWrnng_No_Warning" 1 "ClstrDspdOilPrsLowWrnng_Warning";
VAL_ 1031 ClstrDspdPDCWrnng 0 "ClstrDspdPDCWrnng_No_Warning" 1 "ClstrDspdPDCWrnng_Front_PDC_Fault" 2 "ClstrDspdPDCWrnng_Rear_PDC_Fault" 3 "ClstrDspdPDCWrnng_System_Fault";
VAL_ 1031 ClstrDspdPwrLftgtSysWrnng 0 "ClstrDspdPwrLftgtSysWrnng_No_Warning" 1 "ClstrDspdPwrLftgtSysWrnng_Warning";
VAL_ 1360 AvgFuelCsumpV 0 "AvgFuelCsumpV_0_Valid" 1 "AvgFuelCsumpV_1_nvalid";
VAL_ 537 ADASDspdErInHMI 0 "ADASDspdErInHMI_0_NoError" 1 "ADASDspdErInHMI_1_Error" 2 "ADASDspdErInHMI_2_Reserved" 3 "ADASDspdErInHMI_3_Reserved";
VAL_ 537 ADASErDetcByHMI 0 "ADASErDetcByHMI_0_NoFailure" 1 "ADASErDetcByHMI_1_Failure" 2 "ADASErDetcByHMI_2_Reserved" 3 "ADASErDetcByHMI_3_Reserved";
VAL_ 672 RrACAutoDspCmd 0 "False" 1 "True";
VAL_ 672 RrACOnOffDspCmd 0 "RrACOnOffDspCmd_off" 1 "RrACOnOffDspCmd_on";
VAL_ 892 ACFrtAirMdSwA 0 "False" 1 "True";
VAL_ 892 ACSyncDspCmd 0 "False" 1 "True";
VAL_ 892 HtdRrWndSwA 0 "False" 1 "True";
VAL_ 892 InsdAirPrtclMtrCncntrnDspCmd 251 "InsdAirPrtclMtrCDC_reminder_off" 252 "InsdAirPrtclMtrCDC_reminder_on" 253 "InsdAirPrtclMtrCDC_Invalid" 254 "InsdAirPrtclMtrCDC_no_sensor" 255 "InsdAirPrtclMtrCDC_error";
VAL_ 892 InsdAirPrtclMtrCncntrnSwSts 0 "InsdAirPrtclMtrCncntrnSwSts_off" 1 "InsdAirPrtclMtrCncntrnSwSts_on";
VAL_ 893 ACFltrCsumLvlDspCmd 0 "ACFltrCsumLvlDspCmd_Consume_0" 1 "ACFltrCsumLvlDspCmd_Consume_1_3" 2 "ACFltrCsumLvlDspCmd_Consume_2_3" 3 "ACFltrCsumLvlDspCmd_Use_Up";
VAL_ 893 ACUserCustAftRunOnOffDspCmd 0 "ACUserCustAftRunOnOffDspCmd_0_Off" 1 "ACUserCustAftRunOnOffDspCmdV_1_On" 2 "ACUserCustAftRunOnOffDspCmd_2_Reserved" 3 "ACUserCustAftRunOnOffDspCmd_3_Function_disable";
VAL_ 893 ACUserCustAirQultEnbDspCmd 0 "ACUserCustAirQultEnbDspCmd_Low_sensitivity" 1 "ACUserCustAirQultEnbDspCmd_High_sensitivity" 2 "ACUserCustAirQultEnbDspCmd_2_Close" 3 "ACUserCustAirQultEnbDspCmd_Function_disable";
VAL_ 893 ACUserCustAutoMdBlwrDspCmd 0 "High_level" 1 "Middle_level" 2 "Low_level" 3 "Function_disable";
VAL_ 893 ACUserCustAutoMdTemDspCmd 0 "Cool" 1 "Standard" 2 "Hot" 3 "Function_disable";
VAL_ 893 ACUserCustBlwrAutoRunRmtUnlckDspCmd 0 "Off" 1 "On" 2 "Reserved" 3 "Function_disable";
VAL_ 893 ACUserCustCofignDspCmd 0 "ACUserCustCofignDspCmd_No_User_Configuration" 1 "ACUserCustCofignDspCmd_Configuration_1" 2 "ACUserCustCofignDspCmd_Configuration_2" 3 "ACUserCustCofignDspCmd_Configuration_3" 4 "ACUserCustCofignDspCmd_Function_disable" 5 "ACUserCustCofignDspCmd_5_Reserved" 6 "ACUserCustCofignDspCmd_6_Reserved" 7 "ACUserCustCofignDspCmd_7_Reserved";
VAL_ 893 ACUserCustEcoSetngDspCmd 0 "ACUserCustEcoSetngDspCmd_0_Reserved" 1 "ACUserCustEcoSetngDspCmd_1_Economy_Mode" 2 "ACUserCustEcoSetngDspCmd_2_Normal_Mode" 3 "ACUserCustEcoSetngDspCmd_3_Function_Disable";
VAL_ 893 ACUserCustFltrLifeRmndDspCmd 0 "Off" 1 "On" 2 "Reserved" 3 "Function_disable";
VAL_ 893 ACUserCustFrtAutoDmstngDspCmd 0 "Off" 1 "On" 2 "Reserved" 3 "unction_disable";
VAL_ 893 ACUserCustRmtStOnOffDspCmd 0 "Off" 1 "On" 2 "Reserved" 3 "Function_disable";
VAL_ 893 ACUserCustRrAutoDmstngDspCmd 0 "On" 1 "Off" 2 "Same_with_front_aotu_demisting" 3 "Function_disable";
VAL_ 893 ACUserCustRrZoneCofignDspCmd 0 "Rear_Zone_off" 1 "Same_to_front_zone" 2 "Last_Configuration" 3 "Function_disable";
VAL_ 893 ACUserCustSetngDspCmd 0 "ACUserCustSetngDspCmd__Function_Disable" 1 "ACUserCustSetngDspCmd_Unavailable" 2 "ACUserCustSetngDspCmd_Economy_Mode" 3 "ACUserCustSetngDspCmd_Normal_Mode";
VAL_ 893 ACUserCustStSpMdDspCmd 0 "ACUserCustStSpMdDspCmd_Comfort_mode" 1 "ACUserCustStSpMdDspCmd_Economy_mode" 2 "ACUserCustStSpMdDspCmd_2_Reserved" 3 "ACUserCustStSpMdDspCmd_Function_disable";
VAL_ 893 ACUserCustTemUnitDspCmd 0 "Fahrenheit" 1 "Celsius" 2 "Reserved" 3 "Function_disable";
VAL_ 893 ACUserCustZoneCofignDspCmd 0 "Unification" 1 "Separation" 2 "Last_Configuration" 3 "Function_disable";
VAL_ 893 AirClnrAutoDspCmd 0 "False" 1 "True";
VAL_ 893 AirClnrBlwrLvlDspCmd 0 "AirClnrBlwrLvlDspCmd_Blower_off" 1 "AirClnrBlwrLvlDspCmd_1_level" 2 "AirClnrBlwrLvlDspCmd_2_level" 3 "AirClnrBlwrLvlDspCmd_3_level" 4 "AirClnrBlwrLvlDspCmd_4_level" 5 "AirClnrBlwrLvlDspCmd_5_level" 6 "AirClnrBlwrLvlDspCmd_6_level" 7 "AirClnrBlwrLvlDspCmd_Auto_blower_level";
VAL_ 893 AirClnrBlwrSpdSwA 0 "False" 1 "True";
VAL_ 893 AirClnrIonizerDspCmd 0 "False" 1 "True";
VAL_ 893 AirClnrOnOffDspCmd 0 "AirClnrOnOffDspCmd_0_Off" 1 "AirClnrOnOffDspCmd_1_On";
VAL_ 893 AirClnrUserCustAutoRDC 0 "AirClnrUserCustAutoRDC_0_off" 1 "AirClnrUserCustAutoRDC_1_on" 2 "AirClnrUserCustAutoRDC_2_Reserved" 3 "AirClnrUserCustAutoRDC_Function_disable";
VAL_ 894 ACDrvrAirMdDspCmd 0 "ACDrvrAirMdDspCmd_0_face" 1 "ACDrvrAirMdDspCmd_1_face_foot" 2 "ACDrvrAirMdDspCmd_2_foot" 3 "ACDrvrAirMdDspCmd_3_foot_defrost" 4 "ACDrvrAirMdDspCmd_4_defrost" 5 "ACDrvrAirMdDspCmd_5_face_foot_defrost" 6 "ACDrvrAirMdDspCmd_6_face_defrost" 7 "ACDrvrAirMdDspCmd_7_auto_air_distribute_mode";
VAL_ 894 ACDrvrTemDspCmd 0 "ACDrvrTemDspCmd_0_Lo" 30 "ACDrvrTemDspCmd_30_Hi" 31 "ACDrvrTemDspCmd_31_reserved";
VAL_ 894 ACDrvrTemSwA 0 "False" 1 "True";
VAL_ 894 ACFrtRrSyncDspCmd 0 "False" 1 "True";
VAL_ 894 ACPsngAirMdDspCmd 0 "ACPsngAirMdDspCmd_0_face" 1 "ACPsngAirMdDspCmd_1_face_foot" 2 "ACPsngAirMdDspCmd_2_foot" 3 "ACPsngAirMdDspCmd_3_foot_defrost" 4 "ACPsngAirMdDspCmd_4_defrost" 5 "ACPsngAirMdDspCmd_5_face_foot_defrost" 6 "ACPsngAirMdDspCmd_6_face_defrost" 7 "ACPsngAirMdDspCmd_7_auto_air_distribute_mode";
VAL_ 894 ACPsngTemDspCmd 0 "ACPsngTemDspCmd_Lo" 30 "ACPsngTemDspCmd_Hi" 31 "ACPsngTemDspCmd_reserved";
VAL_ 894 ACPsngTemSwA 0 "False" 1 "True";
VAL_ 936 ACAutoDspCmd 0 "False" 1 "True";
VAL_ 936 ACAutoSwA 0 "False" 1 "True";
VAL_ 936 ACDualDspCmd 0 "False" 1 "True";
VAL_ 936 ACEcoDspCmd 0 "False" 1 "True";
VAL_ 936 ACFrtBlwrSpdDspCmd 0 "ACFrtBlwrSpdDspCmd_Blower_off" 1 "ACFrtBlwrSpdDspCmd_blower_level_1" 2 "ACFrtBlwrSpdDspCmd_blower_level_2" 3 "ACFrtBlwrSpdDspCmd_blower_level_3" 4 "ACFrtBlwrSpdDspCmd_blower_level_4" 5 "ACFrtBlwrSpdDspCmd_blower_level_5" 6 "ACFrtBlwrSpdDspCmd_blower_level_6" 7 "ACFrtBlwrSpdDspCmd_blower_level_7" 8 "ACFrtBlwrSpdDspCmd_blower_level_8" 9 "ACFrtBlwrSpdDspCmd_blower_level_9" 10 "ACFrtBlwrSpdDspCmd_blower_level_10" 11 "ACFrtBlwrSpdDspCmd_blower_level_11" 12 "ACFrtBlwrSpdDspCmd_blower_level_12" 13 "ACFrtBlwrSpdDspCmd_blower_level_13" 14 "ACFrtBlwrSpdDspCmd_blower_level_14" 15 "ACFrtBlwrSpdDspCmd_auto_blower_level";
VAL_ 936 ACFrtBlwrSpdSwA 0 "False" 1 "True";
VAL_ 936 ACFrtPnlLckRrPnlDspCmd 0 "False" 1 "True";
VAL_ 936 ACIonizerDspCmd 0 "False" 1 "True";
VAL_ 936 ACLAirMdDspCmd 0 "ACDrvrAirMdDspCmd_0_face" 1 "ACDrvrAirMdDspCmd_face_foot" 2 "ACDrvrAirMdDspCmd_2_foot" 3 "ACDrvrAirMdDspCmd_foot_defrost" 4 "ACDrvrAirMdDspCmd_4_defrost" 5 "ACDrvrAirMdDspCmd_face_foot_defrost" 6 "ACDrvrAirMdDspCmd_face_defrost" 7 "ACDrvrAirMdDspCmd_auto_air_distribute_mode";
VAL_ 936 ACLTemDspCmd 0 "ACDrvrTemDspCmd_Lo" 30 "ACDrvrTemDspCmd_Hi" 31 "ACDrvrTemDspCmd_reserved";
VAL_ 936 ACLTemSwA 0 "False" 1 "True";
VAL_ 936 ACOnOffDspCmd 0 "ACOnOffDspCmd_0_off" 1 "ACOnOffDspCmd_1_on";
VAL_ 936 ACRAirMdDspCmd 0 "ACPsngAirMdDspCmd_0_face" 1 "ACPsngAirMdDspCmd_1_face_foot" 2 "ACPsngAirMdDspCmd_2_foot" 3 "ACPsngAirMdDspCmd_3_foot_defrost" 4 "ACPsngAirMdDspCmd_4_defrost" 5 "ACPsngAirMdDspCmd_5_face_foot_defrost" 6 "ACPsngAirMdDspCmd_6_face_defrost" 7 "ACPsngAirMdDspCmd_7_auto_air_distribute_mode";
VAL_ 936 ACRcctnDspMd 0 "ACRcctnDspMd_0_Recirculation" 1 "ACRcctnDspMd_1_Fresh" 2 "ACRcctnDspMd_Auto_recirculation" 3 "ACRcctnDspMd_3_Reserved";
VAL_ 936 ACRrAirMdDspCmd 0 "ACRrAirMdDspCmd_0_face" 1 "ACRrAirMdDspCmd_face_foot" 2 "ACRrAirMdDspCmd_2_foot" 3 "ACRrAirMdDspCmd_foot_defrost" 4 "ACRrAirMdDspCmd_4_defrost" 5 "ACRrAirMdDspCmd_face_foot_defrost" 6 "ACRrAirMdDspCmd_face_defrost" 7 "ACRrAirMdDspCmd_auto_air_distribute_mode";
VAL_ 936 ACRrAutoSwA 0 "False" 1 "True";
VAL_ 936 ACRrBlwrDspCmd 0 "ACRrBlwrDspCmd_Blower_off" 1 "ACRrBlwrDspCmd_blower_level_1" 2 "ACRrBlwrDspCmd_blower_level_2" 3 "ACRrBlwrDspCmd_blower_level_3" 4 "ACRrBlwrDspCmd_blower_level_4" 5 "ACRrBlwrDspCmd_blower_level_5" 6 "ACRrBlwrDspCmd_blower_level_6" 7 "ACRrBlwrDspCmd_blower_level_7" 8 "ACRrBlwrDspCmd_blower_level_8" 9 "ACRrBlwrDspCmd_blower_level_9" 10 "ACRrBlwrDspCmd_blower_level_10" 11 "ACRrBlwrDspCmd_blower_level_11" 12 "ACRrBlwrDspCmd_blower_level_12" 13 "ACRrBlwrDspCmd_blower_level_13" 14 "ACRrBlwrDspCmd_blower_level_14" 15 "ACRrBlwrDspCmd_auto_blower_level";
VAL_ 936 ACRrBlwrLvlDspCmd 0 "ACRrBlwrLvlDspCmd_Blower_off" 1 "ACRrBlwrLvlDspCmd_Blower_level_1" 2 "ACRrBlwrLvlDspCmd_Blower_level_2" 3 "ACRrBlwrLvlDspCmd_Blower_level_3" 4 "ACRrBlwrLvlDspCmd_Blower_level_4" 5 "ACRrBlwrLvlDspCmd_Blower_level_5" 6 "ACRrBlwrLvlDspCmd_Blower_level_6" 7 "ACRrBlwrLvlDspCmd_Blower_level_7" 8 "ACRrBlwrLvlDspCmd_Blower_level_8" 9 "ACRrBlwrLvlDspCmd_Blower_level_9" 10 "ACRrBlwrLvlDspCmd_Blower_level_10" 11 "ACRrBlwrLvlDspCmd_Blower_level_11" 12 "ACRrBlwrLvlDspCmd_Blower_level_12" 13 "ACRrBlwrLvlDspCmd_Blower_level_13" 14 "ACRrBlwrLvlDspCmd_Blower_level_14" 15 "ACRrBlwrLvlDspCmd_Blower_level_15";
VAL_ 936 ACRrBlwrSpdSwA 0 "False" 1 "True";
VAL_ 936 ACRrTemDspCmd 0 "ACRrTemDspCmd_Lo" 30 "ACRrTemDspCmd_Hi" 31 "ACRrTemDspCmd_reserved";
VAL_ 936 ACRrTemSwA 0 "False" 1 "True";
VAL_ 936 ACRTemDspCmd 0 "ACPsngTemDspCmd_Lo" 30 "ACPsngTemDspCmd_Hi" 31 "ACPsngTemDspCmd_reserved";
VAL_ 936 ACRTemSwA 0 "False" 1 "True";
VAL_ 936 ClmOnOffDspCmd 0 "ClmOnOffDspCmd_0_OFF" 1 "ClmOnOffDspCmd_1_ON";
VAL_ 936 ComprOnOffDspCmd 0 "ComprOnOffDspCmd_0_off" 1 "ComprOnOffDspCmd_1_on";
VAL_ 936 DfstOnDspCmd 0 "False" 1 "True";
VAL_ 936 FLSeatHeatDspCmd 0 "FLSeatHeatDspCmd_off" 1 "FLSeatHeatDspCmd_level_1" 2 "FLSeatHeatDspCmd_level_2" 3 "FLSeatHeatDspCmd_level_3";
VAL_ 936 FLSeatVentDspCmd 0 "FLSeatVentDspCmd_off" 1 "FLSeatVentDspCmd_level_1" 2 "FLSeatVentDspCmd_level_2" 3 "FLSeatVentDspCmd_level_3";
VAL_ 936 FRSeatHeatDspCmd 0 "FRSeatHeatDspCmd_off" 1 "FRSeatHeatDspCmd_level_1" 2 "FRSeatHeatDspCmd_level_2" 3 "FRSeatHeatDspCmd_level_3";
VAL_ 936 FRSeatVentDspCmd 0 "FRSeatVentDspCmd_off" 1 "FRSeatVentDspCmd_level_1" 2 "FRSeatVentDspCmd_level_2" 3 "FRSeatVentDspCmd_level_3";
VAL_ 936 HtdRrWndOnDspCmd 0 "False" 1 "True";
VAL_ 1361 OtsdAirPrtclMtrCncntrnDspCmd 251 "OtsdAirPrtclMtrCncntrnDspCmd_reminder_off" 252 "OtsdAirPrtclMtrCncntrnDspCmd_reminder_on" 253 "OtsdAirPrtclMtrCncntrnDspCmd_Invalid" 254 "OtsdAirPrtclMtrCncntrnDspCmd_no_sensor" 255 "OtsdAirPrtclMtrCncntrnDspCmd_error";
VAL_ 1361 OtsdAirQultSts 0 "OtsdAirQultSts_Clean" 1 "OtsdAirQultSts_Pollution";
VAL_ 1361 OtsdAirQultStsV 0 "Valid" 1 "Invalid";
VAL_ 1509 ACAmbtTemMsk 0 "ACAmbtTemMsk_Don_t_Use_Data" 1 "ACAmbtTemMsk_Use_Data";
VAL_ 1509 ACAmbtTemV 0 "ACAmbtTemV_valid" 1 "ACAmbtTemV_not_valid";
VAL_ 1509 ACFltrTyp 0 "ACFltrTyp_Normal_Filter" 1 "ACFltrTyp_PM2_5_Filter" 2 "ACFltrTyp_PM2_5_and_VOC_Filter" 3 "ACFltrTyp_Multiple_Filter";
VAL_ 1509 ACInCarTem 254 "ACInCarTem_Init" 255 "ACInCarTem_Failure";
VAL_ 1509 ACInCarTemV 0 "ACInCarTemV_Valid" 1 "ACInCarTemV_Invalid";
VAL_ 1509 ACTemUnitDspCmd 0 "ACTemUnitDspCmd_0_Celsius" 1 "ACTemUnitDspCmd_1_Fahrenheit";
VAL_ 1509 AirClnrFltrCsumLvlDspCmd 0 "AirClnrFltrCsumLvlDspCmd_Consume_0" 1 "AirClnrFltrCsumLvlDspCmd_Consume_1_3" 2 "AirClnrFltrCsumLvlDspCmd_Consume_2_3" 3 "AirClnrFltrCsumLvlDspCmd_Consume_Use_up";
VAL_ 1509 AirClnrFltrLifeV 0 "Valid" 1 "Invalid";
VAL_ 993 OtsdAirPrtclMtrCDC 251 "OtsdAirPrtclMtrCDC_251_reminder_off" 252 "OtsdAirPrtclMtrCDC_252_reminder_on" 253 "OtsdAirPrtclMtrCDC_253_Invalid" 254 "OtsdAirPrtclMtrCDC_254_reserved" 255 "OtsdAirPrtclMtrCDC_255_error";
VAL_ 837 AMPWorkSta 0 "False" 1 "True";
VAL_ 43 AllMuteFdbk 0 "AllMuteFdbk_0_Unmute" 1 "AllMuteFdbk_1_Mute";
VAL_ 43 AutocVolmCmpstnFdbk 0 "AutocVolmCmpstnFdbk_0_Off" 1 "AutocVolmCmpstnFdbk_1_On";
VAL_ 43 BalcSetngFdbk 0 "BalcSetngFdbk_0_Level_negative7" 1 "BalcSetngFdbk_1_Level_negative6" 2 "BalcSetngFdbk_2_Level_negative5" 3 "BalcSetngFdbk_3_Level_negative4" 4 "BalcSetngFdbk_4_Level_negative3" 5 "BalcSetngFdbk_5_Level_negative2" 6 "BalcSetngFdbk_6_Level_negative1" 7 "BalcSetngFdbk_7_Level0" 8 "BalcSetngFdbk_8_Level1" 9 "BalcSetngFdbk_9_Level2" 10 "BalcSetngFdbk_10_Level3" 11 "BalcSetngFdbk_11_Level4" 12 "BalcSetngFdbk_12_Level5" 13 "BalcSetngFdbk_13_Level6" 14 "BalcSetngFdbk_14_Level7" 15 "BalcSetngFdbk_15_Reserved";
VAL_ 43 BassFdbk 0 "BassFdbk_0_negetive7dB" 1 "BassFdbk_1_negetive6dB" 2 "BassFdbk_2_negative5dB" 3 "BassFdbk_3_negative4dB" 4 "BassFdbk_4_negative3dB" 5 "BassFdbk_5_negative2dB" 6 "BassFdbk_6_negative1dB" 7 "BassFdbk_7_0dB" 8 "BassFdbk_8_1dB" 9 "BassFdbk_9_2dB" 10 "BassFdbk_10_3dB" 11 "BassFdbk_11_4dB" 12 "BassFdbk_12_5dB" 13 "BassFdbk_13_6dB" 14 "BassFdbk_14_7dB" 15 "BassFdbk_15_Reserved";
VAL_ 43 ChmSndVolmStepFdbk 0 "ChmSndVolmStepFdbk_0_Reserved" 1 "ChmSndVolmStepFdbk_1_Step_2" 2 "ChmSndVolmStepFdbk_2_Step_3" 3 "ChmSndVolmStepFdbk_3_Step_4" 4 "ChmSndVolmStepFdbk_4_Step5" 5 "ChmSndVolmStepFdbk_5_Step_6" 6 "ChmSndVolmStepFdbk_6_Step_7" 7 "ChmSndVolmStepFdbk_7_Step_8" 8 "ChmSndVolmStepFdbk_8_Step_9" 9 "ChmSndVolmStepFdbk_9_Step_10" 10 "ChmSndVolmStepFdbk_10_Step_11" 11 "ChmSndVolmStepFdbk_11_Step_12" 12 "ChmSndVolmStepFdbk_12_Step_13" 13 "ChmSndVolmStepFdbk_13_Step_14" 14 "ChmSndVolmStepFdbk_14_Step_15" 15 "ChmSndVolmStepFdbk_15_Step_16";
VAL_ 43 FdrSetngFdbk 0 "FdrSetngFdbk_0_Level_negative7" 1 "FdrSetngFdbk_1_Level_negative6" 2 "FdrSetngFdbk_2_Level_negative5" 3 "FdrSetngFdbk_3_Level_negative4" 4 "FdrSetngFdbk_4_Level_negative3" 5 "FdrSetngFdbk_5_Level_negative2" 6 "FdrSetngFdbk_6_Level_negative1" 7 "FdrSetngFdbk_7_Level0" 8 "FdrSetngFdbk_8_Level1" 9 "FdrSetngFdbk_9_Level2" 10 "FdrSetngFdbk_10_Level3" 11 "FdrSetngFdbk_11_Level4" 12 "FdrSetngFdbk_12_Level5" 13 "FdrSetngFdbk_13_Level6" 14 "FdrSetngFdbk_14_Level7" 15 "FdrSetngFdbk_15_Reserved";
VAL_ 43 MdaMuteFdbk 0 "MdaMuteFdbk_0_Unmute" 1 "MdaMuteFdbk_1_Mute";
VAL_ 43 MdaSndVolmStepFdbk 0 "MdaSndVolmStepFdbk_0_Step0" 1 "MdaSndVolmStepFdbk_1_Step1" 2 "MdaSndVolmStepFdbk_2_Step2" 3 "MdaSndVolmStepFdbk_3_Step3" 4 "MdaSndVolmStepFdbk_4_Step4" 5 "MdaSndVolmStepFdbk_5_Step5" 6 "MdaSndVolmStepFdbk_6_Step6" 7 "MdaSndVolmStepFdbk_7_Step7" 8 "MdaSndVolmStepFdbk_8_Step8" 9 "MdaSndVolmStepFdbk_9_Step9" 10 "MdaSndVolmStepFdbk_10_Step10" 11 "MdaSndVolmStepFdbk_11_Step11" 12 "MdaSndVolmStepFdbk_12_Step12" 13 "MdaSndVolmStepFdbk_13_Step13" 14 "MdaSndVolmStepFdbk_14_Step14" 15 "MdaSndVolmStepFdbk_15_Step15" 16 "MdaSndVolmStepFdbk_16_Step16" 17 "MdaSndVolmStepFdbk_17_Step17" 18 "MdaSndVolmStepFdbk_18_Step18" 19 "MdaSndVolmStepFdbk_19_Step19" 20 "MdaSndVolmStepFdbk_20_Step20" 21 "MdaSndVolmStepFdbk_21_Step21" 22 "MdaSndVolmStepFdbk_22_Step22" 23 "MdaSndVolmStepFdbk_23_Step23" 24 "MdaSndVolmStepFdbk_24_Step24" 25 "MdaSndVolmStepFdbk_25_Step25" 26 "MdaSndVolmStepFdbk_26_Step26" 27 "MdaSndVolmStepFdbk_27_Step27" 28 "MdaSndVolmStepFdbk_28_Step28" 29 "MdaSndVolmStepFdbk_29_Step29" 30 "MdaSndVolmStepFdbk_30_Step30" 31 "MdaSndVolmStepFdbk_31_Step31" 32 "MdaSndVolmStepFdbk_32_Step32";
VAL_ 43 MedFdbk 0 "MedFdbk_0_negative7dB" 1 "MedFdbk_1_negative6dB" 2 "MedFdbk_2_negative5dB" 3 "MedFdbk_3_negative4dB" 4 "MedFdbk_4_negative3dB" 5 "MedFdbk_5_negative2dB" 6 "MedFdbk_6_negative1dB" 7 "MedFdbk_7_0dB" 8 "MedFdbk_8_1dB" 9 "MedFdbk_9_2dB" 10 "MedFdbk_10_3dB" 11 "MedFdbk_11_4dB" 12 "MedFdbk_12_5dB" 13 "MedFdbk_13_6dB" 14 "MedFdbk_14_7dB" 15 "MedFdbk_15_Reserved";
VAL_ 43 NavSndVolmStepFdbk 0 "NavSndVolmStepFdbk_0_Step0" 1 "NavSndVolmStepFdbk_1_Step1" 2 "NavSndVolmStepFdbk_2_Step2" 3 "NavSndVolmStepFdbk_3_Step3" 4 "NavSndVolmStepFdbk_4_Step4" 5 "NavSndVolmStepFdbk_5_Step5" 6 "NavSndVolmStepFdbk_6_Step6" 7 "NavSndVolmStepFdbk_7_Step7" 8 "NavSndVolmStepFdbk_8_Step8" 9 "NavSndVolmStepFdbk_9_Step9" 10 "NavSndVolmStepFdbk_10_Step10" 11 "NavSndVolmStepFdbk_11_Step11" 12 "NavSndVolmStepFdbk_12_Step12" 13 "NavSndVolmStepFdbk_13_Step13" 14 "NavSndVolmStepFdbk_14_Step14" 15 "NavSndVolmStepFdbk_15_Step15" 16 "NavSndVolmStepFdbk_16_Step16";
VAL_ 43 PhnCallSndVolmStepFdbk 0 "PhnCallSndVolmStepFdbk_0_Step0" 1 "PhnCallSndVolmStepFdbk_1_Step1" 2 "PhnCallSndVolmStepFdbk_2_Step2" 3 "PhnCallSndVolmStepFdbk_3_Step3" 4 "PhnCallSndVolmStepFdbk_4_Step4" 5 "PhnCallSndVolmStepFdbk_5_Step5" 6 "PhnCallSndVolmStepFdbk_6_Step6" 7 "PhnCallSndVolmStepFdbk_7_Step7" 8 "PhnCallSndVolmStepFdbk_8_Step8" 9 "PhnCallSndVolmStepFdbk_9_Step9" 10 "PhnCallSndVolmStepFdbk_10_Step10" 11 "PhnCallSndVolmStepFdbk_11_Step11" 12 "PhnCallSndVolmStepFdbk_12_Step12" 13 "PhnCallSndVolmStepFdbk_13_Step13" 14 "PhnCallSndVolmStepFdbk_14_Step14" 15 "PhnCallSndVolmStepFdbk_15_Step15" 16 "PhnCallSndVolmStepFdbk_16_Step16" 17 "PhnCallSndVolmStepFdbk_17_Step17" 18 "PhnCallSndVolmStepFdbk_18_Step18" 19 "PhnCallSndVolmStepFdbk_19_Step19" 20 "PhnCallSndVolmStepFdbk_20_Step20" 21 "PhnCallSndVolmStepFdbk_21_Step21" 22 "PhnCallSndVolmStepFdbk_22_Step22" 23 "PhnCallSndVolmStepFdbk_23_Step23" 24 "PhnCallSndVolmStepFdbk_24_Step24" 25 "PhnCallSndVolmStepFdbk_25_Step25" 26 "PhnCallSndVolmStepFdbk_26_Step26" 27 "PhnCallSndVolmStepFdbk_27_Step27" 28 "PhnCallSndVolmStepFdbk_28_Step28" 29 "PhnCallSndVolmStepFdbk_29_Step29" 30 "PhnCallSndVolmStepFdbk_30_Step30" 31 "PhnCallSndVolmStepFdbk_31_Step31" 32 "PhnCallSndVolmStepFdbk_32_Step32";
VAL_ 43 SpdDpntAutocVolmFdbk 0 "SpdDpntAutocVolmFdbk_0_Off" 1 "SpdDpntAutocVolmFdbk_1_Low" 2 "SpdDpntAutocVolmFdbk_2_Middle" 3 "SpdDpntAutocVolmFdbk_3_High";
VAL_ 43 ThreeDimnSndFldFdbk 0 "ThreeDimnSndFldFdbk_0_Off" 1 "ThreeDimnSndFldFdbk_1_AllPassenger" 2 "ThreeDimnSndFldFdbk_2_Driver" 3 "ThreeDimnSndFldFdbk_3_VIPRearSeat" 4 "ThreeDimnSndFldFdbk_4_Centerpoint" 5 "ThreeDimnSndFldFdbk_5_StereoSurrouding";
VAL_ 43 TrblFdbk 0 "TrblFdbk_0_negative7dB" 1 "TrblFdbk_1_negative6dB" 2 "TrblFdbk_2_negative5dB" 3 "TrblFdbk_3_negative4dB" 4 "TrblFdbk_4_negative3dB" 5 "TrblFdbk_5_negative2dB" 6 "TrblFdbk_6_negative1dB" 7 "TrblFdbk_7_0dB" 8 "TrblFdbk_8_1dB" 9 "TrblFdbk_9_2dB" 10 "TrblFdbk_10_3dB" 11 "TrblFdbk_11_4dB" 12 "TrblFdbk_12_5dB" 13 "TrblFdbk_13_6dB" 14 "TrblFdbk_14_7dB" 15 "TrblFdbk_15_Reserved";
VAL_ 43 VcItatnSndVolmStepFdbk 0 "VcItatnSndVolmStepFdbk_0_Step0" 1 "VcItatnSndVolmStepFdbk_1_Step1" 2 "VcItatnSndVolmStepFdbk_2_Step2" 3 "VcItatnSndVolmStepFdbk_3_Step3" 4 "VcItatnSndVolmStepFdbk_4_Step4" 5 "VcItatnSndVolmStepFdbk_5_Step5" 6 "VcItatnSndVolmStepFdbk_6_Step6" 7 "VcItatnSndVolmStepFdbk_7_Step7" 8 "VcItatnSndVolmStepFdbk_8_Step8" 9 "VcItatnSndVolmStepFdbk_9_Step9" 10 "VcItatnSndVolmStepFdbk_10_Step10" 11 "VcItatnSndVolmStepFdbk_11_Step11" 12 "VcItatnSndVolmStepFdbk_12_Step12" 13 "VcItatnSndVolmStepFdbk_13_Step13" 14 "VcItatnSndVolmStepFdbk_14_Step14" 15 "VcItatnSndVolmStepFdbk_15_Step15" 16 "VcItatnSndVolmStepFdbk_16_Step16";
VAL_ 1553 AMPASndWaveSelSts 0 "AMPASndWaveSelSts_0_Sound_1" 1 "AMPASndWaveSelSts_1_Sound_2" 2 "AMPASndWaveSelSts_2_Sound_3" 3 "AMPASndWaveSelSts_3_Sound_4" 4 "AMPASndWaveSelSts_4_Sound_5" 5 "AMPASndWaveSelSts_5_Sound_6" 6 "AMPASndWaveSelSts_6_Reserved" 7 "AMPASndWaveSelSts_7_Reserved";
VAL_ 1553 AMPASndWaveSts 0 "AMPASndWaveSts_0_On" 1 "AMPASndWaveSts_1_Off" 2 "AMPASndWaveSts_2_Unavailable" 3 "AMPASndWaveSts_3_Function_unavailable";
VAL_ 1553 AMPASndWaveVolmSwSts 0 "AMPASndWvVolmSwSts_0_0_Level" 1 "AMPASndWvVolmSwSts_1_1_Level" 2 "AMPASndWvVolmSwSts_2_2_Level" 3 "AMPASndWvVolmSwSts_3_3_Level" 4 "AMPASndWvVolmSwSts_4_4_Level_" 5 "AMPASndWvVolmSwSts_5_5_Level" 6 "AMPASndWvVolmSwSts_6_6_Level" 7 "AMPASndWvVolmSwSts_7_7_Level" 8 "AMPASndWvVolmSwSts_8_8_Level" 9 "AMPASndWvVolmSwSts_9_9_Level" 10 "AMPASndWvVolmSwSts_10_10_Level" 11 "AMPASndWvVolmSwSts_11_11_Level" 12 "AMPASndWvVolmSwSts_12_12_Level" 13 "AMPASndWvVolmSwSts_13_13_Level" 14 "AMPASndWvVolmSwSts_14_14_Level" 15 "AMPASndWvVolmSwSts_15_15_Level";
VAL_ 1553 AMPICMInfoStsSyn 0 "AMPICMInfoStsSyn_0_Disable" 1 "AMPICMInfoStsSyn_1_Enable";
VAL_ 1553 ANCOnOffFdbk 0 "False" 1 "True";
VAL_ 521 LCLWSysWrnng 0 "LCLWSysWrnng_no_warning" 1 "LCLWSysWrnng_warning_level_1" 2 "LCLWSysWrnng_warning_level_2" 3 "LCLWSysWrnng_Reserved";
VAL_ 521 RCLWSysWrnng 0 "RCLWSysWrnng_no_warning" 1 "RCLWSysWrnng_warning_level_1" 2 "RCLWSysWrnng_warning_level_2" 3 "RCLWSysWrnng_Reserved";
VAL_ 559 AVMCalSta 0 "AVMCalSta_No_Request" 1 "AVMCalSta_Running" 2 "AVMCalSta_Complete" 3 "AVMCalSta_Failed";
VAL_ 559 AVMCrntViewSta 0 "AVMCrntViewSta_No_Request" 1 "AVMCrntViewSta_front_View_2D_3D" 2 "AVMCrntViewSta_front_View_Wide_2D" 3 "AVMCrntViewSta_rear_view_2D_3D" 4 "AVMCrntViewSta_Rear_view_wide2D" 5 "AVMCrntViewSta_left_right_view_wide" 6 "AVMCrntViewSta_front_left_view3D" 7 "AVMCrntViewSta_front_right_view3D" 8 "AVMCrntViewSta_rear_left_view3D" 9 "AVMCrntViewSta_rear_right_view3D" 10 "AVMCrntViewSta_full_screen" 11 "AVMCrntViewSta_Left_View2D_3D" 12 "AVMCrntViewSta_Right_View2D_3" 13 "AVMCrntViewSta_D_reserved" 14 "AVMCrntViewSta_E_reserved" 15 "AVMCrntViewSta_F_reserved";
VAL_ 559 AVMSysSts 0 "AVMSysSts_0_Standby" 1 "AVMSysSts_1_Active" 2 "AVMSysSts_2_Fault" 3 "AVMSysSts_3_Reserved";
VAL_ 559 FrtAndRrGudOvlyDspCmd 0 "FrtAndRrGudOvlyDspCmd_No_Request" 1 "FrtAndRrGudOvlyDspCmd_No_guide_Overlay" 2 "FrtAndRrGudOvlyDspCmd_Static_Guide_Overlay" 3 "FrtAndRrGudOvlyDspCmd_Dynamic_Guide_Overlay" 4 "FrtAndRrGudOvlyDspCmd_Both" 5 "FrtAndRrGudOvlyDspCmd_5_Reserved" 6 "FrtAndRrGudOvlyDspCmd_6_Reserved" 7 "FrtAndRrGudOvlyDspCmd_7_Reserved";
VAL_ 559 LowSpdAutocOpenAVMDspCmd 0 "LowSpdAutocOpenAVMDspCmd_unavailable" 1 "LowSpdAutocOpenAVMDspCmd_Disable" 2 "LowSpdAutocOpenAVMDspCmd_Enable" 3 "LowSpdAutocOpenAVMDspCmd_Reserved";
VAL_ 559 ThreeDimnlDspCmd 0 "ThreeDimnlDspCmd_unavailable" 1 "2D" 2 "3D" 3 "ThreeDimnlDspCmd_Reserved";
VAL_ 909 AVMCalMdReqResp 0 "AVMCalMdReqResp_0_No_Request" 1 "AVMCalMdReqResp_1_Start" 2 "AVMCalMdReqResp_2_In_process" 3 "AVMCalMdReqResp_3_Success" 4 "AVMCalMdReqResp_4_Failed" 5 "AVMCalMdReqResp_5_Reserve" 6 "AVMCalMdReqResp_6_Reserve" 7 "AVMCalMdReqResp_7_Reserve";
VAL_ 909 AVMDspReq 0 "AVMDspReq_0_No_Request" 1 "AVMDspReq_1_Open" 2 "AVMDspReq_2_Close" 3 "AVMDspReq_3_Reserved";
VAL_ 909 AVMDspSwReqResp 0 "AVMDspSwReqResp_0_No_request" 1 "AVMDspSwReqResp_1_open" 2 "AVMDspSwReqResp_2_close" 3 "AVMDspSwReqResp_3_reserve";
VAL_ 909 CBDSysSelSts 0 "CBDSysSelSts_On" 1 "CBDSysSelSts_Off" 2 "CBDSysSelSts_unavialble" 3 "CBDSysSelSts_Reserved";
VAL_ 909 CBDSysSts 0 "CBDSysSts_Close" 1 "CBDSysSts_standby" 2 "CBDSysSts_Active" 3 "CBDSysSts_SystemError";
VAL_ 909 CIASetSwReqResp 0 "CIASetSwReqResp_No_request" 1 "CIASetSwReqResp_open" 2 "CIASetSwReqResp_close" 3 "CIASetSwReqResp_reserve";
VAL_ 909 CIASysSelSts 0 "CIASysSelSts_On" 1 "CIASysSelSts_Off" 2 "CIASysSelSts_unavialble" 3 "CIASysSelSts_Reserved";
VAL_ 909 CIASysSysSts 0 "CIASysSysSts_Normal" 1 "CIASysSysSts_Function_Litimed" 2 "CIASysSysSts_SystemError" 3 "CIASysSysSts_Reserved";
VAL_ 909 CLAWrnngSndSwSetngSts 0 "CLAWrnngSndSwSetngSts_On" 1 "CLAWrnngSndSwSetngSts_Off" 2 "CLAWrnngSndSwSetngSts_2_Reserved" 3 "CLAWrnngSndSwSetngSts_3_Reserved";
VAL_ 909 CLWSysSelSts 0 "CLWSysSelSts_On" 1 "CLWSysSelSts_Off" 2 "CLWSysSelSts_unavialble" 3 "CLWSysSelSts_Reserved";
VAL_ 909 CLWSysSts 0 "CLWSysSts_Close" 1 "CLWSysSts_standby" 2 "CLWSysSts_Active" 3 "CLWSysSts_SystemError";
VAL_ 909 RrViewInfoAstntSysA 0 "Active" 1 "Inactive" 2 "No_Request" 3 "Reserved";
VAL_ 909 RrViewInfoAstntSysSelSts 0 "On" 1 "Off" 2 "unavailable" 3 "Reserved";
VAL_ 909 RrViewInfoAstntSysSts 0 "Close" 1 "standby" 2 "Active" 3 "SystemError";
VAL_ 909 VehBodyColorDspCmd 0 "VehBodyColorDspCmd_Unavailable" 1 "VehBodyColorDspCmd_BLACK" 2 "VehBodyColorDspCmd_BLUE" 3 "VehBodyColorDspCmd_WHITE" 4 "VehBodyColorDspCmd_RED" 5 "VehBodyColorDspCmd_GRAY" 6 "VehBodyColorDspCmd_SILVER" 7 "VehBodyColorDspCmd_GOLD" 8 "VehBodyColorDspCmd_BLACK_WHITE" 9 "VehBodyColorDspCmd_ORANGE" 10 "VehBodyColorDspCmd_10_reserved" 11 "VehBodyColorDspCmd_11_reserved" 12 "VehBodyColorDspCmd_12_reserved" 13 "VehBodyColorDspCmd_13_reserved" 14 "VehBodyColorDspCmd_14_reserved" 15 "VehBodyColorDspCmd_15_reserved";
VAL_ 691 BCMFLObsRng 0 "BCMFLObsRng_0_No_Obstacle" 1 "BCMFLObsRng_1_Range 1" 2 "BCMFLObsRng_2_Range 2" 3 "BCMFLObsRng_3_Range 3" 4 "BCMFLObsRng_4_Range 4" 5 "BCMFLObsRng_5_Range 5" 6 "BCMFLObsRng_6_Range 6" 7 "BCMFLObsRng_7_Range 7" 8 "BCMFLObsRng_8_Range 8" 9 "BCMFLObsRng_9_Range 9" 10 "BCMFLObsRng_10_Range 10" 11 "BCMFLObsRng_11_Range 11" 12 "BCMFLObsRng_12_Range 12" 13 "BCMFLObsRng_13_Range 13" 14 "BCMFLObsRng_14_Range 14" 15 "BCMFLObsRng_15_Range 15";
VAL_ 691 BCMFRObsRng 0 "BCMFRObsRng_0_No_Obstacle" 1 "BCMFRObsRng_1_Range 1" 2 "BCMFRObsRng_2_Range 2" 3 "BCMFRObsRng_3_Range 3" 4 "BCMFRObsRng_4_Range 4" 5 "BCMFRObsRng_5_Range 5" 6 "BCMFRObsRng_6_Range 6" 7 "BCMFRObsRng_7_Range 7" 8 "BCMFRObsRng_8_Range 8" 9 "BCMFRObsRng_9_Range 9" 10 "BCMFRObsRng_10_Range 10" 11 "BCMFRObsRng_11_Range 11" 12 "BCMFRObsRng_12_Range 12" 13 "BCMFRObsRng_13_Range 13" 14 "BCMFRObsRng_14_Range 14" 15 "BCMFRObsRng_15_Range 15";
VAL_ 691 BCMFrtMidLObsRng 0 "BCMFrtMidLObsRng_0_No_Obstacle" 1 "BCMFrtMidLObsRng_1_Range 1" 2 "BCMFrtMidLObsRng_2_Range 2" 3 "BCMFrtMidLObsRng_3_Range 3" 4 "BCMFrtMidLObsRng_4_Range 4" 5 "BCMFrtMidLObsRng_5_Range 5" 6 "BCMFrtMidLObsRng_6_Range 6" 7 "BCMFrtMidLObsRng_7_Range 7" 8 "BCMFrtMidLObsRng_8_Range 8" 9 "BCMFrtMidLObsRng_9_Range 9" 10 "BCMFrtMidLObsRng_10_Range 10" 11 "BCMFrtMidLObsRng_11_Range 11" 12 "BCMFrtMidLObsRng_12_Range 12" 13 "BCMFrtMidLObsRng_13_Range 13" 14 "BCMFrtMidLObsRng_14_Range 14" 15 "BCMFrtMidLObsRng_15_Range 15";
VAL_ 691 BCMFrtMidRObsRng 0 "BCMFrtMidRObsRng_0_No_Obstacle" 1 "BCMFrtMidRObsRng_1_Range 1" 2 "BCMFrtMidRObsRng_2_Range 2" 3 "BCMFrtMidRObsRng_3_Range 3" 4 "BCMFrtMidRObsRng_4_Range 4" 5 "BCMFrtMidRObsRng_5_Range 5" 6 "BCMFrtMidRObsRng_6_Range 6" 7 "BCMFrtMidRObsRng_7_Range 7" 8 "BCMFrtMidRObsRng_8_Range 8" 9 "BCMFrtMidRObsRng_9_Range 9" 10 "BCMFrtMidRObsRng_10_Range 10" 11 "BCMFrtMidRObsRng_11_Range 11" 12 "BCMFrtMidRObsRng_12_Range 12" 13 "BCMFrtMidRObsRng_13_Range 13" 14 "BCMFrtMidRObsRng_14_Range 14" 15 "BCMFrtMidRObsRng_15_Range 15";
VAL_ 691 BCMFrtPDCAudWrnng 0 "BCMFrtPDCAudWrnng_0_No_Obstacle" 1 "BCMFrtPDCAudWrnng_1_Range 1" 2 "BCMFrtPDCAudWrnng_2_Range 2" 3 "BCMFrtPDCAudWrnng_3_Range 3" 4 "BCMFrtPDCAudWrnng_4_Range 4" 5 "BCMFrtPDCAudWrnng_5_Range 5" 6 "BCMFrtPDCAudWrnng_6_Range 6" 7 "BCMFrtPDCAudWrnng_7_Range 7" 8 "BCMFrtPDCAudWrnng_8_Range 8" 9 "BCMFrtPDCAudWrnng_9_Range 9" 10 "BCMFrtPDCAudWrnng_10_Range 10" 11 "BCMFrtPDCAudWrnng_11_Range 11" 12 "BCMFrtPDCAudWrnng_12_Range 12" 13 "BCMFrtPDCAudWrnng_13_Range 13" 14 "BCMFrtPDCAudWrnng_14_Range 14" 15 "BCMFrtPDCAudWrnng_15_Range 15";
VAL_ 691 BCMPDCCofignSts 0 "BCMPDCCofignSts_3_rear_sensors" 1 "BCMPDCCofignSts_4_rear_sensors" 2 "BCMPDCCofignSts_4_rear_sensors_and_2_front_side_sensors" 3 "BCMPDCCofignSts_4_rear_sensors_and_4_front_sensors" 4 "BCMPDCCofignSts_2_rear_sensors" 5 "BCMPDCCofignSts_5_Reserved1" 6 "BCMPDCCofignSts_6_Reserved2" 7 "BCMPDCCofignSts_7_Reserved3";
VAL_ 691 BCMPDCSysSts 0 "BCMPDCSysSts_System_OK" 1 "BCMPDCSysSts_System_initialization_sucessful" 2 "BCMPDCSysSts_System_Failed" 3 "BCMPDCSysSts_System_Disabled" 4 "BCMPDCSysSts_Front_PDC_Disabled" 5 "BCMPDCSysSts_Front_PDC_Failed" 6 "BCMPDCSysSts_Rear_PDC_Failed" 7 "BCMPDCSysSts_Rear_PDC_Disabled";
VAL_ 691 BCMRLObsRng 0 "BCMRLObsRng_No_Obstacle" 1 "BCMRLObsRng_Range_1" 2 "BCMRLObsRng_Range_2" 3 "BCMRLObsRng_Range_3" 4 "BCMRLObsRng_Range_4" 5 "BCMRLObsRng_Range_5" 6 "BCMRLObsRng_Range_6" 7 "BCMRLObsRng_Range_7" 8 "BCMRLObsRng_Range_8" 9 "BCMRLObsRng_Range_9" 10 "BCMRLObsRng_Range_10" 11 "BCMRLObsRng_Range_11" 12 "BCMRLObsRng_Range_12" 13 "BCMRLObsRng_Range_13" 14 "BCMRLObsRng_Range_14" 15 "BCMRLObsRng_Range_15";
VAL_ 691 BCMRrMidLObsRng 0 "BCMRrMidLObsRng_No_Obstacle" 1 "BCMRrMidLObsRng_Range_1" 2 "BCMRrMidLObsRng_Range_2" 3 "BCMRrMidLObsRng_Range_3" 4 "BCMRrMidLObsRng_Range_4" 5 "BCMRrMidLObsRng_Range_5" 6 "BCMRrMidLObsRng_Range_6" 7 "BCMRrMidLObsRng_Range_7" 8 "BCMRrMidLObsRng_Range_8" 9 "BCMRrMidLObsRng_Range_9" 10 "BCMRrMidLObsRng_Range_10" 11 "BCMRrMidLObsRng_Range_11" 12 "BCMRrMidLObsRng_Range_12" 13 "BCMRrMidLObsRng_Range_13" 14 "BCMRrMidLObsRng_Range_14" 15 "BCMRrMidLObsRng_Range_15";
VAL_ 691 BCMRrMidRObsRng 0 "BCMRrMidRObsRng_No_Obstacle" 1 "BCMRrMidRObsRng_Range_1" 2 "BCMRrMidRObsRng_Range_2" 3 "BCMRrMidRObsRng_Range_3" 4 "BCMRrMidRObsRng_Range_4" 5 "BCMRrMidRObsRng_Range_5" 6 "BCMRrMidRObsRng_Range_6" 7 "BCMRrMidRObsRng_Range_7" 8 "BCMRrMidRObsRng_Range_8" 9 "BCMRrMidRObsRng_Range_9" 10 "BCMRrMidRObsRng_Range_10" 11 "BCMRrMidRObsRng_Range_11" 12 "BCMRrMidRObsRng_Range_12" 13 "BCMRrMidRObsRng_Range_13" 14 "BCMRrMidRObsRng_Range_14" 15 "BCMRrMidRObsRng_Range_15";
VAL_ 691 BCMRRObsRng 0 "BCMRRObsRng_No_Obstacle" 1 "BCMRRObsRng_Range_1" 2 "BCMRRObsRng_Range_2" 3 "BCMRRObsRng_Range_3" 4 "BCMRRObsRng_Range_4" 5 "BCMRRObsRng_Range_5" 6 "BCMRRObsRng_Range_6" 7 "BCMRRObsRng_Range_7" 8 "BCMRRObsRng_Range_8" 9 "BCMRRObsRng_Range_9" 10 "BCMRRObsRng_Range_10" 11 "BCMRRObsRng_Range_11" 12 "BCMRRObsRng_Range_12" 13 "BCMRRObsRng_Range_13" 14 "BCMRRObsRng_Range_14" 15 "BCMRRObsRng_Range_15";
VAL_ 691 BCMRrPDCAudWrnng 0 "BCMRrPDCAudWrnng_No_Obstacle" 1 "BCMRrPDCAudWrnng_Range_1" 2 "BCMRrPDCAudWrnng_Range_2" 3 "BCMRrPDCAudWrnng_Range_3" 4 "BCMRrPDCAudWrnng_Range_4" 5 "BCMRrPDCAudWrnng_Range_5" 6 "BCMRrPDCAudWrnng_Range_6" 7 "BCMRrPDCAudWrnng_Range_7" 8 "BCMRrPDCAudWrnng_Range_8" 9 "BCMRrPDCAudWrnng_Range_9" 10 "BCMRrPDCAudWrnng_Range_10" 11 "BCMRrPDCAudWrnng_Range_11" 12 "BCMRrPDCAudWrnng_Range_12" 13 "BCMRrPDCAudWrnng_Range_13" 14 "BCMRrPDCAudWrnng_Range_14" 15 "BCMRrPDCAudWrnng_Range_15";
VAL_ 822 BCMFLSeatHeatLvl 0 "BCMFLSeatHeatLvl_OFF" 1 "BCMFLSeatHeatLvl_Front_left_seat_heat_level_1" 2 "BCMFLSeatHeatLvl_Front_left_seat_heat_level_2" 3 "BCMFLSeatHeatLvl_Front_left_seat_heat_level_3";
VAL_ 822 BCMFRSeatHeatLvl 0 "BCMFRSeatHeatLvl_OFF" 1 "Front right seat heat level 1" 2 "Front right seat heat level 2" 3 "Front right seat heat level 3";
VAL_ 822 DrvrPWLInitnRmndr 0 "False" 1 "True";
VAL_ 822 DrvrWndDclnSpc 255 "DrvrWndDclnSpc_not_initialized";
VAL_ 822 DrvrWndOpenRmndr 0 "False" 1 "True";
VAL_ 822 FrtPsngPWLInitnRmndr 0 "False" 1 "True";
VAL_ 822 FrtPsngWndDclnSpc 255 "FrtPsngWndDclnSpc_not_initialized";
VAL_ 822 FrtPsngWndOpenRmndr 0 "False" 1 "True";
VAL_ 822 OtsdMirFoldSts 0 "OtsdMirFoldStsInitial" 1 "OtsdMirFoldSts_Unfold_State" 2 "OtsdMirFoldSts_Fold_State" 3 "OtsdMirFoldStsFailiure";
VAL_ 822 RLPWLInitnRmndr 0 "False" 1 "True";
VAL_ 822 RLWndDclnSpc 255 "RLWndDclnSpc_not_initialized";
VAL_ 822 RLWndOpenRmndr 0 "False" 1 "True";
VAL_ 822 RRPWLInitnRmndr 0 "False" 1 "True";
VAL_ 822 RRWndDclnSpc 255 "RRWndDclnSpc_not_initialized";
VAL_ 822 RRWndOpenRmndr 0 "False" 1 "True";
VAL_ 822 SrfInitnRmndr 0 "False" 1 "True";
VAL_ 822 SrfOpenRmndr 0 "False" 1 "True";
VAL_ 822 SrfTiltSts 0 "SrfTiltSts_Tilt_Close" 1 "SrfTiltSts_Tilt_Open";
VAL_ 815 BntOpenSts 0 "BntOpenSts_Bonnet_Closed" 1 "BntOpenSts_Bonnet_Open" 2 "BntOpenSts_Bonnet_Switch_Disconnect" 3 "BntOpenSts_3_Reserved";
VAL_ 815 DrvrDoorOpenSts 0 "DrvrDoorOpenSts_Driver_Door_Closed" 1 "DrvrDoorOpenSts_Driver_Door_Open_For_latch_switch_can_t_detect_door_ajar_status_" 2 "DrvrDoorOpenSts_Driver_Door_Ajar" 3 "DrvrDoorOpenSts_Driver_Door_Full_Open";
VAL_ 815 FrtPsngDoorOpenSts 0 "FrtPsngDoorOpenSts_Front_Passenger_Door_Closed" 1 "FrtPsngDoorOpenSts_Front_Passenger_Open_latch_switch_cann_t_detect_door_ajar_statu" 2 "FrtPsngDoorOpenSts_Front_Passenger_Door_Ajar" 3 "FrtPsngDoorOpenSts_Front_Passenger_Door_Full_Open";
VAL_ 815 FrtWiperMdSts 0 "FrtWiperMdSts_Wiper_off" 1 "FrtWiperMdSts_Intermittent_Mode_level_1_Slowest_" 2 "FrtWiperMdSts_Intermittent_Mode_level_2" 3 "FrtWiperMdSts_Intermittent_Modelevel_3" 4 "FrtWiperMdSts_Intermittent_Mode_level_4" 5 "FrtWiperMdSts_Slow_Mode_Request" 6 "FrtWiperMdSts_Fast_Mode_Request" 7 "FrtWiperMdSts_Reserved";
VAL_ 815 FrtWiperOpReq 0 "FrtWiperOpReq_wiper_off" 1 "FrtWiperOpReq_slow_speed_wipe_single_" 2 "FrtWiperOpReq_slow_speed_wipe_continuous_" 3 "FrtWiperOpReq_fast_speed_wipe" 4 "FrtWiperOpReq_fault_mode" 5 "FrtWiperOpReq_5_reserved" 6 "FrtWiperOpReq_6_reserved" 7 "FrtWiperOpReq_7_reserved";
VAL_ 815 FrtWiperSwSts 0 "FrtWiperSwSts_wipers_off" 1 "FrtWiperSwSts_wipers_in_intermittent_mode" 2 "FrtWiperSwSts_wipers_in_slow_mode" 3 "FrtWiperSwSts_wipers_in_fast_mode";
VAL_ 815 FrtWshrPumpA 0 "False" 1 "True";
VAL_ 815 LdspcOpenSts 0 "LdspcOpenSts_Load_Space_Closed" 1 "LdspcOpenSts_Load_Space_Open" 2 "LdspcOpenSts_2_Reserved" 3 "LdspcOpenSts_3_Reserved";
VAL_ 815 LowWiperWshrFludLvlSwA 0 "False" 1 "True";
VAL_ 815 RLDoorOpenSts 0 "RLDoorOpenSts_Rear_Left_Door_Closed" 1 "RLDoorOpenSts_Rear_Left_Door_Open_latch_switch_cann_t_detect_door_ajar_status" 2 "RLDoorOpenSts_Rear_Left_Door_Ajar" 3 "RLDoorOpenSts_Rear_Left_Door_Full_Open";
VAL_ 815 RRDoorOpenSts 0 "RRDoorOpenSts_Rear_Right_Door_Closed" 1 "RRDoorOpenSts_Rear_Right_Door_Open_latch_switch_cann_t_detect_door_ajar_status" 2 "RRDoorOpenSts_Rear_Right_Door_Ajar" 3 "RRDoorOpenSts_Rear_Right_Door_Full_Open";
VAL_ 815 RrDoorsOpenSts 0 "RrDoorsOpenSts_Rear_Left_or_Right_Door_Closed" 1 "RrDoorsOpenSts_Rear_Left_or_Right_Door_Open_latch_switch_cann_t_detect_door_ajar_status" 2 "RrDoorsOpenSts_Rear_Left_or_Right_Door_Ajar" 3 "RrDoorsOpenSts_Rear_Left_or_Right_Door_Full_Open";
VAL_ 815 RrWiperMdSts 0 "RrWiperMdSts_Off_Mode" 1 "RrWiperMdSts_Intermittent_Mode" 2 "RrWiperMdSts_On_Continuous_Mode" 3 "RrWiperMdSts_Reserved";
VAL_ 815 RrWshrPumpA 0 "False" 1 "True";
VAL_ 815 ScurtAlrmSts 0 "ScurtAlrmSts_off" 1 "ScurtAlrmSts_part_alarm_without_volumetrics" 2 "ScurtAlrmSts_full_alarm_without_volumetrics" 3 "ScurtAlrmSts_3_not_used" 4 "ScurtAlrmSts_4_not_used" 5 "ScurtAlrmSts_part_alarm_with_volumetrics" 6 "ScurtAlrmSts_full_alarm_with_volumetrics" 7 "ScurtAlrmSts_7_not_used";
VAL_ 815 ScurtAlrmTrigd 0 "False" 1 "True";
VAL_ 815 VehLckngSta 0 "Unlocked" 1 "Signal_Position_Entry_Unlocked" 2 "Interior_Locked" 3 "Exterior_Locked" 4 "Super_locked" 5 "VehLckngSta_Reserved5" 6 "VehLckngSta_Reserved6" 7 "Unknow";
VAL_ 830 BCMGearShftParkNtrlEnStngRmndr 0 "False" 1 "True";
VAL_ 830 BCMNoSmtKeyInVehRmndr 0 "False" 1 "True";
VAL_ 830 BCMNoSmtKeyPressBrkToRestRmndr 0 "False" 1 "True";
VAL_ 830 BCMNoSmtKeyPressClToRestRmndr 0 "False" 1 "True";
VAL_ 830 BCMPressBrkRmndr 0 "False" 1 "True";
VAL_ 830 BCMPressClRmndr 0 "False" 1 "True";
VAL_ 830 BCMPutSmtKeyToBkupPosR 0 "False" 1 "True";
VAL_ 830 BCMShftParkRmndr 0 "False" 1 "True";
VAL_ 830 BCMSyncSmtKeyRmndr 0 "False" 1 "True";
VAL_ 830 BCMTakeSmtKeyOutOfSlotRmndr 0 "False" 1 "True";
VAL_ 830 MPWCSta 0 "MPWCSta_0_Reserved" 1 "MPWCSta_1_Standby" 2 "MPWCSta_2_Charging" 3 "MPWCSta_3_Over_voltage" 4 "MPWCSta_4_Low_voltage" 5 "MPWCSta_5_FOD" 6 "MPWCSta_6_Over_temperature" 7 "MPWCSta_7_Other_fault" 8 "MPWCSta_8_PEPS_inhabit_enable" 9 "MPWCSta_9_Full" 10 "MPWCSta_10_Reserved" 11 "MPWCSta_11_Reserved" 12 "MPWCSta_12_Reserved" 13 "MPWCSta_13_Reserved" 14 "MPWCSta_14_Reserved" 15 "MPWCSta_15_Reserved";
VAL_ 830 ScurtKeyBatLow 0 "False" 1 "True";
VAL_ 830 ShifterLckRlseBrkReqA 0 "False" 1 "True";
VAL_ 830 SSBEnOffRmndr 0 "SSBEnOffRmndr_No_Reminder_Request" 1 "SSBEnOffRmndr_Press_Button_Again_To_Turn_Engine_Off_Reminder" 2 "SSBEnOffRmndr_Long_Press_Button_Again_To_Turn_Engine_Off_Reminder" 3 "SSBEnOffRmndr_Press_Button_Twice_Again_To_Turn_Engine_Off_Reminder";
VAL_ 830 TakeKeyOutRmndr 0 "False" 1 "True";
VAL_ 804 AutocLghtIndReq 0 "AutocLghtIndReq_Off" 1 "AutocLghtIndReq_Automatic_Lights_Active_Indication_On" 2 "AutocLghtIndReq_Automatic_Lights_Inactive_Indication_On" 3 "AutocLghtIndReq_Reserved";
VAL_ 804 AutoMainBeamLghtOn 0 "False" 1 "True";
VAL_ 804 CHMSLF 0 "False" 1 "True";
VAL_ 804 DayTimeRunningLampOn 0 "False" 1 "True";
VAL_ 804 DayTimeRunningLghtF 0 "False" 1 "True";
VAL_ 804 DimLghtLvl 251 "DimLghtLvl_251_reserved" 252 "DimLghtLvl_252_reserved" 253 "DimLghtLvl_253_reserved" 254 "DimLghtLvl_254_reserved" 255 "DimLghtLvl_255_reserved";
VAL_ 804 DipdBeamLghtOn 0 "False" 1 "True";
VAL_ 804 DircnIndLampSwSts 0 "DircnIndLampSwSts_0_off" 1 "DircnIndLampSwSts_Left_on" 2 "DircnIndLampSwSts_Right_on" 3 "DircnIndLampSwSts_3_reserve";
VAL_ 804 FrtFogLghtOn 0 "False" 1 "True";
VAL_ 804 FrtSideLghtF 0 "False" 1 "True";
VAL_ 804 LBrkLghtF 0 "False" 1 "True";
VAL_ 804 LDipdBeamLghtF 0 "False" 1 "True";
VAL_ 804 LDircnIndLghtF 0 "False" 1 "True";
VAL_ 804 LghtSwPosSts 0 "LghtSwPosSts_Switch_is_on_Off_position" 1 "LghtSwPosSts_Switch_is_on_Auto_position" 2 "LghtSwPosSts_Side_Lamp" 3 "LghtSwPosSts_Dipped_Beam" 4 "LghtSwPosSts_Unknow_position" 5 "LghtSwPosSts_5_reserved" 6 "LghtSwPosSts_6_reserved" 7 "LghtSwPosSts_7_reserved";
VAL_ 804 LSideLghtF 0 "False" 1 "True";
VAL_ 804 MainBeamLghtOn 0 "False" 1 "True";
VAL_ 804 RBrkLghtF 0 "False" 1 "True";
VAL_ 804 RDipdBeamLghtF 0 "False" 1 "True";
VAL_ 804 RDircnIndLghtF 0 "False" 1 "True";
VAL_ 804 RevsLghtF 0 "False" 1 "True";
VAL_ 804 RgstnPltLghtF 0 "False" 1 "True";
VAL_ 804 RrFogLghtF 0 "False" 1 "True";
VAL_ 804 RrFogLghtOn 0 "False" 1 "True";
VAL_ 804 RrSideLghtF 0 "False" 1 "True";
VAL_ 804 RSideLghtF 0 "False" 1 "True";
VAL_ 804 VehSideLghtSts 0 "VehSideLghtSts_No_side_light_on" 1 "VehSideLghtSts_Left_side_light_on_only" 2 "VehSideLghtSts_Right_side_light_on_only" 3 "VehSideLghtSts_All_side_light_and_license_plate_light_on";
VAL_ 1127 BCMOdoReq 0 "False" 1 "True";
VAL_ 1051 AmbtLghtCustSetngDspCmd 0 "AmbtLghtCustSetngDspCmd_Function_Disable" 1 "AmbtLghtCustSetngDspCmd_Super_ECO" 2 "AmbtLghtCustSetngDspCmd_ECO" 3 "AmbtLghtCustSetngDspCmd_Normal" 4 "AmbtLghtCustSetngDspCmd_Sport" 5 "AmbtLghtCustSetngDspCmd_Super_Sport";
VAL_ 1051 AmbtLghtDrvMdCustOnOffDspCmd 0 "AmbtLghtDrvMdCustOnOffDspCmd_Off" 1 "AmbtLghtDrvMdCustOnOffDspCmd_On";
VAL_ 1051 AmbtLghtDrvMdOnOffDspCmd 0 "AmbtLghtDrvMdOnOffDspCmd_Reserved" 1 "AmbtLghtDrvMdOnOffDspCmd_Off" 2 "AmbtLghtDrvMdOnOffDspCmd_On" 3 "AmbtLghtDrvMdOnOffDspCmd_Auto";
VAL_ 1051 AmbtLghtGlbOnOffDspCmd 0 "AmbtLghtGlbOnOffDspCmd_Off" 1 "AmbtLghtGlbOnOffDspCmd_On";
VAL_ 1051 AmbtLghtIgnMdDspCmd 0 "AmbtLghtIgnMdDspCmd_Mode_1" 1 "AmbtLghtIgnMdDspCmd_Mode_2" 2 "AmbtLghtIgnMdDspCmd_Mode_3" 3 "AmbtLghtIgnMdDspCmd_Reserved1" 4 "AmbtLghtIgnMdDspCmd_Reserved2" 5 "AmbtLghtIgnMdDspCmd_Reserved3" 6 "AmbtLghtIgnMdDspCmd_Reserved4" 7 "AmbtLghtIgnMdDspCmd_Reserved5";
VAL_ 1051 AmbtLghtIgnMdOnOffDspCmd 0 "AmbtLghtIgnMdOnOffDspCmd_Off" 1 "AmbtLghtIgnMdOnOffDspCmd_On";
VAL_ 1051 AmbtLghtLvl 0 "AmbtLghtLvl_Level_0_Day_position_lamp_and_dipped_beam_off_" 1 "AmbtLghtLvl_Level_1_Reserved_for_position_lamp_On_Request_" 2 "AmbtLghtLvl_Level_2_Dipped_Beam_On_Request" 3 "AmbtLghtLvl_Level_3_Reserved_";
VAL_ 1051 AmbtLghtWlcmMdDspCmd 0 "AmbtLghtWlcmMdDspCmd_Mode_1" 1 "AmbtLghtWlcmMdDspCmd_Mode_2" 2 "AmbtLghtWlcmMdDspCmd_Mode_3" 3 "AmbtLghtWlcmMdDspCmd_Reserved1" 4 "AmbtLghtWlcmMdDspCmd_Reserved2" 5 "AmbtLghtWlcmMdDspCmd_Reserved3" 6 "AmbtLghtWlcmMdDspCmd_Reserved4" 7 "AmbtLghtWlcmMdDspCmd_Reserved5";
VAL_ 1051 AmbtLghtWlcmMdOnOffDspCmd 0 "AmbtLghtWlcmMdOnOffDspCmd_Off" 1 "AmbtLghtWlcmMdOnOffDspCmd_On";
VAL_ 1051 AmbtLghtZoneCtrlDspCmd 0 "AmbtLghtZoneCtrlDspCmd_0_No_request" 1 "AmbtLghtZoneCtrlDspCmd_1_Only_door_lights_on" 2 "AmbtLghtZoneCtrlDspCmd_2_Only_instrument_panel_lights_on" 3 "AmbtLghtZoneCtrlDspCmd_3_All_lights_on" 4 "AmbtLghtZoneCtrlDspCmd_4_Reserved" 5 "AmbtLghtZoneCtrlDspCmd_5_Reserved" 6 "AmbtLghtZoneCtrlDspCmd_6_Reserved" 7 "AmbtLghtZoneCtrlDspCmd_7_Reserved";
VAL_ 1051 CotsyLghtA 0 "False" 1 "True";
VAL_ 556 BCMEmgcSp 0 "False" 1 "True";
VAL_ 556 BCMRunCrkF 0 "False" 1 "True";
VAL_ 556 BCMSSBA 0 "BCMSSBA_Inactive" 1 "BCMSSBA_Active";
VAL_ 556 BCMSSBAV 0 "Valid" 1 "Invalid";
VAL_ 556 BCMSSBFltSts 0 "BCMSSBFltSts_No_Fault" 1 "BCMSSBFltSts_short_to_GND" 2 "BCMSSBFltSts_short_to_Battery" 3 "BCMSSBFltSts_Stuck" 4 "BCMSSBFltSts_Open_Circuit" 5 "BCMSSBFltSts_switch_failed" 6 "BCMSSBFltSts_6_Reserved" 7 "BCMSSBFltSts_7_Reserved";
VAL_ 556 KeyDetIndx 0 "KeyDetIndx_non_key_is_detected" 1 "KeyDetIndx_key_1_is_detected" 2 "KeyDetIndx_key_2_is_detected" 3 "KeyDetIndx_key_3_is_detected" 4 "KeyDetIndx_key_4_is_detected" 5 "KeyDetIndx_key_5_is_detected" 6 "KeyDetIndx_key_6_is_detected" 7 "KeyDetIndx_Error_";
VAL_ 556 RVSSts 0 "RVSSts_0_Inactive" 1 "RVSSts_1_Active";
VAL_ 556 ScurtKeyInvd 0 "False" 1 "True";
VAL_ 556 SysBPM 0 "SysBPM_Off" 1 "SysBPM_ACC" 2 "SysBPM_Run" 3 "SysBPM_Crank_Request";
VAL_ 556 SysBPMEnbd 0 "False" 1 "True";
VAL_ 135 LDircnIO 0 "False" 1 "True";
VAL_ 135 RDircnIO 0 "False" 1 "True";
VAL_ 720 BCMOtsdMirFoldCmd 0 "BCMOtsdMirFoldCmd_0_No_Outside_Mirror_Fold_Unfold" 1 "BCMOtsdMirFoldCmd_1_Outside_Mirror_Fold" 2 "BCMOtsdMirFoldCmd_2_Outside_Mirror_Unfold" 3 "BCMOtsdMirFoldCmd_3_Outside_Mirror_Fold_Unfold_Inhibit_For_Vehicle_Moving";
VAL_ 720 LOtsdMirMmryCtrlPosRclSts 0 "LOtsdMirMmryCtrlPosRclSts_0_No_Action" 1 "LOtsdMirMmryCtrlPosRclSts_1_Recall_in_Process" 2 "LOtsdMirMmryCtrlPosRclSts_2_Recall_Success" 3 "LOtsdMirMmryCtrlPosRclSts_3_Recall_Failed" 4 "LOtsdMirMmryCtrlPosRclSts_4_Unavailable";
VAL_ 720 LowrCnsoSwSeld 0 "False" 1 "True";
VAL_ 720 ROtsdMirMmryCtrlPosRclSts 0 "ROtsdMirMmryCtrlPosRclSts_0_No_Action" 1 "ROtsdMirMmryCtrlPosRclSts_1_Recall_in_Process" 2 "ROtsdMirMmryCtrlPosRclSts_2_Recall_Success" 3 "ROtsdMirMmryCtrlPosRclSts_3_Recall_Failed" 4 "ROtsdMirMmryCtrlPosRclSts_4_Unavailable";
VAL_ 879 ARSAnPnchSta 0 "False" 1 "True";
VAL_ 879 ARSAutoMdInfo 0 "False" 1 "True";
VAL_ 879 ARSErFdbk 0 "ARSErFdbk_0_Normal" 1 "ARSErFdbk_1_Error";
VAL_ 879 ARSMvSta 0 "ARSMvSta_0_Not_Ready" 1 "ARSMvSta_1_Fully_Open" 2 "ARSMvSta_2_Fully_Closed" 3 "ARSMvSta_3_Opening" 4 "ARSMvSta_4_Closing" 5 "ARSMvSta_5_Suspended" 6 "ARSMvSta_6_Uninitialized" 7 "ARSMvSta_7_Reserved";
VAL_ 577 BlePEPSBkupSt 0 "BlePEPSBkupSt_False" 1 "BlePEPSBkupSt_True";
VAL_ 577 BlePEPSEntFnFlr 0 "BlePEPSEntFnFlr_False" 1 "BlePEPSEntFnFlr_True";
VAL_ 577 DigKeyInCar 0 "DigKeyInCar_0_False" 1 "DigKeyInCar_1_True";
VAL_ 577 DigKeyInvd 0 "DigKeyInvd_Valid" 1 "DigKeyInvd_Invalid";
VAL_ 577 DigKeyNotDet 0 "DigKeyNotDet_0_False" 1 "DigKeyNotDet_1_True";
VAL_ 577 DigKeyWillBeInvd 0 "DigKeyWillBeInvd_Valid" 1 "DigKeyWillBeInvd_Invalid";
VAL_ 1022 BleCmftLckDsp 0 "BleCmftLckDsp_0_Function_disable" 1 "BleCmftLckDsp_1_Unavailable" 2 "BleCmftLckDsp_2_OFF" 3 "BleCmftLckDsp_3_ON";
VAL_ 1022 BleWlcmFnDsp 0 "BleWlcmFnDsp_0_Function_disable" 1 "BleWlcmFnDsp_1_Unavailable" 2 "BleWlcmFnDsp_2_OFF" 3 "BleWlcmFnDsp_3_ON";
VAL_ 1022 PhnKeyA 0 "PhnKeyA_0_InActive" 1 "PhnKeyA_1_Active";
VAL_ 1022 PhnKeyCphrUpdtFdbk 0 "PhnKeyCphrUpdtFdbk_0_FunctionDisable" 1 "PhnKeyCphrUpdtFdbk_1_Unavailable" 2 "PhnKeyCphrUpdtFdbk_2_NoRequst" 3 "PhnKeyCphrUpdtFdbk_3_UpdateOK";
VAL_ 1022 PhnKeyRstFdbk 0 "PhnKeyRstFdbk_0_FunctionDisable" 1 "PhnKeyRstFdbk_1_Unavailable" 2 "PhnKeyRstFdbk_2_NoRequst" 3 "PhnKeyRstFdbk_3_ResetOK";
VAL_ 554 DMSAdoWrnngDspCmd 0 "DMSAdoWrnngDspCmd_0_Unavailable" 1 "DMSAdoWrnngDspCmd_1_Off" 2 "DMSAdoWrnngDspCmd_2_On" 3 "DMSAdoWrnngDspCmd_3_laststatus";
VAL_ 554 DMSAudReq 0 "DMSAudReq_0_Norequest" 1 "DMSAudReq_1_Low" 2 "DMSAudReq_2_Middle" 3 "DMSAudReq_3_High";
VAL_ 554 DMSDspCmd 0 "DMSDspCmd_0_Unavailable" 1 "DMSDspCmd_1_Off" 2 "DMSDspCmd_2_On" 3 "DMSDspCmd_3_reserved";
VAL_ 554 DMSHapticWrnngDspCmd 0 "DMSHapticWrnngDspCmd_0_Unavailable" 1 "DMSHapticWrnngDspCmd_1_Off" 2 "DMSHapticWrnngDspCmd_2_On" 3 "DMSHapticWrnngDspCmd_3_laststatus";
VAL_ 554 DMSSts 0 "DMSSts_0_Off" 1 "DMSSts_1_Standby" 2 "DMSSts_2_Active" 3 "DMSSts_3_Camera_Blocked" 4 "DMSSts_4_System_temporary_unavailable" 5 "DMSSts_5_Service_required" 6 "DMSSts_6_Initialization" 7 "DMSSts_7_Reserved";
VAL_ 554 DMSWrnngReq 0 "DMSWrnngReq_0_Norequest" 1 "DMSWrnngReq_1_Fatiguerequest" 2 "DMSWrnngReq_2_Distractionrequest" 3 "DMSWrnngReq_3_Reserve" 4 "DMSWrnngReq_4_Reserve" 5 "DMSWrnngReq_5_Reserve" 6 "DMSWrnngReq_6_Reserve" 7 "DMSWrnngReq_7_Reserve";
VAL_ 201 AccelActuPosV 0 "AccelActuPosV_0_Valid" 1 "AccelActuPosV_1_Invalid";
VAL_ 201 CCA 0 "False" 1 "True";
VAL_ 201 CCEnbd 0 "False" 1 "True";
VAL_ 201 En12VoltStrMotCmddOn 0 "False" 1 "True";
VAL_ 201 EnRunA 0 "False" 1 "True";
VAL_ 201 EnSpdSts 0 "EnSpdSts_Normal_Operation" 1 "EnSpdSts_Degraded_Operation" 2 "EnSpdSts_Reserved" 3 "EnSpdSts_Invalid";
VAL_ 404 AutocTrCmddGear 0 "AutocTrCmddGear_Not_Supported" 1 "AutocTrCmddGear_First_Gear" 2 "AutocTrCmddGear_Second_Gear" 3 "AutocTrCmddGear_Third_Gear" 4 "AutocTrCmddGear_Fourth_Gear" 5 "AutocTrCmddGear_Fifth_Gear" 6 "AutocTrCmddGear_Sixth_Gear" 7 "AutocTrCmddGear_Seventh_Gear" 8 "AutocTrCmddGear_Eighth_Gear" 10 "AutocTrCmddGear_10_reserved" 11 "AutocTrCmddGear_11_reserved" 12 "AutocTrCmddGear_12_reserved" 13 "AutocTrCmddGear_Neutral_Gear" 14 "AutocTrCmddGear_Reverse_Gear" 15 "AutocTrCmddGear_Park_Gear";
VAL_ 404 ClPosV 0 "Valid" 1 "Invalid";
VAL_ 404 ClStSwA 0 "False" 1 "True";
VAL_ 404 ClStSwAV 0 "Valid" 1 "Invalid";
VAL_ 404 DrvrShftCtrlTrgtGear 0 "DrvrShftCtrlTrgtGear_Not_Supported" 1 "DrvrShftCtrlTrgtGear_First_Gear" 2 "DrvrShftCtrlTrgtGear_Second_Gear" 3 "DrvrShftCtrlTrgtGear_Third_Gear" 4 "DrvrShftCtrlTrgtGear_Fourth_Gear" 5 "DrvrShftCtrlTrgtGear_Fifth_Gear" 6 "DrvrShftCtrlTrgtGear_Sixth_Gear" 7 "DrvrShftCtrlTrgtGear_Seventh_Gear" 8 "DrvrShftCtrlTrgtGear_Eighth_Gear";
VAL_ 404 TrEstdGear 0 "TrEstdGear_Not_Supported" 1 "TrEstdGear_First_Gear" 2 "TrEstdGear_Second_Gear" 3 "TrEstdGear_Third_Gear" 4 "TrEstdGear_Fourth_Gear" 5 "TrEstdGear_Fifth_Gear" 6 "TrEstdGear_Sixth_Gear" 7 "TrEstdGear_Seventh_Gear" 8 "TrEstdGear_Eighth_Gear" 10 "TrEstdGear_10_reserved" 11 "TrEstdGear_11_reserved" 12 "TrEstdGear_12_reserved" 13 "TrEstdGear_Neutral_Gear" 14 "TrEstdGear_Reverse_Gear" 15 "TrEstdGear_Park_Gear";
VAL_ 404 TrEstdGearV 0 "Valid" 1 "Invalid";
VAL_ 404 TrShftLvrPos 0 "TrShftLvrPos_h1_Between_Ranges" 1 "TrShftLvrPos_h1_Park_Range" 2 "TrShftLvrPos_h1_Reverse_Range" 3 "TrShftLvrPos_h1_Neutral_Range" 4 "TrShftLvrPos_h1_Forward_Range_A" 5 "TrShftLvrPos_h1_Forward_Range_B" 6 "TrShftLvrPos_h1_Forward_Range_C" 7 "TrShftLvrPos_h1_Forward_Range_D" 8 "TrShftLvrPos_h1_Forward_Range_E" 9 "TrShftLvrPos_h1_Forward_Range_F" 10 "TrShftLvrPos_h1_Forward_Range_G" 11 "TrShftLvrPos_h1_Forward_Range_H" 15 "TrShftLvrPos_h1_Lever_Position_Unknown";
VAL_ 404 TrShftLvrPosV 0 "Valid" 1 "Invalid";
VAL_ 404 TrShftPtrnASts 0 "TrShftPtrnASts_Default_Shift_Pattern_Active" 1 "TrShftPtrnASts_Shift_Pattern_1_Active" 2 "TrShftPtrnASts_Shift_Pattern_2_Active" 3 "TrShftPtrnASts_Shift_Pattern_3_Active" 4 "TrShftPtrnASts_Shift_Pattern_4_Active" 5 "TrShftPtrnASts_PT_Non_Protection_Pattern_Active" 6 "TrShftPtrnASts_PT_Protection_Pattern_Active";
VAL_ 404 TrTapUpTapDwnMdSts 0 "TrTapUpTapDwnMdSts_0_No_Activation" 1 "TrTapUpTapDwnMdSts_1_Driver_Shift_Control_Active" 2 "TrTapUpTapDwnMdSts_2_Electronic_Range_Select_Active";
VAL_ 707 EcoDrvngAIO 0 "False" 1 "True";
VAL_ 707 EcoDrvngDspStsGearShftIndSts 0 "No_Shift" 1 "Gear_Shift_Up" 2 "Gear_Shift_Down" 3 "Reserved";
VAL_ 707 EcoDrvngDspStsRcmndFwdGear 0 "None" 1 "First_Gear" 2 "Second_Gear" 3 "Third_Gear" 4 "Fouth_Gear" 5 "Fifth_Gear" 6 "Sixth_Gear" 7 "Seventh_Gear" 8 "Eighth_Gear" 9 "Unused_and_Reserved_1" 10 "Unused_and_Reserved_2" 11 "Unused_and_Reserved_3" 12 "Unused_and_Reserved_4" 13 "Unused_and_Reserved_5" 14 "Unused_and_Reserved_6" 15 "Unused_and_Reserved_7";
VAL_ 707 ECODrvngSpdRutA 0 "False" 1 "True";
VAL_ 945 CCFltPrst 0 "False" 1 "True";
VAL_ 945 ECMClsDoorToAutoStR 0 "False" 1 "True";
VAL_ 945 ECMFasnSbltToAutoStR 0 "False" 1 "True";
VAL_ 945 ECMPressClBrkRmndr 0 "ECMPressClBrkRmndr_No_message" 1 "ECMPressClBrkRmndr_Press_the_clutch" 2 "ECMPressClBrkRmndr_Press_the_brake" 3 "ECMPressClBrkRmndr_Reserved";
VAL_ 945 ECMShftNtrlToAutoStR 0 "False" 1 "True";
VAL_ 945 KeyRestRqd 0 "False" 1 "True";
VAL_ 977 EnEmsnRltdMalfA 0 "False" 1 "True";
VAL_ 977 EnEmsnRltdMalfIndReq 0 "EnEmsnRltdMalfIndReq_Continuous_Indication" 1 "EnEmsnRltdMalfIndReq_No_Indication" 2 "EnEmsnRltdMalfIndReq_Flashing_1_Hertz_Indication" 3 "EnEmsnRltdMalfIndReq_Flashing_2_Hertz_Indication" 4 "EnEmsnRltdMalfIndReq_Flashing_0_5_Hertz_Indication" 5 "EnEmsnRltdMalfIndReq_5_Reserved" 6 "EnEmsnRltdMalfIndReq_6_Reserved" 7 "EnEmsnRltdMalfIndReq_7_Reserved";
VAL_ 977 EnGPFLampOnSts 0 "EnGPFLampOnSts_Off" 1 "EnGPFLampOnSts_GPF_Regeneration_Reminder" 2 "EnGPFLampOnSts_GPF_Regenerating_Active" 3 "EnGPFLampOnSts_GPF_Full_Reminder";
VAL_ 977 EnNonEmsnRltdMalfA 0 "False" 1 "True";
VAL_ 977 TrNonEmsnRltdMalfA_ECM 0 "False" 1 "True";
VAL_ 1141 BarPrsAbsV 0 "Valid" 1 "Invalid";
VAL_ 1141 EnClntTemV 0 "Valid" 1 "Invalid";
VAL_ 1141 TrClThrmlProtnNotfn_ECM 0 "No_Indication" 1 "Indication_1" 2 "Indication_2" 3 "Indication_3" 4 "Indication_4" 5 "Indication_5" 6 "Indication_6" 7 "Indication_7" 8 "Indication_8" 9 "Indication_9" 10 "Indication_10" 11 "Indication_11" 12 "Indication_12" 13 "Indication_13" 14 "Indication_14" 15 "Indication_15";
VAL_ 884 ExhSptyMdDspCmd 0 "ExhSptyMdDspCmd_0_EAV_silence_mode" 1 "ExhSptyMdDspCmd_1_EAV_normal_sporty_mode" 2 "ExhSptyMdDspCmd_2_EAV_super_sporty_mode" 3 "ExhSptyMdDspCmd_3_EAV_customer_sporty_mode";
VAL_ 85 StrgWhlAng 65535 "StrgWhlAng_error_mark";
VAL_ 85 StrgWhlAngGrd 4095 "StrgWhlAngGrd_error_mark";
VAL_ 85 StrgWhlAngSnsrCalSts 0 "StrgWhlAngSnsrCalSts_0_Unknown" 1 "StrgWhlAngSnsrCalSts_Estimated" 2 "StrgWhlAngSnsrCalSts_Calibrated" 3 "StrgWhlAngSnsrCalSts_3_Unknown";
VAL_ 85 StrgWhlAngSnsrFlt 0 "False" 1 "True";
VAL_ 85 StrgWhlAngSnsrInid 0 "False" 1 "True";
VAL_ 85 StrgWhlAngSnsrMultCapb 0 "False" 1 "True";
VAL_ 85 StrgWhlAngV 0 "Valid" 1 "Invalid";
VAL_ 328 EPSFlrSts 0 "EPSFlrSts_EPS_No_failure_Indication_off_" 1 "EPSFlrSts_EPS_Light_Level_failure_indication_Orange_" 2 "EPSFlrSts_EPS_Heavy_Level_failure_indication_Red_" 3 "EPSFlrStsInvalid";
VAL_ 328 EPSIntAngInidDspReq 0 "EPSIntAngInidDspReq_0_NoRequest" 1 "EPSIntAngInidDspReq_1_InitializationDisplayRequest" 2 "EPSIntAngInidDspReq_2_Reserved" 3 "EPSIntAngInidDspReq_3_Reserved";
VAL_ 827 ACCDetObjRisk 0 "ACCDetObjRisk_0_NoRisk" 1 "ACCDetObjRisk_1_RiskExist";
VAL_ 827 ACCDetObjTyp 0 "ACCDetObjTyp_Unknown" 1 "ACCDetObjTyp_Car" 2 "ACCDetObjTyp_Truck" 3 "ACCDetObjTyp_Motorbike" 4 "ACCDetObjTyp_Bicycle" 5 "ACCDetObjTyp_5_Reserved" 6 "ACCDetObjTyp_6_Reserved" 7 "ACCDetObjTyp_7_Reserved";
VAL_ 826 ACCDetObj1Risk 0 "ACCDetObj1Risk_0_NoRisk" 1 "ACCDetObj1Risk_1_RiskExist";
VAL_ 826 ACCDetObj1Typ 0 "ACCDetObj1Typ_Unknown" 1 "ACCDetObj1Typ_Car" 2 "ACCDetObj1Typ_Truck" 3 "ACCDetObj1Typ_Motorbike" 4 "ACCDetObj1Typ_Bicycle" 5 "ACCDetObj1Typ_5_Reserved" 6 "ACCDetObj1Typ_6_Reserved" 7 "ACCDetObj1Typ_7_Reserved";
VAL_ 825 ACCDetObj2Risk 0 "ACCDetObj2Risk_0_NoRisk" 1 "ACCDetObj2Risk_1_RiskExist";
VAL_ 825 ACCDetObj2Typ 0 "ACCDetObj2Typ_Unknown" 1 "ACCDetObj2Typ_Car" 2 "ACCDetObj2Typ_Truck" 3 "ACCDetObj2Typ_Motorbike" 4 "ACCDetObj2Typ_Bicycle" 5 "ACCDetObj2Typ_5_Reserved" 6 "ACCDetObj2Typ_6_Reserved" 7 "ACCDetObj2Typ_7_Reserved";
VAL_ 824 ACCDetObj3Risk 0 "ACCDetObj3Risk_0_NoRisk" 1 "ACCDetObj3Risk_1_RiskExist";
VAL_ 824 ACCDetObj3Typ 0 "ACCDetObj3Typ_Unknown" 1 "ACCDetObj3Typ_Car" 2 "ACCDetObj3Typ_Truck" 3 "ACCDetObj3Typ_Motorbike" 4 "ACCDetObj3Typ_Bicycle" 5 "ACCDetObj3Typ_5_Reserved" 6 "ACCDetObj3Typ_6_Reserved" 7 "ACCDetObj3Typ_7_Reserved";
VAL_ 466 AEBDspCmd 0 "AEBDspCmd_0_unavailable" 1 "AEBDspCmd_1_off" 2 "AEBDspCmd_2_on" 3 "AEBDspCmd_3_reserved";
VAL_ 466 AEBMsgReq 0 "AEBMsgReq_No_display" 1 "AEBMsgReq_unable_to_active_AEB" 2 "AEBMsgReq_2_Active" 3 "AEBMsgReq_AEB_is_in_error_mode" 4 "AEBMsgReq_AEB_is_switched_on" 5 "AEBMsgReq_AEB_is_switched_off" 6 "AEBMsgReq_Radar_Error" 7 "AEBMsgReq_7_reserved";
VAL_ 466 FCWDspCmd 0 "FCWDspCmd_unavailable" 1 "FCWDspCmd_off" 2 "FCWDspCmd_on" 3 "FCWDspCmd_reserved";
VAL_ 466 FCWSnstvtLvl 0 "FCWSnstvtLvl_Unavailable" 1 "FCWSnstvtLvl_level1" 2 "FCWSnstvtLvl_level2" 3 "FCWSnstvtLvl_level3" 4 "FCWSnstvtLvl_reserved1" 5 "FCWSnstvtLvl_reserved2" 6 "FCWSnstvtLvl_reserved3" 7 "FCWSnstvtLvl_reserved4";
VAL_ 466 FCWSysFltSts 0 "FCWSysFltSts_No_error" 1 "FCWSysFltSts_Performance_degradation" 2 "FCWSysFltSts_System_temporary_unvailable" 3 "FCWSysFltSts_Service_required" 4 "FCWSysFltSts_Reserved1" 5 "FCWSysFltSts_Reserved2" 6 "FCWSysFltSts_Reserved3" 7 "FCWSysFltSts_Reserved4";
VAL_ 466 FCWWrnngSts 0 "FCWWrnngSts_no_request" 1 "FCWWrnngSts_level_1" 2 "FCWWrnngStsr_level_2" 3 "FCWWrnngSts_level_3" 4 "FCWWrnngSts_reserved1" 5 "FCWWrnngSts_reserved2" 6 "FCWWrnngSts_reserved3" 7 "FCWWrnngSts_reserved4";
VAL_ 523 ACCDetObjDistLvl 0 "ACCDetObjDistLvl_no_gap_set" 1 "ACCDetObjDistLvl_distance_level1" 2 "ACCDetObjDistLvl_distance_level2" 3 "ACCDetObjDistLvl_distance_level3" 4 "ACCDetObjDistLvl_reserved1" 5 "ACCDetObjDistLvl_reserved2" 6 "ACCDetObjDistLvl_reserved3" 7 "ACCDetObjDistLvl_reserved4";
VAL_ 523 ACCDrvrSeldTrgtDistLvl 0 "ACCDrvrSeldTrgtDistLvl_no_gap_set" 1 "ACCDrvrSeldTrgtDistLvl_distance_level1" 2 "ACCDrvrSeldTrgtDistLvl_distance_level2" 3 "ACCDrvrSeldTrgtDistLvl_distance_level3" 4 "ACCDrvrSeldTrgtDistLvl_reserved1" 5 "ACCDrvrSeldTrgtDistLvl_reserved2" 6 "ACCDrvrSeldTrgtDistLvl_reserved3" 7 "ACCDrvrSeldTrgtDistLvl_reserved4";
VAL_ 523 ACCDrvrTkovReq 0 "False" 1 "True";
VAL_ 523 ACCGoNotfr 0 "False" 1 "True";
VAL_ 523 ACCMsgReq 0 "ACCMsgReq_0_No_display" 1 "ACCMsgReq_1_Reserve" 2 "ACCMsgReq_2_Reserve" 3 "ACCMsgReq_3_Reserve" 4 "ACCMsgReq_4_Reserve" 5 "ACCMsgReq_5_Reserve" 6 "ACCMsgReq_6_Reserve" 7 "ACCMsgReq_7_Reserve" 8 "ACCMsgReq_8_Reserve" 9 "ACCMsgReq_9_Reserve" 10 "ACCMsgReq_10_Engine_not_in_running_state_or_EPT_not_ready" 11 "ACCMsgReq_11_EPB_applied" 12 "ACCMsgReq_12_shift_is_not_in_D" 13 "ACCMsgReq_13_door_or_bonnet_is_open" 14 "ACCMsgReq_14_Driver_Seatbelt_released" 15 "ACCMsgReq_15_Driver_mode_not_spport";
VAL_ 523 ACCObjDet 0 "False" 1 "True";
VAL_ 523 ACCSysCanclReq 0 "ACCSysCanclReq_Radar_No_Cancel" 1 "ACCSysCanclReq_Radar_Manual_Cancel" 2 "ACCSysCanclReq_Radar_ACC_Condition_Dissatisfy" 3 "ACCSysCanclReq_Radar_3_Reserved";
VAL_ 523 RdrCalPrgsReq 0 "RdrCalPrgsReq_no_request" 1 "RdrCalPrgsReq_Calibration_Started" 2 "RdrCalPrgsReq_Calibration_in_progress" 3 "RdrCalPrgsReq_Calibration_Finished_Succesful" 4 "RdrCalPrgsReq_Calibration_Finished_need_Adjust" 5 "RdrCalPrgsReq_calibration_failure";
VAL_ 988 Obj0Risk 0 "Obj0Risk_0_NoRisk" 1 "Obj0Risk_1_RiskExist";
VAL_ 988 Obj0Typ 0 "Obj0Typ_0_Unknown" 1 "Obj0Typ_1_Car" 2 "Obj0Typ_2_Truck" 3 "Obj0Typ_3_Motorbike" 4 "Obj0Typ_4_Bicycle" 5 "Obj0Typ_5_Reserved" 6 "Obj0Typ_6_Reserved" 7 "Obj0Typ_7_Reserved";
VAL_ 981 Obj1Risk 0 "Obj1Risk_0_NoRisk" 1 "Obj1Risk_1_RiskExist";
VAL_ 981 Obj1Typ 0 "Obj1Typ_0_Unknown" 1 "Obj1Typ_1_Car" 2 "Obj1Typ_2_Truck" 3 "Obj1Typ_3_Motorbike" 4 "Obj1Typ_4_Bicycle" 5 "Obj1Typ_5_Reserved" 6 "Obj1Typ_6_Reserved" 7 "Obj1Typ_7_Reserved";
VAL_ 983 Obj2Risk 0 "Obj2Risk_0_NoRisk" 1 "Obj2Risk_1_RiskExist";
VAL_ 983 Obj2Typ 0 "Obj2Typ_0_Unknown" 1 "Obj2Typ_1_Car" 2 "Obj2Typ_2_Truck" 3 "Obj2Typ_3_Motorbike" 4 "Obj2Typ_4_Bicycle" 5 "Obj2Typ_5_Reserved" 6 "Obj2Typ_6_Reserved" 7 "Obj2Typ_7_Reserved";
VAL_ 986 Obj3Risk 0 "Obj3Risk_0_NoRisk" 1 "Obj3Risk_1_RiskExist";
VAL_ 986 Obj3Typ 0 "Obj3Typ_0_Unknown" 1 "Obj3Typ_1_Car" 2 "Obj3Typ_2_Truck" 3 "Obj3Typ_3_Motorbike" 4 "Obj3Typ_4_Bicycle" 5 "Obj3Typ_5_Reserved" 6 "Obj3Typ_6_Reserved" 7 "Obj3Typ_7_Reserved";
SIG_GROUP_ 404 CCP_025ms_ECM_PDU04 1 : AutocTrCmddGear CCP_025ms_ECM_PDU04_CRC CCP_025ms_ECM_PDU04_RC CCP_025ms_ECM_PDU04_Reserve01 CCP_025ms_ECM_PDU04_Reserve02 CCP_025ms_ECM_PDU04_Reserve03 CCP_025ms_ECM_PDU04_Reserve04 CCP_025ms_ECM_PDU04_Reserve05 ClPos ClPosV ClStSwA ClStSwAV DrvrShftCtrlTrgtGear TrEstdGear TrEstdGearV TrShftLvrPos TrShftLvrPosV TrShftPtrnASts TrTapUpTapDwnMdSts;
SIG_GROUP_ 85 EPS_010ms_PDU00 1 : EPS_010ms_PDU00_CRC EPS_010ms_PDU00_RC EPS_010ms_PDU00_Reserve01 StrgWhlAng StrgWhlAngGrd StrgWhlAngSnsrCalSts StrgWhlAngSnsrFlt StrgWhlAngSnsrInid StrgWhlAngSnsrMultCapb StrgWhlAngV;
SIG_GROUP_ 537 IPK_050ms_PDU31 1 : ADASDspdErInHMI ADASErDetcByHMI IPK_050ms_PDU31_CRC IPK_050ms_PDU31_RC IPK_050ms_PDU31_Reserve01 IPK_050ms_PDU31_Reserve02;
SIG_GROUP_ 1345 IPK_CFCAN_FrP06 1 : CalendarDay CalendarMonth CalendarYear HourOfDay IPK_200ms_PDU06_CRC IPK_200ms_PDU06_RC IPK_200ms_PDU06_Reserve01 IPK_200ms_PDU06_Reserve02 IPK_200ms_PDU06_Reserve03 IPK_200ms_PDU06_Reserve04 IPK_200ms_PDU06_Reserve05 MinuteOfHour SecsOfMinute TimeDspFmt;
SIG_GROUP_ 817 IPK_CFCAN_FrP07 1 : ClstrCardDspMd ClstrDimLghtLvl ClstrThemeTyp IPCEcoDrvngSwA IPK_100ms_PDU07_CRC IPK_100ms_PDU07_RC IPK_100ms_PDU07_Reserve02 ParkBrkSwA;
